VERSION ""

NS_ :

BS_:

BU_:

BO_ 70 AutoBrkSysMnPriInfo1_Prtctd_PDU: 20 Vector__XXX
 SG_ ABSMPI1P_MAC : 7|32@0+ (1,0) [0|4.29497e+009] "" ADIMa,ADIMb,ECP_E
 SG_ ABSMPI1P_FCnt : 39|5@0+ (1,0) [0|31] "" ADIMa,ADIMb,ECP_E
 SG_ ABSMPI1P_BrkModStsAuth : 41|2@0+ (1,0) [0|3] "" ADIMa,ADIMb,ECP_E
 SG_ ABSMPI1P_FillerExtnd : 42|1@0+ (1,0) [0|1] "" ADIMa,ADIMb,ECP_E
 SG_ ABSMPI1P_ADIMCmdMsgStsAuth : 45|3@0+ (1,0) [0|4] "" ADIMa,ADIMb,ECP_E
 SG_ ABSMPI1P_ABSStsAuth : 47|2@0+ (1,0) [0|3] "" ADIMa,ADIMb,ECP_E
 SG_ ABSMPI1P_DiagBrkPresReqStsAuth : 49|3@0+ (1,0) [0|4] "" ADIMa,ADIMb,ECP_E
 SG_ ABSMPI1P_DiagBrkPresReqAvalAuth : 51|2@0+ (1,0) [0|2] "" ADIMa,ADIMb,ECP_E
 SG_ ABSMPI1P_BrkTrqSfcntStndstlAuth : 52|1@0+ (1,0) [0|1] "" ADIMa,ADIMb,VICM,ECP_E
 SG_ ABSMPI1P_BrkSysStsAuth : 55|3@0+ (1,0) [0|6] "" ADIMa,ADIMb,ECP_E
 SG_ ABSMPI1P_EstdSrfcFCoefCapAuth : 58|8@0+ (0.006,0) [0|1.53] "Mu" ADIMa,ADIMb,ECP_E
 SG_ ABSMPI1P_ElecBrkDstSysStsAuth : 60|2@0+ (1,0) [0|3] "" ADIMa,ADIMb,ECP_E
 SG_ ABSMPI1P_ESCSysStsAuth : 62|2@0+ (1,0) [0|3] "" ADIMa,ADIMb,ECP_E
 SG_ ABSMPI1P_MxAvlBrkTqAuth : 64|14@0+ (2,-32766) [-32766|0] "Nm" ADIMa,ADIMb,ECP_E
 SG_ ABSMPI1P_EstdSrfcFCoefTypAuth : 66|2@0+ (1,0) [0|3] "" ADIMa,ADIMb,ECP_E
 SG_ ABSMPI1P_MxAvlBrkTqGradAuth : 82|12@0+ (100,-409500) [-409500|0] "Nm/s" ADIMa,ADIMb,ECP_E
 SG_ ABSMPI1P_PBMSbsysStsPriAuth : 98|3@0+ (1,0) [0|6] "" ADIMa,ADIMb,ECP_E
 SG_ ABSMPI1P_PBMArbtrtnStsPriAuth : 102|4@0+ (1,0) [0|10] "" ADIMa,ADIMb,ECP_E
 SG_ ABSMPI1P_WhlBrkPresAuth_Inv : 104|1@0+ (1,0) [0|1] "" ADIMa,ADIMb,ECP_E
 SG_ ABSMPI1P_TCSStsAuth : 106|2@0+ (1,0) [0|3] "" ADIMa,ADIMb,ECP_E
 SG_ ABSMPI1P_StndstlHldReqStsAuth : 108|2@0+ (1,0) [0|2] "" ADIMa,ADIMb,ECP_E
 SG_ ABSMPI1P_SpltFCoefCtlAuth : 110|2@0+ (1,0) [0|2] "" ADIMa,ADIMb,ECP_E
 SG_ ABSMPI1P_SBMFltDtdByPBMPriAuth : 111|1@0+ (1,0) [0|1] "" ADIMa,ADIMb,ECP_E
 SG_ ABSMPI1P_WhlBrkPresLFAuth : 119|8@0+ (100,0) [0|25500] "kPa" ADIMa,ADIMb,ECP_E
 SG_ ABSMPI1P_WhlBrkPresLRAuth : 127|8@0+ (100,0) [0|25500] "kPa" ADIMa,ADIMb,ECP_E
 SG_ ABSMPI1P_WhlBrkPresRFAuth : 135|8@0+ (100,0) [0|25500] "kPa" ADIMa,ADIMb,ECP_E
 SG_ ABSMPI1P_WhlBrkPresRRAuth : 143|8@0+ (100,0) [0|25500] "kPa" ADIMa,ADIMb,ECP_E
 SG_ ABSMPI1P_Filler : 146|11@0+ (1,0) [0|2047] "" ADIMa,ADIMb,ECP_E
 SG_ MnElecPrkBrkSwStsPriAuth : 149|3@0+ (1,0) [0|5] "" ADIMa,ADIMb,ECP_E
 SG_ ABSMPI1P_ARC : 151|2@0+ (1,0) [0|3] "" ADIMa,ADIMb,ECP_E

BO_ 699 AutoBrkSysRedntPriInfo1_PCSM_PDU: 8 Vector__XXX
 SG_ AutoBrkSysRedntPriInfo1_PCSM : 7|64@0+ (1,0) [0|1.84467e+019] "" EBCM,ECP_E

BO_ 78 AutoBrkSysRedntPriInfo1_Prtctd_P: 48 Vector__XXX
 SG_ ABSRPI1P_MAC : 7|32@0+ (1,0) [0|4.29497e+009] "" EBCM,ECP_E
 SG_ ABSRPI1P_FCnt : 39|5@0+ (1,0) [0|31] "" EBCM,ECP_E
 SG_ ABSRPI1P_BrkModStsAuth : 41|2@0+ (1,0) [0|3] "" EBCM,ECP_E
 SG_ ABSRPI1P_FillerExtnd3 : 42|1@0+ (1,0) [0|1] "" EBCM,ECP_E
 SG_ ABSRPI1P_ADIMCmdMsgStsAuth : 45|3@0+ (1,0) [0|4] "" EBCM,ECP_E
 SG_ ABSRPI1P_ABSStsAuth : 47|2@0+ (1,0) [0|3] "" EBCM,ECP_E
 SG_ ABSRPI1P_CSImmedATRqValAuth : 50|15@0+ (2,-22534) [-22534|43000] "Nm" EBCM,ECP_E
 SG_ ABSRPI1P_BrkTrqSfcntStndstlAuth : 51|1@0+ (1,0) [0|1] "" EBCM,ECP_E
 SG_ ABSRPI1P_BrkSysStsAuth : 54|3@0+ (1,0) [0|6] "" EBCM,ECP_E
 SG_ ABSRPI1P_BrkSysBrkLgtsReqdAuth : 55|1@0+ (1,0) [0|1] "" EBCM,ECP_E
 SG_ ABSRPI1P_CSPrdtdATRqValAuth : 65|15@0+ (2,-22534) [-22534|43000] "Nm" EBCM,ECP_E
 SG_ ABSRPI1P_CSPrdtdATRqIntvTypAuth : 67|2@0+ (1,0) [0|3] "" EBCM,ECP_E
 SG_ ABSRPI1P_ChsSysATRqFncAuth : 82|4@0+ (1,0) [0|14] "" EBCM,ECP_E
 SG_ ABSRPI1P_ChsSysBrkBlndATRqAuth : 91|12@0+ (2,0) [0|8190] "Nm" EBCM,ECP_E
 SG_ ABSRPI1P_ChsSysATRqRespTypAuth : 94|3@0+ (1,0) [0|4] "" EBCM,ECP_E
 SG_ ABSRPI1P_ChsSysTtBrkATAuth : 111|14@0+ (2,0) [0|32766] "Nm" EBCM,ECP_E
 SG_ ABSRPI1P_DrvIntdTtBrkTqAuth : 112|14@0+ (2,0) [0|32766] "Nm" EBCM,ECP_E
 SG_ ABSRPI1P_ChsSysTtBrkATAuth_Inv : 113|1@0+ (1,0) [0|1] "" EBCM,ECP_E
 SG_ ABSRPI1P_ElcBrkDstSysStsAuth : 128|2@0+ (1,0) [0|3] "" EBCM,ECP_E
 SG_ ABSRPI1P_ESCSysStsAuth : 130|2@0+ (1,0) [0|3] "" EBCM,ECP_E
 SG_ ABSRPI1P_EstdSrfcFCoefCapAuth : 142|8@0+ (0.006,0) [0|1.53] "Mu" EBCM,ECP_E
 SG_ ABSRPI1P_MxAvlBrkTqAuth : 148|14@0+ (2,-32766) [-32766|0] "Nm" EBCM,ECP_E
 SG_ ABSRPI1P_EstdSrfcFCoefTypAuth : 150|2@0+ (1,0) [0|3] "" EBCM,ECP_E
 SG_ ABSRPI1P_MxAvlBrkTqGradAuth : 166|12@0+ (100,-409500) [-409500|0] "Nm/s" EBCM,ECP_E
 SG_ ABSRPI1P_SBMArbtrtnStsPriAuth : 169|4@0+ (1,0) [0|8] "" EBCM,ECP_E
 SG_ ABSRPI1P_PBMFltDtdBySBMPriAuth : 170|1@0+ (1,0) [0|1] "" EBCM,ECP_E
 SG_ ABSRPI1P_StndstlHldRqStsAuth : 176|2@0+ (1,0) [0|2] "" EBCM,ECP_E
 SG_ ABSRPI1P_SpltFCoefCtlAuth : 178|2@0+ (1,0) [0|2] "" EBCM,ECP_E
 SG_ ABSRPI1P_SBMSbsysStsPriAuth : 181|3@0+ (1,0) [0|5] "" EBCM,ECP_E
 SG_ ABSRPI1P_WhlAnglrVelLFAuth : 188|14@0+ (0.004,0) [0|65.532] "Revolutions Per Second" EBCM,ECP_E
 SG_ ABSRPI1P_TCSStsAuth : 190|2@0+ (1,0) [0|3] "" EBCM,ECP_E
 SG_ ABSRPI1P_WhlAnglrVelLRAuth : 205|14@0+ (0.004,0) [0|65.532] "Revolutions Per Second" EBCM,ECP_E
 SG_ ABSRPI1P_WhlAnglrVelLFAuth_Inv : 206|1@0+ (1,0) [0|1] "" EBCM,ECP_E
 SG_ ABSRPI1P_WhlAnglrVelRFAuth : 222|14@0+ (0.004,0) [0|65.532] "Revolutions Per Second" EBCM,ECP_E
 SG_ ABSRPI1P_WhlAnglrVelLRAuth_Inv : 223|1@0+ (1,0) [0|1] "" EBCM,ECP_E
 SG_ ABSRPI1P_WhlAnglrVelRFAuth_Inv : 224|1@0+ (1,0) [0|1] "" EBCM,ECP_E
 SG_ ABSRPI1P_WhlAnglrVelRRAuth : 239|14@0+ (0.004,0) [0|65.532] "Revolutions Per Second" EBCM,ECP_E
 SG_ ABSRPI1P_WhlBrkPrsLFAuth : 240|8@0+ (100,0) [0|25500] "kPa" EBCM,ECP_E
 SG_ ABSRPI1P_WhlAnglrVelRRAuth_Inv : 241|1@0+ (1,0) [0|1] "" EBCM,ECP_E
 SG_ ABSRPI1P_WhlBrkPrsLFAuth_Inv : 248|1@0+ (1,0) [0|1] "" EBCM,ECP_E
 SG_ ABSRPI1P_WhlBrkPrsLRAuth : 263|8@0+ (100,0) [0|25500] "kPa" EBCM,ECP_E
 SG_ ABSRPI1P_WhlBrkPrsRFAuth : 270|8@0+ (100,0) [0|25500] "kPa" EBCM,ECP_E
 SG_ ABSRPI1P_WhlBrkPrsLRAuth_Inv : 271|1@0+ (1,0) [0|1] "" EBCM,ECP_E
 SG_ ABSRPI1P_WhlBrkPrsRRAuth : 277|8@0+ (100,0) [0|25500] "kPa" EBCM,ECP_E
 SG_ ABSRPI1P_WhlBrkPrsRFAuth_Inv : 278|1@0+ (1,0) [0|1] "" EBCM,ECP_E
 SG_ ABSRPI1P_Filler : 282|32@0+ (1,0) [0|4.29497e+009] "" EBCM,ECP_E
 SG_ ABSRPI1P_ARC : 284|2@0+ (1,0) [0|3] "" EBCM,ECP_E
 SG_ ABSRPI1P_WhlBrkPrsRRAuth_Inv : 285|1@0+ (1,0) [0|1] "" EBCM,ECP_E
 SG_ ABSRPI1P_FillerExtnd : 314|32@0+ (1,0) [0|4.29497e+009] "0" EBCM,ECP_E
 SG_ ABSRPI1P_FillerExtnd1 : 346|32@0+ (1,0) [0|4.29497e+009] "" EBCM,ECP_E
 SG_ ABSRPI1P_FillerExtnd2 : 378|3@0+ (1,0) [0|7] "" EBCM,ECP_E

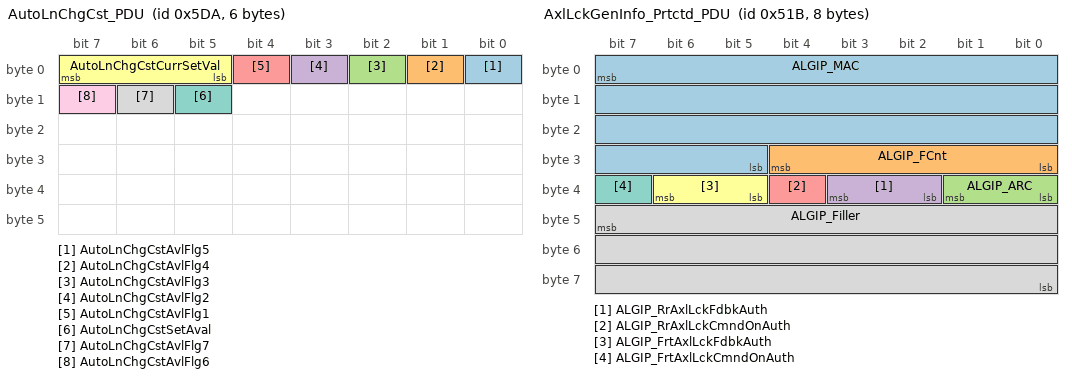
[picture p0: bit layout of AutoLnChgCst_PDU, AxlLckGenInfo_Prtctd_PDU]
BO_ 1498 AutoLnChgCst_PDU: 6 Vector__XXX
 SG_ AutoLnChgCstAvlFlg5 : 0|1@0+ (1,0) [0|1] "" CGM
 SG_ AutoLnChgCstAvlFlg4 : 1|1@0+ (1,0) [0|1] "" CGM
 SG_ AutoLnChgCstAvlFlg3 : 2|1@0+ (1,0) [0|1] "" CGM
 SG_ AutoLnChgCstAvlFlg2 : 3|1@0+ (1,0) [0|1] "" CGM
 SG_ AutoLnChgCstAvlFlg1 : 4|1@0+ (1,0) [0|1] "" CGM
 SG_ AutoLnChgCstCurrSetVal : 7|3@0+ (1,0) [0|4] "" CGM
 SG_ AutoLnChgCstSetAval : 13|1@0+ (1,0) [0|1] "" CGM
 SG_ AutoLnChgCstAvlFlg7 : 14|1@0+ (1,0) [0|1] "" CGM
 SG_ AutoLnChgCstAvlFlg6 : 15|1@0+ (1,0) [0|1] "" CGM

BO_ 698 AutoVehMtnCtlMnInfo1_PCSM_PDU: 8 Vector__XXX
 SG_ AutoVehMtnCtlMnInfo1_PCSM : 7|64@0+ (1,0) [0|1.84467e+019] "" VICM,EBCM,EPSRAa,FOPM,ECP_E

BO_ 68 AutoVehMtnCtlMnInfo1_Prtctd_PDU: 24 Vector__XXX
 SG_ AVMCMI1P_MAC : 7|32@0+ (1,0) [0|4.29497e+009] "" VICM,CGM,EBCM,EPSRAa,FOPM,ECP_E
 SG_ AVMCMI1P_FCnt : 39|5@0+ (1,0) [0|31] "" VICM,CGM,EBCM,EPSRAa,FOPM,ECP_E
 SG_ AVMCMI1P_AutoCtlBrkTqRqAuth : 46|15@0+ (1,-32767) [-32767|0] "Nm" VICM,CGM,EBCM,EPSRAa,FOPM,ECP_E
 SG_ AVMCMI1P_ADSRedntIPSPwrdOnAuth : 47|1@0+ (1,0) [0|1] "" VICM,CGM,EBCM,EPSRAa,FOPM,ECP_E
 SG_ AVMCMI1P_AutoCtlRqAngVlAuth : 63|15@0- (0.0625,0) [-1024|1023.94] "deg" VICM,CGM,EBCM,EPSRAa,FOPM,ECP_E
 SG_ AVMCMI1P_AutoCtlRqStrgModeAuth : 64|1@0+ (1,0) [0|1] "" VICM,CGM,EBCM,EPSRAa,FOPM,ECP_E
 SG_ AVMCMI1P_AutoVehOprtlStatAuth : 72|4@0+ (1,0) [0|7] "" VICM,CGM,EBCM,EPSRAa,FOPM,ECP_E
 SG_ AVMCMI1P_AutoTransRngRqAuth : 75|3@0+ (1,0) [0|4] "" VICM,CGM,EBCM,EPSRAa,FOPM,ECP_E
 SG_ AVMCMI1P_AutoCtlrEPBRqAuth : 77|2@0+ (1,0) [0|2] "" VICM,CGM,EBCM,EPSRAa,FOPM,ECP_E
 SG_ AVMCMI1P_AutoCtlrBrkTqRqTypAuth : 79|2@0+ (1,0) [0|2] "" VICM,CGM,EBCM,EPSRAa,FOPM,ECP_E
 SG_ AVMCMI1P_DgWhlBrkPrsRqLFAuth : 84|11@0+ (10,0) [0|20470] "kPa" VICM,CGM,EBCM,EPSRAa,FOPM,ECP_E
 SG_ AVMCMI1P_DgWhlBrkPrsRqLRAuth : 89|11@0+ (10,0) [0|20470] "kPa" VICM,CGM,EBCM,EPSRAa,FOPM,ECP_E
 SG_ AVMCMI1P_DgWhlBrkPrsRqRFAuth : 110|11@0+ (10,0) [0|20470] "kPa" VICM,CGM,EBCM,EPSRAa,FOPM,ECP_E
 SG_ AVMCMI1P_DgWhlBrkPrsRqRRAuth : 115|11@0+ (10,0) [0|20470] "kPa" VICM,CGM,EBCM,EPSRAa,FOPM,ECP_E
 SG_ AVMCMI1P_DgWhlBrkPrsRqTgtAuth : 120|2@0+ (1,0) [0|2] "" VICM,CGM,EBCM,EPSRAa,FOPM,ECP_E
 SG_ AVMCMI1P_MnAutoAxlTrqRqAuth : 131|15@0+ (2,-22534) [-22534|43000] "Nm" VICM,CGM,EBCM,EPSRAa,FOPM,ECP_E
 SG_ AVMCMI1P_FailOprtlPwrAvSTRqAuth : 134|3@0+ (1,0) [0|3] "" VICM,CGM,EBCM,EPSRAa,FOPM,ECP_E
 SG_ AVMCMI1P_Filler : 144|32@0+ (1,0) [0|4.29497e+009] "" VICM,CGM,EBCM,EPSRAa,FOPM,ECP_E
 SG_ AVMCMnFAXVCEqpdStsPriAuth : 146|2@0+ (1,0) [0|3] "" VICM,CGM,EBCM,EPSRAa,FOPM,ECP_E
 SG_ AVMCMI1P_ARC : 148|2@0+ (1,0) [0|3] "" VICM,CGM,EBCM,EPSRAa,FOPM,ECP_E
 SG_ AVMCMI1P_FillerExtnd : 176|9@0+ (1,0) [0|511] "" VICM,CGM,EBCM,EPSRAa,FOPM,ECP_E

BO_ 1367 AxlLckGenInfo_PCSM_PDU: 8 Vector__XXX
 SG_ AxlLckGenInfo_PCSM : 7|64@0+ (1,0) [0|1.84467e+019] "" ECP_E

BO_ 1307 AxlLckGenInfo_Prtctd_PDU: 8 Vector__XXX
 SG_ ALGIP_MAC : 7|27@0+ (1,0) [0|1.34218e+008] "" ECP_E
 SG_ ALGIP_FCnt : 28|5@0+ (1,0) [0|31] "" ECP_E
 SG_ ALGIP_ARC : 33|2@0+ (1,0) [0|3] "" ECP_E
 SG_ ALGIP_RrAxlLckFdbkAuth : 35|2@0+ (1,0) [0|2] "" TCCM,ECP_E
 SG_ ALGIP_RrAxlLckCmndOnAuth : 36|1@0+ (1,0) [0|1] "" TCCM,ECP_E
 SG_ ALGIP_FrtAxlLckFdbkAuth : 38|2@0+ (1,0) [0|2] "" TCCM,ECP_E
 SG_ ALGIP_FrtAxlLckCmndOnAuth : 39|1@0+ (1,0) [0|1] "" TCCM,ECP_E
 SG_ ALGIP_Filler : 47|24@0+ (1,0) [0|1.67772e+007] "" ECP_E

BO_ 2147745799 Message0034_PDU: 1 Vector__XXX
 SG_ Sig0522 : 7|1@0+ (1,0) [0|1] "" CGM

BO_ 1255 Message0035_PDU: 6 Vector__XXX
 SG_ Sig3627 : 7|8@0+ (0.392157,0) [0|100] "" ECM,PCM

BO_ 2147745812 Message0037_PDU: 1 Vector__XXX
 SG_ Sig0524 : 7|1@0+ (1,0) [0|1] "" CGM

BO_ 459 BSM_NM_PDU_On_CAN_2_Cluster: 8 Vector__XXX
 SG_ ISignal_BSM_CAN_2_Cluster : 23|48@0+ (1,0) [0|281474976710655] "" ACP2_MCU,ADIMa,ADIMb,AHL_AFL,AHS,ARS,VECM,VICM,BSM_MH,CGM,DCM,DMS,EBCM,ECM,ECP_MC,EOCM,EOCM_HC_Superset,EPSRAa,EPS,EPSb,FCM,FOPM,HUD_CAN,LIB1,NVM,E44,PCM,RDCM,TCCM,TCM,VDM,ECP_E,ECP_S,ECP_S2,ECP_X1

BO_ 923 BdyGenInfo3_PCSM_PDU: 8 Vector__XXX
 SG_ BdyGenInfo3_PCSM : 7|64@0+ (1,0) [0|1.84467e+019] "" ACP2_MCU,ECM,EOCM,EOCM_HC_Superset,EPS,EPSb,FCM,PCM,RDCM,TCCM

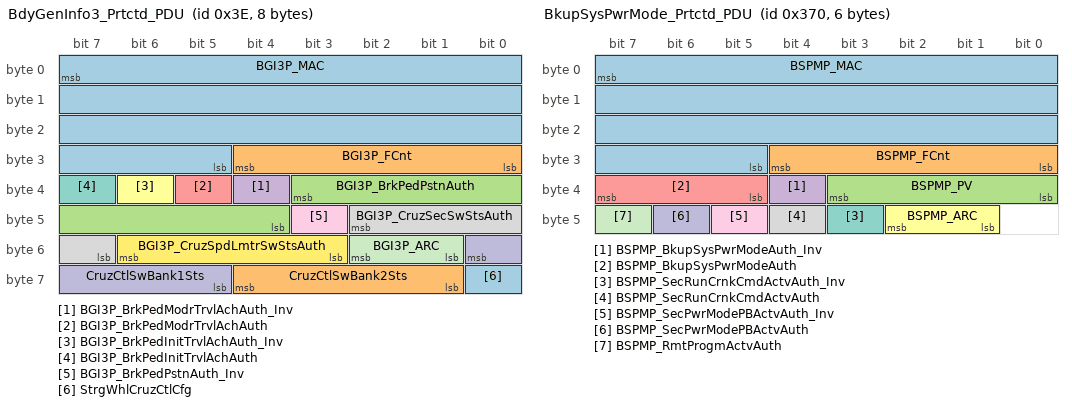
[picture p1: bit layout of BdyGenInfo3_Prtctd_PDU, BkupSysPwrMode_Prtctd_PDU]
BO_ 62 BdyGenInfo3_Prtctd_PDU: 8 Vector__XXX
 SG_ BGI3P_MAC : 7|27@0+ (1,0) [0|1.34218e+008] "" ACP2_MCU,ECM,EOCM,EOCM_HC_Superset,EPS,EPSb,FCM,PCM,RDCM,TCCM
 SG_ BGI3P_FCnt : 28|5@0+ (1,0) [0|31] "" ACP2_MCU,ECM,EOCM,EOCM_HC_Superset,EPS,EPSb,FCM,PCM,RDCM,TCCM
 SG_ BGI3P_BrkPedPstnAuth : 35|8@0+ (0.392157,0) [0|100] "%" ACP2_MCU,ADIMa,ADIMb,AHL_AFL,EBCM,ECM,EOCM,EOCM_HC_Superset,EPS,EPSb,FCM,E44,PCM,RDCM,TCCM,TCM
 SG_ BGI3P_BrkPedModrTrvlAchAuth_Inv : 36|1@0+ (1,0) [0|1] "" ACP2_MCU,ECM,EOCM,EOCM_HC_Superset,EPS,EPSb,FCM,PCM,RDCM,TCCM,TCM
 SG_ BGI3P_BrkPedModrTrvlAchAuth : 37|1@0+ (1,0) [0|1] "" ACP2_MCU,ECM,EOCM,EOCM_HC_Superset,EPS,EPSb,FCM,PCM,RDCM,TCCM,TCM
 SG_ BGI3P_BrkPedInitTrvlAchAuth_Inv : 38|1@0+ (1,0) [0|1] "" ACP2_MCU,BSM,DCM,EBCM,ECM,EOCM,EOCM_HC_Superset,EPS,EPSb,FCM,PCM,RDCM,TCCM,TCM
 SG_ BGI3P_BrkPedInitTrvlAchAuth : 39|1@0+ (1,0) [0|1] "" ACP2_MCU,BSM,EBCM,ECM,EOCM,EOCM_HC_Superset,EPS,EPSb,FCM,PCM,RDCM,TCCM,TCM
 SG_ BGI3P_CruzSecSwStsAuth : 42|4@0+ (1,0) [0|9] "" ACP2_MCU,ECM,EOCM,EOCM_HC_Superset,EPS,EPSb,FCM,PCM,RDCM,TCCM
 SG_ BGI3P_BrkPedPstnAuth_Inv : 43|1@0+ (1,0) [0|1] "" ACP2_MCU,ADIMa,ADIMb,AHL_AFL,EBCM,ECM,EOCM,EOCM_HC_Superset,EPS,EPSb,FCM,E44,PCM,RDCM,TCCM,TCM
 SG_ CruzCtlSwBank1Sts : 48|4@0+ (1,0) [0|9] "" ACP2_MCU,EBCM,ECM,EOCM,EOCM_HC_Superset,EPS,EPSb,FCM,PCM,RDCM,TCCM
 SG_ BGI3P_ARC : 50|2@0+ (1,0) [0|3] "" ACP2_MCU,ECM,EOCM,EOCM_HC_Superset,EPS,EPSb,FCM,PCM,RDCM,TCCM
 SG_ BGI3P_CruzSpdLmtrSwStsAuth : 54|4@0+ (1,0) [0|9] "" ACP2_MCU,EBCM,ECM,EOCM,EOCM_HC_Superset,EPS,EPSb,FCM,PCM,RDCM,TCCM
 SG_ StrgWhlCruzCtlCfg : 56|1@0+ (1,0) [0|1] "" ACP2_MCU,EBCM,ECM,EOCM,EOCM_HC_Superset,EPS,EPSb,FCM,PCM,RDCM,TCCM
 SG_ CruzCtlSwBank2Sts : 60|4@0+ (1,0) [0|10] "" ACP2_MCU,ECM,EOCM,EOCM_HC_Superset,EPS,EPSb,FCM,PCM,RDCM,TCCM

BO_ 1405 BkupSysPwrMode_PCSM_PDU: 8 Vector__XXX
 SG_ BkupSysPwrMode_PCSM : 7|64@0+ (1,0) [0|1.84467e+019] "" ADIMa,AHL_AFL,AHS,ARS,VECM,VICM,BSM_MH,DCM,DMS,ECP_MC,EPSRAa,EPS,EPSb,FCM,LIB1,PCM,RDCM,TCCM,TCM,ECP_E,ECP_S,ECP_S2

BO_ 880 BkupSysPwrMode_Prtctd_PDU: 6 Vector__XXX
 SG_ BSPMP_MAC : 7|27@0+ (1,0) [0|1.34218e+008] "" ADIMa,AHL_AFL,AHS,ARS,VECM,VICM,BSM_MH,DCM,DMS,ECP_MC,EPSRAa,EPS,EPSb,FCM,LIB1,PCM,RDCM,TCCM,TCM,ECP_E,ECP_S,ECP_S2
 SG_ BSPMP_FCnt : 28|5@0+ (1,0) [0|31] "" ADIMa,AHL_AFL,AHS,ARS,VECM,VICM,BSM_MH,DCM,DMS,ECP_MC,EPSRAa,EPS,EPSb,FCM,LIB1,PCM,RDCM,TCCM,TCM,ECP_E,ECP_S,ECP_S2
 SG_ BSPMP_PV : 35|4@0+ (1,0) [0|15] "" ADIMa,AHL_AFL,AHS,ARS,VECM,VICM,BSM_MH,DCM,DMS,ECP_MC,EPSRAa,EPS,EPSb,FCM,HUD_CAN,LIB1,NVM,PCM,RDCM,TCCM,TCM,ECP_E,ECP_S,ECP_S2
 SG_ BSPMP_BkupSysPwrModeAuth_Inv : 36|1@0+ (1,0) [0|1] "" ADIMa,AHL_AFL,AHS,ARS,VECM,VICM,BSM_MH,DCM,DMS,ECP_MC,EPSRAa,EPS,EPSb,FCM,HUD_CAN,LIB1,NVM,PCM,RDCM,TCCM,TCM,VDM,ECP_E,ECP_S,ECP_S2
 SG_ BSPMP_BkupSysPwrModeAuth : 39|3@0+ (1,0) [0|4] "" ADIMa,AHL_AFL,AHS,ARS,VECM,VICM,BSM_MH,DCM,DMS,ECP_MC,EPSRAa,EPS,EPSb,FCM,HUD_CAN,LIB1,NVM,PCM,RDCM,TCCM,TCM,VDM,ECP_E,ECP_S,ECP_S2
 SG_ BSPMP_ARC : 42|2@0+ (1,0) [0|3] "" ADIMa,AHL_AFL,AHS,ARS,VECM,VICM,BSM_MH,DCM,DMS,ECP_MC,EPSRAa,EPS,EPSb,FCM,HUD_CAN,LIB1,NVM,PCM,RDCM,TCCM,TCM,VDM,ECP_E,ECP_S,ECP_S2
 SG_ BSPMP_SecRunCrnkCmdActvAuth_Inv : 43|1@0+ (1,0) [0|1] "" ADIMa,AHL_AFL,AHS,ARS,VECM,VICM,BSM_MH,DCM,DMS,ECP_MC,EPSRAa,EPS,EPSb,FCM,LIB1,PCM,RDCM,TCCM,TCM,VDM,ECP_E,ECP_S,ECP_S2
 SG_ BSPMP_SecRunCrnkCmdActvAuth : 44|1@0+ (1,0) [0|1] "" ADIMa,AHL_AFL,AHS,ARS,VECM,VICM,BSM_MH,DCM,DMS,ECP_MC,EPSRAa,EPS,EPSb,FCM,LIB1,PCM,RDCM,TCCM,TCM,VDM,ECP_E,ECP_S,ECP_S2
 SG_ BSPMP_SecPwrModePBActvAuth_Inv : 45|1@0+ (1,0) [0|1] "" ADIMa,AHL_AFL,AHS,ARS,VECM,VICM,BSM_MH,DCM,DMS,ECP_MC,EPSRAa,EPS,EPSb,FCM,LIB1,PCM,RDCM,TCCM,TCM,ECP_E,ECP_S,ECP_S2
 SG_ BSPMP_SecPwrModePBActvAuth : 46|1@0+ (1,0) [0|1] "" ADIMa,AHL_AFL,AHS,ARS,VECM,VICM,BSM_MH,DCM,DMS,ECP_MC,EPSRAa,EPS,EPSb,FCM,LIB1,PCM,RDCM,TCCM,TCM,ECP_E,ECP_S,ECP_S2
 SG_ BSPMP_RmtProgmActvAuth : 47|1@0+ (1,0) [0|1] "" ADIMa,AHL_AFL,AHS,ARS,VECM,VICM,BSM_MH,DCM,DMS,ECP_MC,EPSRAa,EPS,EPSb,FCM,HUD_CAN,LIB1,NVM,PCM,RDCM,TCCM,TCM,VDM,ECP_E,ECP_S,ECP_S2

BO_ 1391 Message0038_PDU: 8 Vector__XXX
 SG_ Sig0529 : 7|64@0+ (1,0) [0|1.84467e+019] "" ECM,PCM

BO_ 1301 Message0039_PDU: 7 Vector__XXX
 SG_ Sig0477 : 7|27@0+ (1,0) [0|1.34218e+008] "" ECM,PCM
 SG_ Sig0476 : 28|5@0+ (1,0) [0|31] "" ECM,PCM
 SG_ Sig0478 : 39|8@0+ (1,-40) [-40|215] "deg/C" ECM,PCM
 SG_ Sig0480 : 46|8@0+ (1,-40) [-40|215] "deg/C" ECM,PCM
 SG_ Sig0479 : 47|1@0+ (1,0) [0|1] "" ECM,PCM
 SG_ Sig0475 : 53|2@0+ (1,0) [0|3] "" ECM,PCM
 SG_ Sig0481 : 54|1@0+ (1,0) [0|1] "" ECM,PCM

BO_ 922 Message0040_PDU: 8 Vector__XXX
 SG_ Sig0530 : 7|64@0+ (1,0) [0|1.84467e+019] "" ECM,PCM

BO_ 108 Message0041_PDU: 12 Vector__XXX
 SG_ Sig0484 : 7|32@0+ (1,0) [0|4.29497e+009] "" ECM,PCM
 SG_ Sig0483 : 39|5@0+ (1,0) [0|31] "" ECM,PCM
 SG_ Sig0486 : 45|16@0- (1,0) [-32768|32767] "RPM" ECM,PCM
 SG_ Sig0485 : 47|2@0+ (1,0) [0|3] "" ECM,PCM
 SG_ Sig0488 : 60|13@0- (0.125,0) [-512|511.875] "Nm" ECM,PCM
 SG_ Sig0487 : 61|1@0+ (1,0) [0|1] "" ECM,PCM
 SG_ Sig0482 : 78|2@0+ (1,0) [0|3] "" ECM,PCM
 SG_ Sig0489 : 79|1@0+ (1,0) [0|1] "" ECM,PCM

BO_ 921 Message0042_PDU: 8 Vector__XXX
 SG_ Sig0531 : 7|64@0+ (1,0) [0|1.84467e+019] "" ECP_MC

BO_ 98 Message0043_PDU: 16 Vector__XXX
 SG_ Sig0493 : 7|32@0+ (1,0) [0|4.29497e+009] "" ECP_MC
 SG_ Sig0491 : 39|5@0+ (1,0) [0|31] "" ECP_MC
 SG_ Sig0494 : 47|13@0- (0.125,0) [-512|511.875] "Nm" ECP_MC
 SG_ Sig0495 : 50|13@0- (0.125,0) [-512|511.875] "Nm" ECP_MC
 SG_ Sig0497 : 67|8@0+ (0.5,0) [0|127.5] "v" ECP_MC
 SG_ Sig0496 : 69|2@0+ (1,0) [0|1] "" ECP_MC
 SG_ Sig0498 : 75|4@0+ (1,0) [0|5] "" ECP_MC
 SG_ Sig0499 : 87|8@0+ (0.5,0) [0|127.5] "v" ECP_MC
 SG_ Sig0500 : 95|8@0+ (0.5,0) [0|127.5] "v" ECP_MC
 SG_ Sig0492 : 101|30@0+ (1,0) [0|1.07374e+009] "" ECP_MC
 SG_ Sig0490 : 103|2@0+ (1,0) [0|3] "" ECP_MC

BO_ 691 BrkSysInfoSts2_PCSM_PDU: 8 Vector__XXX
 SG_ BrkSysInfoSts2_PCSM : 7|64@0+ (1,0) [0|1.84467e+019] "" ACP2_MCU,AHS,ARS,DCM,ECM,EOCM,EOCM_HC_Superset,EPS,EPSb,FCM,PCM,RDCM,TCCM,TCM,ECP_E

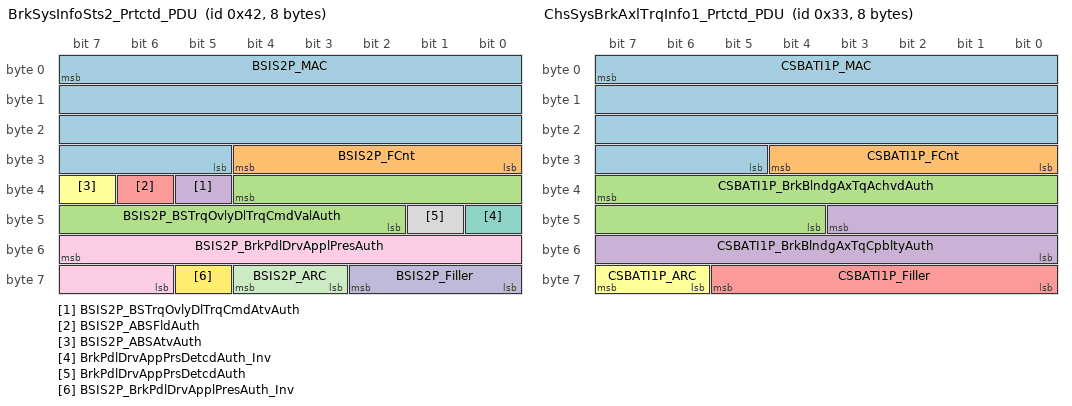
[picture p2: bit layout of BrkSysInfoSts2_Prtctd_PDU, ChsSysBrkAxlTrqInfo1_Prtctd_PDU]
BO_ 66 BrkSysInfoSts2_Prtctd_PDU: 8 Vector__XXX
 SG_ BSIS2P_MAC : 7|27@0+ (1,0) [0|1.34218e+008] "" ACP2_MCU,AHS,ARS,CGM,DCM,ECM,EOCM,EOCM_HC_Superset,EPS,EPSb,FCM,PCM,RDCM,TCCM,TCM,ECP_E
 SG_ BSIS2P_FCnt : 28|5@0+ (1,0) [0|31] "" ACP2_MCU,AHS,ARS,CGM,DCM,ECM,EOCM,EOCM_HC_Superset,EPS,EPSb,FCM,PCM,RDCM,TCCM,TCM,ECP_E
 SG_ BSIS2P_BSTrqOvlyDlTrqCmdValAuth : 36|11@0- (0.01,0) [-10.24|10.23] "Nm" ACP2_MCU,AHS,ARS,CGM,DCM,ECM,EOCM,EOCM_HC_Superset,EPS,EPSb,FCM,PCM,RDCM,TCCM,TCM,ECP_E
 SG_ BSIS2P_BSTrqOvlyDlTrqCmdAtvAuth : 37|1@0+ (1,0) [0|1] "" ACP2_MCU,AHS,ARS,CGM,DCM,ECM,EOCM,EOCM_HC_Superset,EPS,EPSb,FCM,PCM,RDCM,TCCM,TCM,ECP_E
 SG_ BSIS2P_ABSFldAuth : 38|1@0+ (1,0) [0|1] "" ACP2_MCU,ADIMa,ADIMb,AHS,ARS,CGM,DCM,ECM,EOCM,EOCM_HC_Superset,EPS,EPSb,FCM,PCM,RDCM,TCCM,TCM,VDM,ECP_E
 SG_ BSIS2P_ABSAtvAuth : 39|1@0+ (1,0) [0|1] "" ACP2_MCU,ADIMa,ADIMb,AHL_AFL,AHS,ARS,CGM,DCM,ECM,EOCM,EOCM_HC_Superset,EPS,EPSb,FCM,E44,PCM,RDCM,TCCM,TCM,ECP_E,ECP_X1
 SG_ BrkPdlDrvAppPrsDetcdAuth_Inv : 40|1@0+ (1,0) [0|1] "" ACP2_MCU,AHS,ARS,CGM,DCM,ECM,EOCM,EOCM_HC_Superset,EPS,EPSb,FCM,PCM,RDCM,TCCM,TCM,ECP_E
 SG_ BrkPdlDrvAppPrsDetcdAuth : 41|1@0+ (1,0) [0|1] "" ACP2_MCU,AHS,ARS,CGM,DCM,ECM,EOCM,EOCM_HC_Superset,EPS,EPSb,FCM,PCM,RDCM,TCCM,TCM,ECP_E
 SG_ BSIS2P_BrkPdlDrvApplPresAuth : 55|10@0+ (20,0) [0|20460] "kPa" ACP2_MCU,AHS,ARS,CGM,DCM,ECM,EOCM,EOCM_HC_Superset,EPS,EPSb,FCM,PCM,RDCM,TCCM,TCM,ECP_E
 SG_ BSIS2P_Filler : 58|3@0+ (1,0) [0|7] "" ACP2_MCU,AHS,ARS,CGM,DCM,ECM,EOCM,EOCM_HC_Superset,EPS,EPSb,FCM,PCM,RDCM,TCCM,TCM,ECP_E
 SG_ BSIS2P_ARC : 60|2@0+ (1,0) [0|3] "" ACP2_MCU,AHS,ARS,CGM,DCM,ECM,EOCM,EOCM_HC_Superset,EPS,EPSb,FCM,PCM,RDCM,TCCM,TCM,ECP_E
 SG_ BSIS2P_BrkPdlDrvApplPresAuth_Inv : 61|1@0+ (1,0) [0|1] "" ACP2_MCU,AHS,ARS,CGM,DCM,ECM,EOCM,EOCM_HC_Superset,EPS,EPSb,FCM,PCM,RDCM,TCCM,TCM,ECP_E

BO_ 327 CGM_NM_PDU_On_CAN_2_Cluster: 8 Vector__XXX
 SG_ ISignal_CGM_CAN_2_Cluster : 23|48@0+ (1,0) [0|281474976710655] "" ACP2_MCU,ADIMa,ADIMb,AHL_AFL,AHS,ARS,BSM,VECM,VICM,BSM_MH,DCM,DMS,EBCM,ECM,ECP_MC,EOCM,EOCM_HC_Superset,EPSRAa,EPS,EPSb,FCM,FOPM,HUD_CAN,LIB1,NVM,E44,PCM,RDCM,TCCM,TCM,VDM,ECP_E,ECP_S,ECP_S2,ECP_X1

BO_ 696 ChsSysBrkAxlTrqInfo1_PCSM_PDU: 8 Vector__XXX
 SG_ ChsSysBrkAxlTrqInfo1_PCSM : 7|64@0+ (1,0) [0|1.84467e+019] "" EBCM

BO_ 51 ChsSysBrkAxlTrqInfo1_Prtctd_PDU: 8 Vector__XXX
 SG_ CSBATI1P_MAC : 7|27@0+ (1,0) [0|1.34218e+008] "" EBCM
 SG_ CSBATI1P_FCnt : 28|5@0+ (1,0) [0|31] "" EBCM
 SG_ CSBATI1P_BrkBlndgAxTqAchvdAuth : 39|12@0+ (2,0) [0|8190] "Nm" EBCM,ECP_S,ECP_S2
 SG_ CSBATI1P_BrkBlndgAxTqCpbltyAuth : 43|12@0+ (2,0) [0|8190] "Nm" EBCM
 SG_ CSBATI1P_Filler : 61|6@0+ (1,0) [0|63] "" EBCM
 SG_ CSBATI1P_ARC : 63|2@0+ (1,0) [0|3] "" EBCM

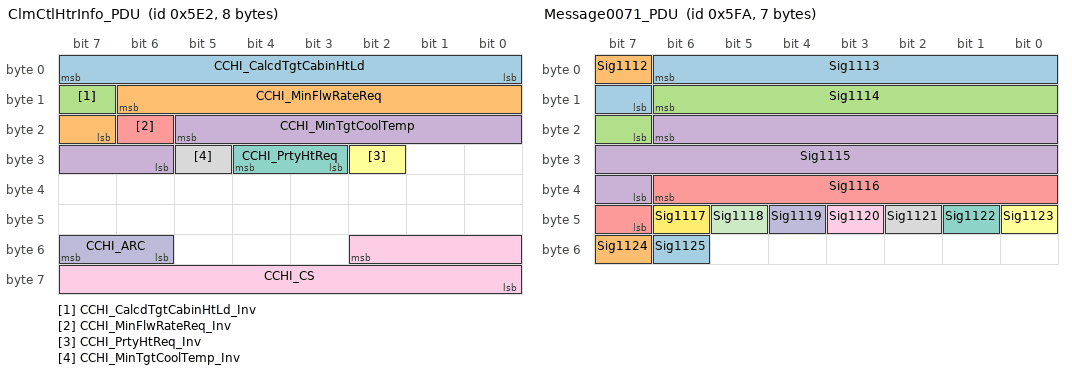
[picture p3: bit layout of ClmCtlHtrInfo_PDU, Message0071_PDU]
BO_ 1506 ClmCtlHtrInfo_PDU: 8 Vector__XXX
 SG_ CCHI_CalcdTgtCabinHtLd : 7|8@0+ (0.12549,0) [0|31.9999] "kW" ECM,PCM
 SG_ CCHI_MinFlwRateReq : 14|8@0+ (0.25098,0) [0|63.9999] "l/min" ECM,PCM
 SG_ CCHI_CalcdTgtCabinHtLd_Inv : 15|1@0+ (1,0) [0|1] "" ECM,PCM
 SG_ CCHI_MinTgtCoolTemp : 21|8@0+ (0.39216,0) [0|100.001] "degC" ECM,PCM
 SG_ CCHI_MinFlwRateReq_Inv : 22|1@0+ (1,0) [0|1] "" ECM,PCM
 SG_ CCHI_PrtyHtReq_Inv : 26|1@0+ (1,0) [0|1] "" ECM,PCM
 SG_ CCHI_PrtyHtReq : 28|2@0+ (1,0) [0|3] "" ECM,PCM
 SG_ CCHI_MinTgtCoolTemp_Inv : 29|1@0+ (1,0) [0|1] "" ECM,PCM
 SG_ CCHI_CS : 50|11@0+ (1,0) [0|2047] "" ECM,PCM
 SG_ CCHI_ARC : 55|2@0+ (1,0) [0|3] "" ECM,PCM

BO_ 2147745813 Message0052_PDU: 1 Vector__XXX
 SG_ Sig0715 : 7|1@0+ (1,0) [0|1] "" CGM

BO_ 2147745814 DMS_CAN2_ClscCANHrtBtActv_PDU: 1 Vector__XXX
 SG_ DMS_CAN2_ClscCANHrtBtActv : 7|1@0+ (1,0) [0|1] "" CGM

BO_ 1530 Message0071_PDU: 7 Vector__XXX
 SG_ Sig1113 : 6|8@0+ (1,0) [0|255] "" ADIMa,CGM
 SG_ Sig1112 : 7|1@0+ (1,0) [0|1] "" ADIMa,CGM
 SG_ Sig1114 : 14|8@0+ (1,0) [0|3] "" ADIMa,CGM
 SG_ Sig1115 : 22|16@0+ (1,0) [0|65535] "" ADIMa,CGM
 SG_ Sig1116 : 38|8@0+ (1,0) [0|255] "" ADIMa,CGM
 SG_ Sig1123 : 40|1@0+ (1,0) [0|1] "" ADIMa,CGM
 SG_ Sig1122 : 41|1@0+ (1,0) [0|1] "" ADIMa,CGM
 SG_ Sig1121 : 42|1@0+ (1,0) [0|1] "" ADIMa,CGM
 SG_ Sig1120 : 43|1@0+ (1,0) [0|1] "" ADIMa,CGM
 SG_ Sig1119 : 44|1@0+ (1,0) [0|1] "" ADIMa,CGM
 SG_ Sig1118 : 45|1@0+ (1,0) [0|1] "" ADIMa,CGM
 SG_ Sig1117 : 46|1@0+ (1,0) [0|1] "" ADIMa,CGM
 SG_ Sig1125 : 54|1@0+ (1,0) [0|1] "" ADIMa,CGM
 SG_ Sig1124 : 55|1@0+ (1,0) [0|1] "" ADIMa,CGM

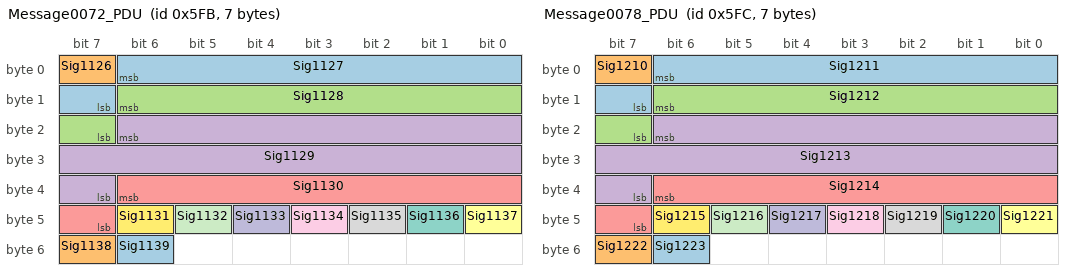
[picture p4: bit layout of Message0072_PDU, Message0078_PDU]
BO_ 1531 Message0072_PDU: 7 Vector__XXX
 SG_ Sig1127 : 6|8@0+ (1,0) [0|255] "" CGM
 SG_ Sig1126 : 7|1@0+ (1,0) [0|1] "" CGM
 SG_ Sig1128 : 14|8@0+ (1,0) [0|3] "" CGM
 SG_ Sig1129 : 22|16@0+ (1,0) [0|65535] "" CGM
 SG_ Sig1130 : 38|8@0+ (1,0) [0|255] "" CGM
 SG_ Sig1137 : 40|1@0+ (1,0) [0|1] "" CGM
 SG_ Sig1136 : 41|1@0+ (1,0) [0|1] "" CGM
 SG_ Sig1135 : 42|1@0+ (1,0) [0|1] "" CGM
 SG_ Sig1134 : 43|1@0+ (1,0) [0|1] "" CGM
 SG_ Sig1133 : 44|1@0+ (1,0) [0|1] "" CGM
 SG_ Sig1132 : 45|1@0+ (1,0) [0|1] "" CGM
 SG_ Sig1131 : 46|1@0+ (1,0) [0|1] "" CGM
 SG_ Sig1139 : 54|1@0+ (1,0) [0|1] "" CGM
 SG_ Sig1138 : 55|1@0+ (1,0) [0|1] "" CGM

BO_ 1532 Message0078_PDU: 7 Vector__XXX
 SG_ Sig1211 : 6|8@0+ (1,0) [0|255] "" CGM
 SG_ Sig1210 : 7|1@0+ (1,0) [0|1] "" CGM
 SG_ Sig1212 : 14|8@0+ (1,0) [0|3] "" CGM
 SG_ Sig1213 : 22|16@0+ (1,0) [0|65535] "" CGM
 SG_ Sig1214 : 38|8@0+ (1,0) [0|255] "" CGM
 SG_ Sig1221 : 40|1@0+ (1,0) [0|1] "" CGM
 SG_ Sig1220 : 41|1@0+ (1,0) [0|1] "" CGM
 SG_ Sig1219 : 42|1@0+ (1,0) [0|1] "" CGM
 SG_ Sig1218 : 43|1@0+ (1,0) [0|1] "" CGM
 SG_ Sig1217 : 44|1@0+ (1,0) [0|1] "" CGM
 SG_ Sig1216 : 45|1@0+ (1,0) [0|1] "" CGM
 SG_ Sig1215 : 46|1@0+ (1,0) [0|1] "" CGM
 SG_ Sig1223 : 54|1@0+ (1,0) [0|1] "" CGM
 SG_ Sig1222 : 55|1@0+ (1,0) [0|1] "" CGM

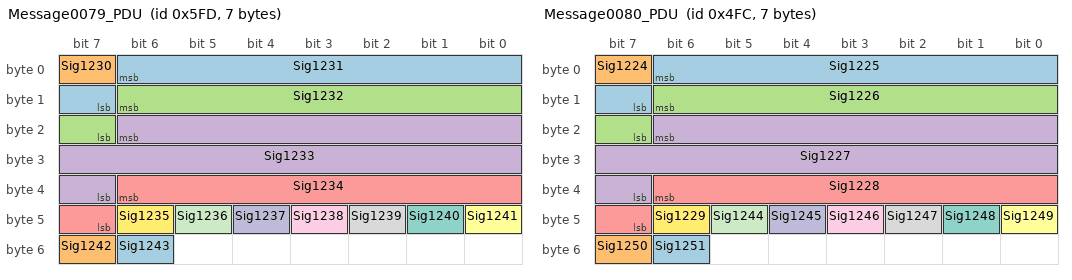
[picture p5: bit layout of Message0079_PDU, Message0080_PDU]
BO_ 1533 Message0079_PDU: 7 Vector__XXX
 SG_ Sig1231 : 6|8@0+ (1,0) [0|255] "" CGM
 SG_ Sig1230 : 7|1@0+ (1,0) [0|1] "" CGM
 SG_ Sig1232 : 14|8@0+ (1,0) [0|3] "" CGM
 SG_ Sig1233 : 22|16@0+ (1,0) [0|65535] "" CGM
 SG_ Sig1234 : 38|8@0+ (1,0) [0|255] "" CGM
 SG_ Sig1241 : 40|1@0+ (1,0) [0|1] "" CGM
 SG_ Sig1240 : 41|1@0+ (1,0) [0|1] "" CGM
 SG_ Sig1239 : 42|1@0+ (1,0) [0|1] "" CGM
 SG_ Sig1238 : 43|1@0+ (1,0) [0|1] "" CGM
 SG_ Sig1237 : 44|1@0+ (1,0) [0|1] "" CGM
 SG_ Sig1236 : 45|1@0+ (1,0) [0|1] "" CGM
 SG_ Sig1235 : 46|1@0+ (1,0) [0|1] "" CGM
 SG_ Sig1243 : 54|1@0+ (1,0) [0|1] "" CGM
 SG_ Sig1242 : 55|1@0+ (1,0) [0|1] "" CGM

BO_ 1276 Message0080_PDU: 7 Vector__XXX
 SG_ Sig1225 : 6|8@0+ (1,0) [0|255] "" CGM
 SG_ Sig1224 : 7|1@0+ (1,0) [0|1] "" CGM
 SG_ Sig1226 : 14|8@0+ (1,0) [0|3] "" CGM
 SG_ Sig1227 : 22|16@0+ (1,0) [0|65535] "" CGM
 SG_ Sig1228 : 38|8@0+ (1,0) [0|255] "" CGM
 SG_ Sig1249 : 40|1@0+ (1,0) [0|1] "" CGM
 SG_ Sig1248 : 41|1@0+ (1,0) [0|1] "" CGM
 SG_ Sig1247 : 42|1@0+ (1,0) [0|1] "" CGM
 SG_ Sig1246 : 43|1@0+ (1,0) [0|1] "" CGM
 SG_ Sig1245 : 44|1@0+ (1,0) [0|1] "" CGM
 SG_ Sig1244 : 45|1@0+ (1,0) [0|1] "" CGM
 SG_ Sig1229 : 46|1@0+ (1,0) [0|1] "" CGM
 SG_ Sig1251 : 54|1@0+ (1,0) [0|1] "" CGM
 SG_ Sig1250 : 55|1@0+ (1,0) [0|1] "" CGM

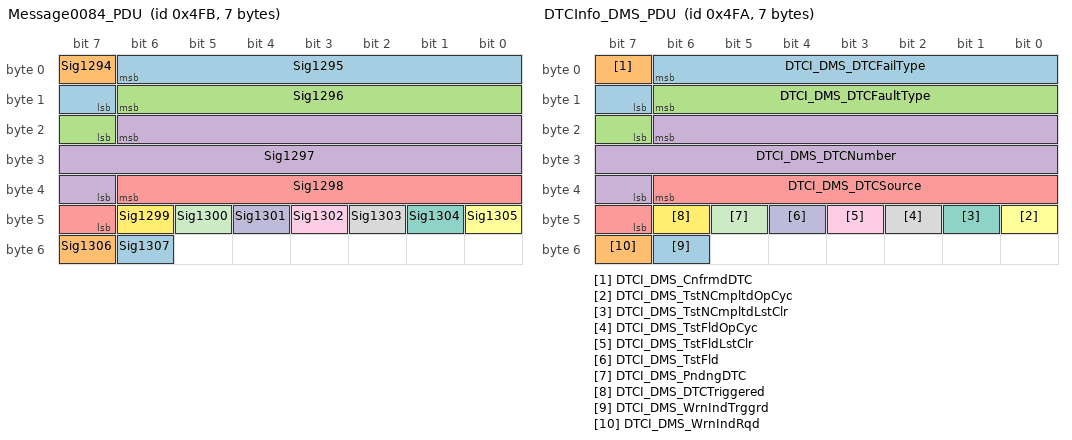
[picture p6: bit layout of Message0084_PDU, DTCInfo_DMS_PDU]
BO_ 1275 Message0084_PDU: 7 Vector__XXX
 SG_ Sig1295 : 6|8@0+ (1,0) [0|255] "" CGM
 SG_ Sig1294 : 7|1@0+ (1,0) [0|1] "" CGM
 SG_ Sig1296 : 14|8@0+ (1,0) [0|3] "" CGM
 SG_ Sig1297 : 22|16@0+ (1,0) [0|65535] "" CGM
 SG_ Sig1298 : 38|8@0+ (1,0) [0|255] "" CGM
 SG_ Sig1305 : 40|1@0+ (1,0) [0|1] "" CGM
 SG_ Sig1304 : 41|1@0+ (1,0) [0|1] "" CGM
 SG_ Sig1303 : 42|1@0+ (1,0) [0|1] "" CGM
 SG_ Sig1302 : 43|1@0+ (1,0) [0|1] "" CGM
 SG_ Sig1301 : 44|1@0+ (1,0) [0|1] "" CGM
 SG_ Sig1300 : 45|1@0+ (1,0) [0|1] "" CGM
 SG_ Sig1299 : 46|1@0+ (1,0) [0|1] "" CGM
 SG_ Sig1307 : 54|1@0+ (1,0) [0|1] "" CGM
 SG_ Sig1306 : 55|1@0+ (1,0) [0|1] "" CGM

BO_ 1274 DTCInfo_DMS_PDU: 7 Vector__XXX
 SG_ DTCI_DMS_DTCFailType : 6|8@0+ (1,0) [0|255] "" CGM
 SG_ DTCI_DMS_CnfrmdDTC : 7|1@0+ (1,0) [0|1] "" CGM
 SG_ DTCI_DMS_DTCFaultType : 14|8@0+ (1,0) [0|3] "" CGM
 SG_ DTCI_DMS_DTCNumber : 22|16@0+ (1,0) [0|65535] "" CGM
 SG_ DTCI_DMS_DTCSource : 38|8@0+ (1,0) [0|255] "" CGM
 SG_ DTCI_DMS_TstNCmpltdOpCyc : 40|1@0+ (1,0) [0|1] "" CGM
 SG_ DTCI_DMS_TstNCmpltdLstClr : 41|1@0+ (1,0) [0|1] "" CGM
 SG_ DTCI_DMS_TstFldOpCyc : 42|1@0+ (1,0) [0|1] "" CGM
 SG_ DTCI_DMS_TstFldLstClr : 43|1@0+ (1,0) [0|1] "" CGM
 SG_ DTCI_DMS_TstFld : 44|1@0+ (1,0) [0|1] "" CGM
 SG_ DTCI_DMS_PndngDTC : 45|1@0+ (1,0) [0|1] "" CGM
 SG_ DTCI_DMS_DTCTriggered : 46|1@0+ (1,0) [0|1] "" CGM
 SG_ DTCI_DMS_WrnIndTrggrd : 54|1@0+ (1,0) [0|1] "" CGM
 SG_ DTCI_DMS_WrnIndRqd : 55|1@0+ (1,0) [0|1] "" CGM

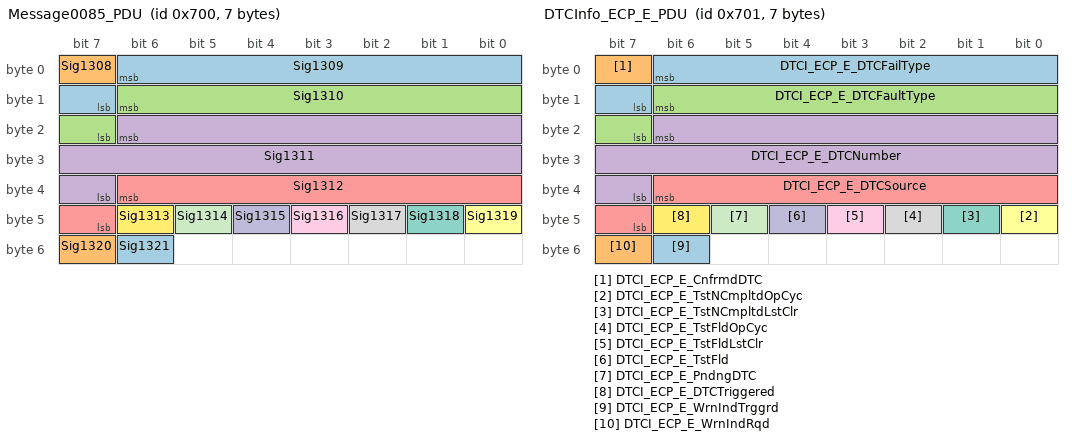
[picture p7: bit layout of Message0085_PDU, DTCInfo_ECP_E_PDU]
BO_ 1792 Message0085_PDU: 7 Vector__XXX
 SG_ Sig1309 : 6|8@0+ (1,0) [0|255] "" CGM
 SG_ Sig1308 : 7|1@0+ (1,0) [0|1] "" CGM
 SG_ Sig1310 : 14|8@0+ (1,0) [0|3] "" CGM
 SG_ Sig1311 : 22|16@0+ (1,0) [0|65535] "" CGM
 SG_ Sig1312 : 38|8@0+ (1,0) [0|255] "" CGM
 SG_ Sig1319 : 40|1@0+ (1,0) [0|1] "" CGM
 SG_ Sig1318 : 41|1@0+ (1,0) [0|1] "" CGM
 SG_ Sig1317 : 42|1@0+ (1,0) [0|1] "" CGM
 SG_ Sig1316 : 43|1@0+ (1,0) [0|1] "" CGM
 SG_ Sig1315 : 44|1@0+ (1,0) [0|1] "" CGM
 SG_ Sig1314 : 45|1@0+ (1,0) [0|1] "" CGM
 SG_ Sig1313 : 46|1@0+ (1,0) [0|1] "" CGM
 SG_ Sig1321 : 54|1@0+ (1,0) [0|1] "" CGM
 SG_ Sig1320 : 55|1@0+ (1,0) [0|1] "" CGM

BO_ 1793 DTCInfo_ECP_E_PDU: 7 Vector__XXX
 SG_ DTCI_ECP_E_DTCFailType : 6|8@0+ (1,0) [0|255] "" ADIMa,CGM
 SG_ DTCI_ECP_E_CnfrmdDTC : 7|1@0+ (1,0) [0|1] "" ADIMa,CGM
 SG_ DTCI_ECP_E_DTCFaultType : 14|8@0+ (1,0) [0|3] "" ADIMa,CGM
 SG_ DTCI_ECP_E_DTCNumber : 22|16@0+ (1,0) [0|65535] "" ADIMa,CGM
 SG_ DTCI_ECP_E_DTCSource : 38|8@0+ (1,0) [0|255] "" ADIMa,CGM
 SG_ DTCI_ECP_E_TstNCmpltdOpCyc : 40|1@0+ (1,0) [0|1] "" ADIMa,CGM
 SG_ DTCI_ECP_E_TstNCmpltdLstClr : 41|1@0+ (1,0) [0|1] "" ADIMa,CGM
 SG_ DTCI_ECP_E_TstFldOpCyc : 42|1@0+ (1,0) [0|1] "" ADIMa,CGM
 SG_ DTCI_ECP_E_TstFldLstClr : 43|1@0+ (1,0) [0|1] "" ADIMa,CGM
 SG_ DTCI_ECP_E_TstFld : 44|1@0+ (1,0) [0|1] "" ADIMa,CGM
 SG_ DTCI_ECP_E_PndngDTC : 45|1@0+ (1,0) [0|1] "" ADIMa,CGM
 SG_ DTCI_ECP_E_DTCTriggered : 46|1@0+ (1,0) [0|1] "" ADIMa,CGM
 SG_ DTCI_ECP_E_WrnIndTrggrd : 54|1@0+ (1,0) [0|1] "" ADIMa,CGM
 SG_ DTCI_ECP_E_WrnIndRqd : 55|1@0+ (1,0) [0|1] "" ADIMa,CGM

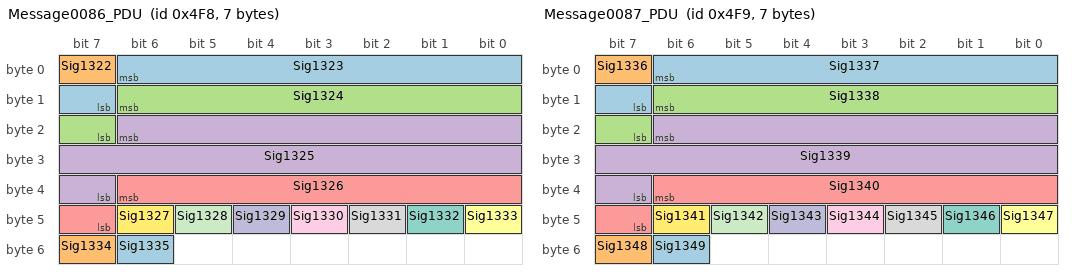
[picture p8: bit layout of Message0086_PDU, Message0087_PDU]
BO_ 1272 Message0086_PDU: 7 Vector__XXX
 SG_ Sig1323 : 6|8@0+ (1,0) [0|255] "" CGM
 SG_ Sig1322 : 7|1@0+ (1,0) [0|1] "" CGM
 SG_ Sig1324 : 14|8@0+ (1,0) [0|3] "" CGM
 SG_ Sig1325 : 22|16@0+ (1,0) [0|65535] "" CGM
 SG_ Sig1326 : 38|8@0+ (1,0) [0|255] "" CGM
 SG_ Sig1333 : 40|1@0+ (1,0) [0|1] "" CGM
 SG_ Sig1332 : 41|1@0+ (1,0) [0|1] "" CGM
 SG_ Sig1331 : 42|1@0+ (1,0) [0|1] "" CGM
 SG_ Sig1330 : 43|1@0+ (1,0) [0|1] "" CGM
 SG_ Sig1329 : 44|1@0+ (1,0) [0|1] "" CGM
 SG_ Sig1328 : 45|1@0+ (1,0) [0|1] "" CGM
 SG_ Sig1327 : 46|1@0+ (1,0) [0|1] "" CGM
 SG_ Sig1335 : 54|1@0+ (1,0) [0|1] "" CGM
 SG_ Sig1334 : 55|1@0+ (1,0) [0|1] "" CGM

BO_ 1273 Message0087_PDU: 7 Vector__XXX
 SG_ Sig1337 : 6|8@0+ (1,0) [0|255] "" CGM
 SG_ Sig1336 : 7|1@0+ (1,0) [0|1] "" CGM
 SG_ Sig1338 : 14|8@0+ (1,0) [0|3] "" CGM
 SG_ Sig1339 : 22|16@0+ (1,0) [0|65535] "" CGM
 SG_ Sig1340 : 38|8@0+ (1,0) [0|255] "" CGM
 SG_ Sig1347 : 40|1@0+ (1,0) [0|1] "" CGM
 SG_ Sig1346 : 41|1@0+ (1,0) [0|1] "" CGM
 SG_ Sig1345 : 42|1@0+ (1,0) [0|1] "" CGM
 SG_ Sig1344 : 43|1@0+ (1,0) [0|1] "" CGM
 SG_ Sig1343 : 44|1@0+ (1,0) [0|1] "" CGM
 SG_ Sig1342 : 45|1@0+ (1,0) [0|1] "" CGM
 SG_ Sig1341 : 46|1@0+ (1,0) [0|1] "" CGM
 SG_ Sig1349 : 54|1@0+ (1,0) [0|1] "" CGM
 SG_ Sig1348 : 55|1@0+ (1,0) [0|1] "" CGM

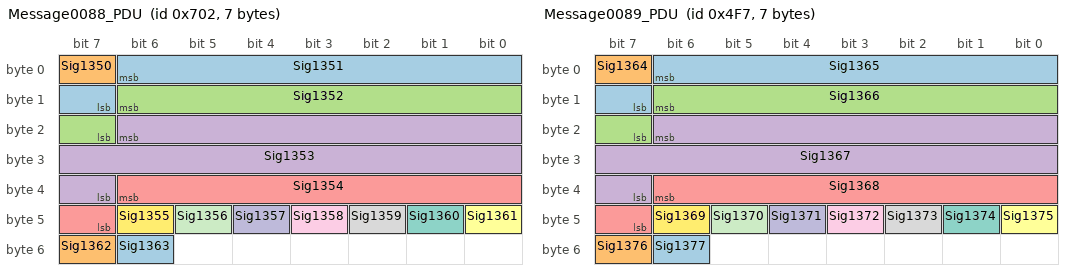
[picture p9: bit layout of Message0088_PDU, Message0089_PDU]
BO_ 1794 Message0088_PDU: 7 Vector__XXX
 SG_ Sig1351 : 6|8@0+ (1,0) [0|255] "" CGM
 SG_ Sig1350 : 7|1@0+ (1,0) [0|1] "" CGM
 SG_ Sig1352 : 14|8@0+ (1,0) [0|3] "" CGM
 SG_ Sig1353 : 22|16@0+ (1,0) [0|65535] "" CGM
 SG_ Sig1354 : 38|8@0+ (1,0) [0|255] "" CGM
 SG_ Sig1361 : 40|1@0+ (1,0) [0|1] "" CGM
 SG_ Sig1360 : 41|1@0+ (1,0) [0|1] "" CGM
 SG_ Sig1359 : 42|1@0+ (1,0) [0|1] "" CGM
 SG_ Sig1358 : 43|1@0+ (1,0) [0|1] "" CGM
 SG_ Sig1357 : 44|1@0+ (1,0) [0|1] "" CGM
 SG_ Sig1356 : 45|1@0+ (1,0) [0|1] "" CGM
 SG_ Sig1355 : 46|1@0+ (1,0) [0|1] "" CGM
 SG_ Sig1363 : 54|1@0+ (1,0) [0|1] "" CGM
 SG_ Sig1362 : 55|1@0+ (1,0) [0|1] "" CGM

BO_ 1271 Message0089_PDU: 7 Vector__XXX
 SG_ Sig1365 : 6|8@0+ (1,0) [0|255] "" CGM
 SG_ Sig1364 : 7|1@0+ (1,0) [0|1] "" CGM
 SG_ Sig1366 : 14|8@0+ (1,0) [0|3] "" CGM
 SG_ Sig1367 : 22|16@0+ (1,0) [0|65535] "" CGM
 SG_ Sig1368 : 38|8@0+ (1,0) [0|255] "" CGM
 SG_ Sig1375 : 40|1@0+ (1,0) [0|1] "" CGM
 SG_ Sig1374 : 41|1@0+ (1,0) [0|1] "" CGM
 SG_ Sig1373 : 42|1@0+ (1,0) [0|1] "" CGM
 SG_ Sig1372 : 43|1@0+ (1,0) [0|1] "" CGM
 SG_ Sig1371 : 44|1@0+ (1,0) [0|1] "" CGM
 SG_ Sig1370 : 45|1@0+ (1,0) [0|1] "" CGM
 SG_ Sig1369 : 46|1@0+ (1,0) [0|1] "" CGM
 SG_ Sig1377 : 54|1@0+ (1,0) [0|1] "" CGM
 SG_ Sig1376 : 55|1@0+ (1,0) [0|1] "" CGM

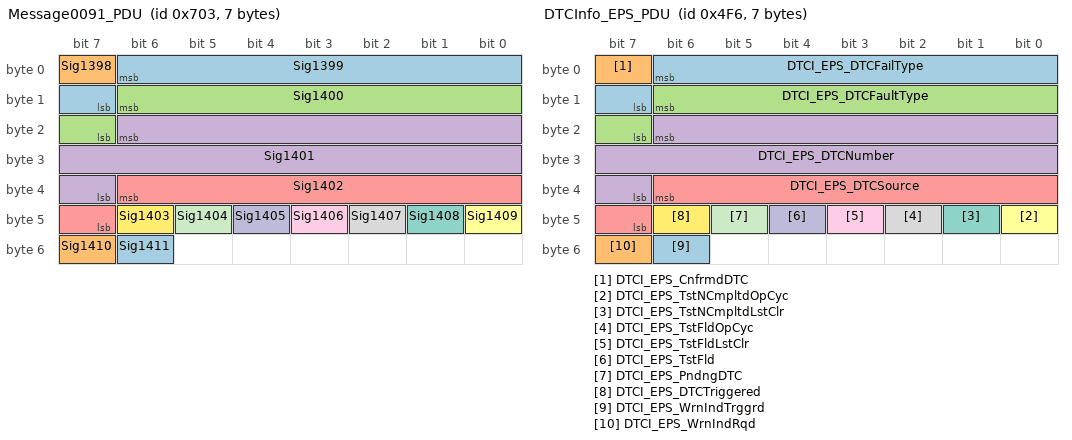
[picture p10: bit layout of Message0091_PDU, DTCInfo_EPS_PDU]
BO_ 1795 Message0091_PDU: 7 Vector__XXX
 SG_ Sig1399 : 6|8@0+ (1,0) [0|255] "" CGM
 SG_ Sig1398 : 7|1@0+ (1,0) [0|1] "" CGM
 SG_ Sig1400 : 14|8@0+ (1,0) [0|3] "" CGM
 SG_ Sig1401 : 22|16@0+ (1,0) [0|65535] "" CGM
 SG_ Sig1402 : 38|8@0+ (1,0) [0|255] "" CGM
 SG_ Sig1409 : 40|1@0+ (1,0) [0|1] "" CGM
 SG_ Sig1408 : 41|1@0+ (1,0) [0|1] "" CGM
 SG_ Sig1407 : 42|1@0+ (1,0) [0|1] "" CGM
 SG_ Sig1406 : 43|1@0+ (1,0) [0|1] "" CGM
 SG_ Sig1405 : 44|1@0+ (1,0) [0|1] "" CGM
 SG_ Sig1404 : 45|1@0+ (1,0) [0|1] "" CGM
 SG_ Sig1403 : 46|1@0+ (1,0) [0|1] "" CGM
 SG_ Sig1411 : 54|1@0+ (1,0) [0|1] "" CGM
 SG_ Sig1410 : 55|1@0+ (1,0) [0|1] "" CGM

BO_ 1270 DTCInfo_EPS_PDU: 7 Vector__XXX
 SG_ DTCI_EPS_DTCFailType : 6|8@0+ (1,0) [0|255] "" CGM
 SG_ DTCI_EPS_CnfrmdDTC : 7|1@0+ (1,0) [0|1] "" CGM
 SG_ DTCI_EPS_DTCFaultType : 14|8@0+ (1,0) [0|3] "" CGM
 SG_ DTCI_EPS_DTCNumber : 22|16@0+ (1,0) [0|65535] "" CGM
 SG_ DTCI_EPS_DTCSource : 38|8@0+ (1,0) [0|255] "" CGM
 SG_ DTCI_EPS_TstNCmpltdOpCyc : 40|1@0+ (1,0) [0|1] "" CGM
 SG_ DTCI_EPS_TstNCmpltdLstClr : 41|1@0+ (1,0) [0|1] "" CGM
 SG_ DTCI_EPS_TstFldOpCyc : 42|1@0+ (1,0) [0|1] "" CGM
 SG_ DTCI_EPS_TstFldLstClr : 43|1@0+ (1,0) [0|1] "" CGM
 SG_ DTCI_EPS_TstFld : 44|1@0+ (1,0) [0|1] "" CGM
 SG_ DTCI_EPS_PndngDTC : 45|1@0+ (1,0) [0|1] "" CGM
 SG_ DTCI_EPS_DTCTriggered : 46|1@0+ (1,0) [0|1] "" CGM
 SG_ DTCI_EPS_WrnIndTrggrd : 54|1@0+ (1,0) [0|1] "" CGM
 SG_ DTCI_EPS_WrnIndRqd : 55|1@0+ (1,0) [0|1] "" CGM

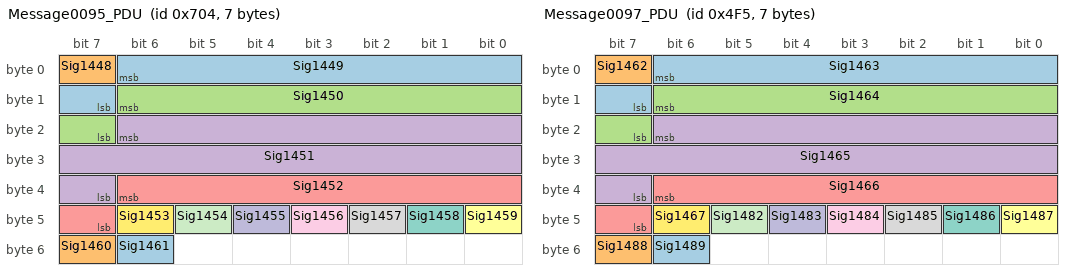
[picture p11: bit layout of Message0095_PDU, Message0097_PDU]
BO_ 1796 Message0095_PDU: 7 Vector__XXX
 SG_ Sig1449 : 6|8@0+ (1,0) [0|255] "" CGM
 SG_ Sig1448 : 7|1@0+ (1,0) [0|1] "" CGM
 SG_ Sig1450 : 14|8@0+ (1,0) [0|3] "" CGM
 SG_ Sig1451 : 22|16@0+ (1,0) [0|65535] "" CGM
 SG_ Sig1452 : 38|8@0+ (1,0) [0|255] "" CGM
 SG_ Sig1459 : 40|1@0+ (1,0) [0|1] "" CGM
 SG_ Sig1458 : 41|1@0+ (1,0) [0|1] "" CGM
 SG_ Sig1457 : 42|1@0+ (1,0) [0|1] "" CGM
 SG_ Sig1456 : 43|1@0+ (1,0) [0|1] "" CGM
 SG_ Sig1455 : 44|1@0+ (1,0) [0|1] "" CGM
 SG_ Sig1454 : 45|1@0+ (1,0) [0|1] "" CGM
 SG_ Sig1453 : 46|1@0+ (1,0) [0|1] "" CGM
 SG_ Sig1461 : 54|1@0+ (1,0) [0|1] "" CGM
 SG_ Sig1460 : 55|1@0+ (1,0) [0|1] "" CGM

BO_ 1269 Message0097_PDU: 7 Vector__XXX
 SG_ Sig1463 : 6|8@0+ (1,0) [0|255] "" CGM
 SG_ Sig1462 : 7|1@0+ (1,0) [0|1] "" CGM
 SG_ Sig1464 : 14|8@0+ (1,0) [0|3] "" CGM
 SG_ Sig1465 : 22|16@0+ (1,0) [0|65535] "" CGM
 SG_ Sig1466 : 38|8@0+ (1,0) [0|255] "" CGM
 SG_ Sig1487 : 40|1@0+ (1,0) [0|1] "" CGM
 SG_ Sig1486 : 41|1@0+ (1,0) [0|1] "" CGM
 SG_ Sig1485 : 42|1@0+ (1,0) [0|1] "" CGM
 SG_ Sig1484 : 43|1@0+ (1,0) [0|1] "" CGM
 SG_ Sig1483 : 44|1@0+ (1,0) [0|1] "" CGM
 SG_ Sig1482 : 45|1@0+ (1,0) [0|1] "" CGM
 SG_ Sig1467 : 46|1@0+ (1,0) [0|1] "" CGM
 SG_ Sig1489 : 54|1@0+ (1,0) [0|1] "" CGM
 SG_ Sig1488 : 55|1@0+ (1,0) [0|1] "" CGM

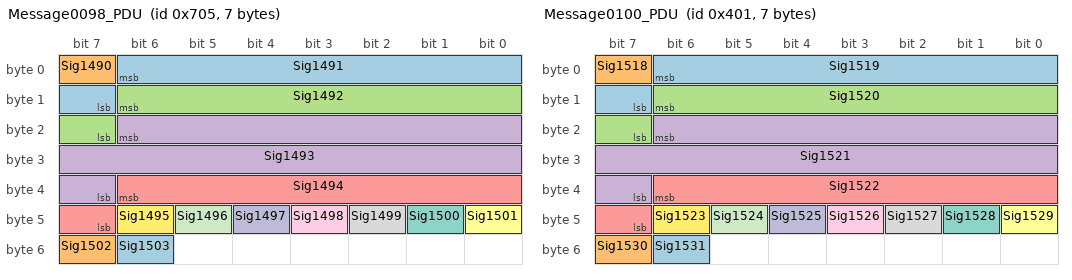
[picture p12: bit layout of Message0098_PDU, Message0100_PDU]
BO_ 1797 Message0098_PDU: 7 Vector__XXX
 SG_ Sig1491 : 6|8@0+ (1,0) [0|255] "" ADIMa,CGM
 SG_ Sig1490 : 7|1@0+ (1,0) [0|1] "" ADIMa,CGM
 SG_ Sig1492 : 14|8@0+ (1,0) [0|3] "" ADIMa,CGM
 SG_ Sig1493 : 22|16@0+ (1,0) [0|65535] "" ADIMa,CGM
 SG_ Sig1494 : 38|8@0+ (1,0) [0|255] "" ADIMa,CGM
 SG_ Sig1501 : 40|1@0+ (1,0) [0|1] "" ADIMa,CGM
 SG_ Sig1500 : 41|1@0+ (1,0) [0|1] "" ADIMa,CGM
 SG_ Sig1499 : 42|1@0+ (1,0) [0|1] "" ADIMa,CGM
 SG_ Sig1498 : 43|1@0+ (1,0) [0|1] "" ADIMa,CGM
 SG_ Sig1497 : 44|1@0+ (1,0) [0|1] "" ADIMa,CGM
 SG_ Sig1496 : 45|1@0+ (1,0) [0|1] "" ADIMa,CGM
 SG_ Sig1495 : 46|1@0+ (1,0) [0|1] "" ADIMa,CGM
 SG_ Sig1503 : 54|1@0+ (1,0) [0|1] "" ADIMa,CGM
 SG_ Sig1502 : 55|1@0+ (1,0) [0|1] "" ADIMa,CGM

BO_ 1025 Message0100_PDU: 7 Vector__XXX
 SG_ Sig1519 : 6|8@0+ (1,0) [0|255] "" CGM
 SG_ Sig1518 : 7|1@0+ (1,0) [0|1] "" CGM
 SG_ Sig1520 : 14|8@0+ (1,0) [0|3] "" CGM
 SG_ Sig1521 : 22|16@0+ (1,0) [0|65535] "" CGM
 SG_ Sig1522 : 38|8@0+ (1,0) [0|255] "" CGM
 SG_ Sig1529 : 40|1@0+ (1,0) [0|1] "" CGM
 SG_ Sig1528 : 41|1@0+ (1,0) [0|1] "" CGM
 SG_ Sig1527 : 42|1@0+ (1,0) [0|1] "" CGM
 SG_ Sig1526 : 43|1@0+ (1,0) [0|1] "" CGM
 SG_ Sig1525 : 44|1@0+ (1,0) [0|1] "" CGM
 SG_ Sig1524 : 45|1@0+ (1,0) [0|1] "" CGM
 SG_ Sig1523 : 46|1@0+ (1,0) [0|1] "" CGM
 SG_ Sig1531 : 54|1@0+ (1,0) [0|1] "" CGM
 SG_ Sig1530 : 55|1@0+ (1,0) [0|1] "" CGM

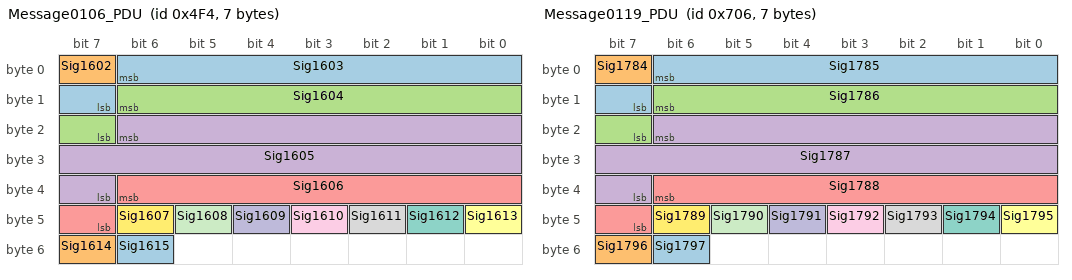
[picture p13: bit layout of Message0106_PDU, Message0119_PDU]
BO_ 1268 Message0106_PDU: 7 Vector__XXX
 SG_ Sig1603 : 6|8@0+ (1,0) [0|255] "" CGM
 SG_ Sig1602 : 7|1@0+ (1,0) [0|1] "" CGM
 SG_ Sig1604 : 14|8@0+ (1,0) [0|3] "" CGM
 SG_ Sig1605 : 22|16@0+ (1,0) [0|65535] "" CGM
 SG_ Sig1606 : 38|8@0+ (1,0) [0|255] "" CGM
 SG_ Sig1613 : 40|1@0+ (1,0) [0|1] "" CGM
 SG_ Sig1612 : 41|1@0+ (1,0) [0|1] "" CGM
 SG_ Sig1611 : 42|1@0+ (1,0) [0|1] "" CGM
 SG_ Sig1610 : 43|1@0+ (1,0) [0|1] "" CGM
 SG_ Sig1609 : 44|1@0+ (1,0) [0|1] "" CGM
 SG_ Sig1608 : 45|1@0+ (1,0) [0|1] "" CGM
 SG_ Sig1607 : 46|1@0+ (1,0) [0|1] "" CGM
 SG_ Sig1615 : 54|1@0+ (1,0) [0|1] "" CGM
 SG_ Sig1614 : 55|1@0+ (1,0) [0|1] "" CGM

BO_ 1798 Message0119_PDU: 7 Vector__XXX
 SG_ Sig1785 : 6|8@0+ (1,0) [0|255] "" CGM
 SG_ Sig1784 : 7|1@0+ (1,0) [0|1] "" CGM
 SG_ Sig1786 : 14|8@0+ (1,0) [0|3] "" CGM
 SG_ Sig1787 : 22|16@0+ (1,0) [0|65535] "" CGM
 SG_ Sig1788 : 38|8@0+ (1,0) [0|255] "" CGM
 SG_ Sig1795 : 40|1@0+ (1,0) [0|1] "" CGM
 SG_ Sig1794 : 41|1@0+ (1,0) [0|1] "" CGM
 SG_ Sig1793 : 42|1@0+ (1,0) [0|1] "" CGM
 SG_ Sig1792 : 43|1@0+ (1,0) [0|1] "" CGM
 SG_ Sig1791 : 44|1@0+ (1,0) [0|1] "" CGM
 SG_ Sig1790 : 45|1@0+ (1,0) [0|1] "" CGM
 SG_ Sig1789 : 46|1@0+ (1,0) [0|1] "" CGM
 SG_ Sig1797 : 54|1@0+ (1,0) [0|1] "" CGM
 SG_ Sig1796 : 55|1@0+ (1,0) [0|1] "" CGM

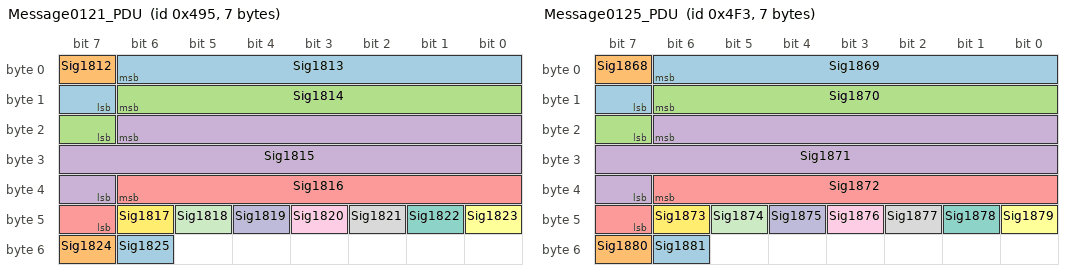
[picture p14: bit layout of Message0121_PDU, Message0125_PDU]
BO_ 1173 Message0121_PDU: 7 Vector__XXX
 SG_ Sig1813 : 6|8@0+ (1,0) [0|255] "" CGM
 SG_ Sig1812 : 7|1@0+ (1,0) [0|1] "" CGM
 SG_ Sig1814 : 14|8@0+ (1,0) [0|3] "" CGM
 SG_ Sig1815 : 22|16@0+ (1,0) [0|65535] "" CGM
 SG_ Sig1816 : 38|8@0+ (1,0) [0|255] "" CGM
 SG_ Sig1823 : 40|1@0+ (1,0) [0|1] "" CGM
 SG_ Sig1822 : 41|1@0+ (1,0) [0|1] "" CGM
 SG_ Sig1821 : 42|1@0+ (1,0) [0|1] "" CGM
 SG_ Sig1820 : 43|1@0+ (1,0) [0|1] "" CGM
 SG_ Sig1819 : 44|1@0+ (1,0) [0|1] "" CGM
 SG_ Sig1818 : 45|1@0+ (1,0) [0|1] "" CGM
 SG_ Sig1817 : 46|1@0+ (1,0) [0|1] "" CGM
 SG_ Sig1825 : 54|1@0+ (1,0) [0|1] "" CGM
 SG_ Sig1824 : 55|1@0+ (1,0) [0|1] "" CGM

BO_ 1267 Message0125_PDU: 7 Vector__XXX
 SG_ Sig1869 : 6|8@0+ (1,0) [0|255] "" CGM
 SG_ Sig1868 : 7|1@0+ (1,0) [0|1] "" CGM
 SG_ Sig1870 : 14|8@0+ (1,0) [0|3] "" CGM
 SG_ Sig1871 : 22|16@0+ (1,0) [0|65535] "" CGM
 SG_ Sig1872 : 38|8@0+ (1,0) [0|255] "" CGM
 SG_ Sig1879 : 40|1@0+ (1,0) [0|1] "" CGM
 SG_ Sig1878 : 41|1@0+ (1,0) [0|1] "" CGM
 SG_ Sig1877 : 42|1@0+ (1,0) [0|1] "" CGM
 SG_ Sig1876 : 43|1@0+ (1,0) [0|1] "" CGM
 SG_ Sig1875 : 44|1@0+ (1,0) [0|1] "" CGM
 SG_ Sig1874 : 45|1@0+ (1,0) [0|1] "" CGM
 SG_ Sig1873 : 46|1@0+ (1,0) [0|1] "" CGM
 SG_ Sig1881 : 54|1@0+ (1,0) [0|1] "" CGM
 SG_ Sig1880 : 55|1@0+ (1,0) [0|1] "" CGM

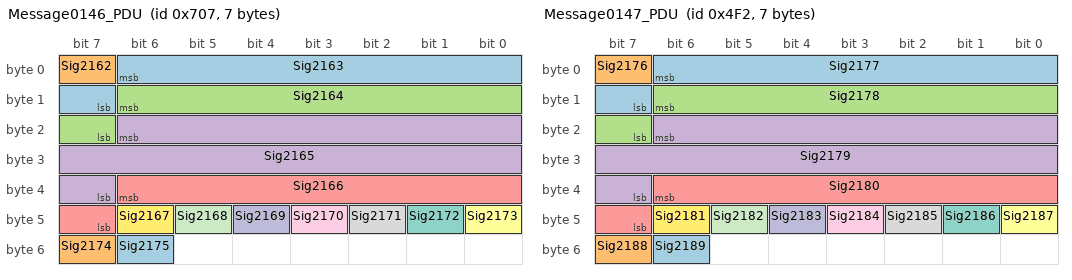
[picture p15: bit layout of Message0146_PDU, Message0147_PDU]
BO_ 1799 Message0146_PDU: 7 Vector__XXX
 SG_ Sig2163 : 6|8@0+ (1,0) [0|255] "" CGM
 SG_ Sig2162 : 7|1@0+ (1,0) [0|1] "" CGM
 SG_ Sig2164 : 14|8@0+ (1,0) [0|3] "" CGM
 SG_ Sig2165 : 22|16@0+ (1,0) [0|65535] "" CGM
 SG_ Sig2166 : 38|8@0+ (1,0) [0|255] "" CGM
 SG_ Sig2173 : 40|1@0+ (1,0) [0|1] "" CGM
 SG_ Sig2172 : 41|1@0+ (1,0) [0|1] "" CGM
 SG_ Sig2171 : 42|1@0+ (1,0) [0|1] "" CGM
 SG_ Sig2170 : 43|1@0+ (1,0) [0|1] "" CGM
 SG_ Sig2169 : 44|1@0+ (1,0) [0|1] "" CGM
 SG_ Sig2168 : 45|1@0+ (1,0) [0|1] "" CGM
 SG_ Sig2167 : 46|1@0+ (1,0) [0|1] "" CGM
 SG_ Sig2175 : 54|1@0+ (1,0) [0|1] "" CGM
 SG_ Sig2174 : 55|1@0+ (1,0) [0|1] "" CGM

BO_ 1266 Message0147_PDU: 7 Vector__XXX
 SG_ Sig2177 : 6|8@0+ (1,0) [0|255] "" CGM
 SG_ Sig2176 : 7|1@0+ (1,0) [0|1] "" CGM
 SG_ Sig2178 : 14|8@0+ (1,0) [0|3] "" CGM
 SG_ Sig2179 : 22|16@0+ (1,0) [0|65535] "" CGM
 SG_ Sig2180 : 38|8@0+ (1,0) [0|255] "" CGM
 SG_ Sig2187 : 40|1@0+ (1,0) [0|1] "" CGM
 SG_ Sig2186 : 41|1@0+ (1,0) [0|1] "" CGM
 SG_ Sig2185 : 42|1@0+ (1,0) [0|1] "" CGM
 SG_ Sig2184 : 43|1@0+ (1,0) [0|1] "" CGM
 SG_ Sig2183 : 44|1@0+ (1,0) [0|1] "" CGM
 SG_ Sig2182 : 45|1@0+ (1,0) [0|1] "" CGM
 SG_ Sig2181 : 46|1@0+ (1,0) [0|1] "" CGM
 SG_ Sig2189 : 54|1@0+ (1,0) [0|1] "" CGM
 SG_ Sig2188 : 55|1@0+ (1,0) [0|1] "" CGM

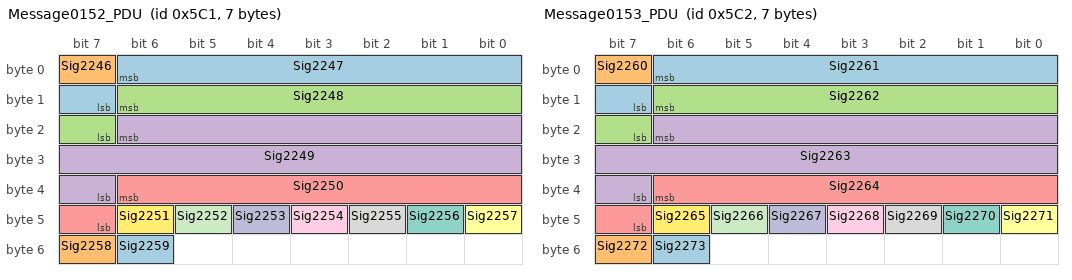
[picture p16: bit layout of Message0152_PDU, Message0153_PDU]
BO_ 1473 Message0152_PDU: 7 Vector__XXX
 SG_ Sig2247 : 6|8@0+ (1,0) [0|255] "" CGM
 SG_ Sig2246 : 7|1@0+ (1,0) [0|1] "" CGM
 SG_ Sig2248 : 14|8@0+ (1,0) [0|3] "" CGM
 SG_ Sig2249 : 22|16@0+ (1,0) [0|65535] "" CGM
 SG_ Sig2250 : 38|8@0+ (1,0) [0|255] "" CGM
 SG_ Sig2257 : 40|1@0+ (1,0) [0|1] "" CGM
 SG_ Sig2256 : 41|1@0+ (1,0) [0|1] "" CGM
 SG_ Sig2255 : 42|1@0+ (1,0) [0|1] "" CGM
 SG_ Sig2254 : 43|1@0+ (1,0) [0|1] "" CGM
 SG_ Sig2253 : 44|1@0+ (1,0) [0|1] "" CGM
 SG_ Sig2252 : 45|1@0+ (1,0) [0|1] "" CGM
 SG_ Sig2251 : 46|1@0+ (1,0) [0|1] "" CGM
 SG_ Sig2259 : 54|1@0+ (1,0) [0|1] "" CGM
 SG_ Sig2258 : 55|1@0+ (1,0) [0|1] "" CGM

BO_ 1474 Message0153_PDU: 7 Vector__XXX
 SG_ Sig2261 : 6|8@0+ (1,0) [0|255] "" CGM
 SG_ Sig2260 : 7|1@0+ (1,0) [0|1] "" CGM
 SG_ Sig2262 : 14|8@0+ (1,0) [0|3] "" CGM
 SG_ Sig2263 : 22|16@0+ (1,0) [0|65535] "" CGM
 SG_ Sig2264 : 38|8@0+ (1,0) [0|255] "" CGM
 SG_ Sig2271 : 40|1@0+ (1,0) [0|1] "" CGM
 SG_ Sig2270 : 41|1@0+ (1,0) [0|1] "" CGM
 SG_ Sig2269 : 42|1@0+ (1,0) [0|1] "" CGM
 SG_ Sig2268 : 43|1@0+ (1,0) [0|1] "" CGM
 SG_ Sig2267 : 44|1@0+ (1,0) [0|1] "" CGM
 SG_ Sig2266 : 45|1@0+ (1,0) [0|1] "" CGM
 SG_ Sig2265 : 46|1@0+ (1,0) [0|1] "" CGM
 SG_ Sig2273 : 54|1@0+ (1,0) [0|1] "" CGM
 SG_ Sig2272 : 55|1@0+ (1,0) [0|1] "" CGM

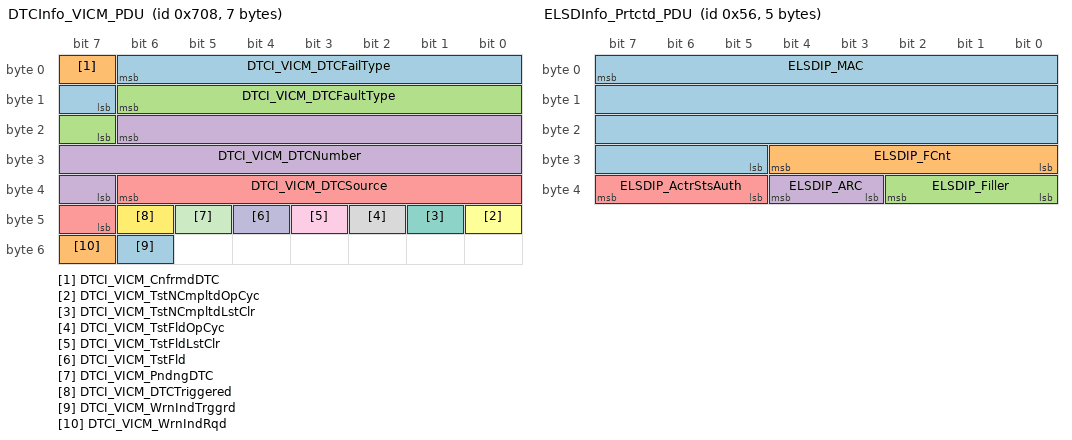
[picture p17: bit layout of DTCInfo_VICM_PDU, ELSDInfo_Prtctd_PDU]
BO_ 1800 DTCInfo_VICM_PDU: 7 Vector__XXX
 SG_ DTCI_VICM_DTCFailType : 6|8@0+ (1,0) [0|255] "" ADIMa,CGM
 SG_ DTCI_VICM_CnfrmdDTC : 7|1@0+ (1,0) [0|1] "" ADIMa,CGM
 SG_ DTCI_VICM_DTCFaultType : 14|8@0+ (1,0) [0|3] "" ADIMa,CGM
 SG_ DTCI_VICM_DTCNumber : 22|16@0+ (1,0) [0|65535] "" ADIMa,CGM
 SG_ DTCI_VICM_DTCSource : 38|8@0+ (1,0) [0|255] "" ADIMa,CGM
 SG_ DTCI_VICM_TstNCmpltdOpCyc : 40|1@0+ (1,0) [0|1] "" ADIMa,CGM
 SG_ DTCI_VICM_TstNCmpltdLstClr : 41|1@0+ (1,0) [0|1] "" ADIMa,CGM
 SG_ DTCI_VICM_TstFldOpCyc : 42|1@0+ (1,0) [0|1] "" ADIMa,CGM
 SG_ DTCI_VICM_TstFldLstClr : 43|1@0+ (1,0) [0|1] "" ADIMa,CGM
 SG_ DTCI_VICM_TstFld : 44|1@0+ (1,0) [0|1] "" ADIMa,CGM
 SG_ DTCI_VICM_PndngDTC : 45|1@0+ (1,0) [0|1] "" ADIMa,CGM
 SG_ DTCI_VICM_DTCTriggered : 46|1@0+ (1,0) [0|1] "" ADIMa,CGM
 SG_ DTCI_VICM_WrnIndTrggrd : 54|1@0+ (1,0) [0|1] "" ADIMa,CGM
 SG_ DTCI_VICM_WrnIndRqd : 55|1@0+ (1,0) [0|1] "" ADIMa,CGM

BO_ 1390 Message0166_PDU: 8 Vector__XXX
 SG_ Sig2417 : 7|64@0+ (1,0) [0|1.84467e+019] "" Vector__XXX

BO_ 872 Message0167_PDU: 8 Vector__XXX
 SG_ Sig0720 : 7|27@0+ (1,0) [0|1.34218e+008] "" CGM
 SG_ Sig0718 : 28|5@0+ (1,0) [0|31] "" CGM
 SG_ Sig0717 : 33|2@0+ (1,0) [0|3] "" CGM
 SG_ Sig0722 : 34|1@0+ (1,0) [0|1] "" CGM
 SG_ Sig0721 : 35|1@0+ (1,0) [0|1] "" CGM
 SG_ Sig0716 : 39|4@0+ (1,0) [0|15] "" CGM
 SG_ Sig0719 : 47|24@0+ (1,0) [0|1.67772e+007] "" CGM

BO_ 920 DrvrMonSysInfo_PCSM_PDU: 8 Vector__XXX
 SG_ DrvrMonSysInfo_PCSM : 7|64@0+ (1,0) [0|1.84467e+019] "" ACP2_MCU,EOCM,EOCM_HC_Superset

BO_ 186 DrvrMonSysInfo_Prtctd_PDU: 12 Vector__XXX
 SG_ DMSIP_MAC : 7|32@0+ (1,0) [0|4.29497e+009] "" ACP2_MCU,EOCM,EOCM_HC_Superset
 SG_ DMSIP_FCnt : 39|5@0+ (1,0) [0|31] "" ACP2_MCU,EOCM,EOCM_HC_Superset
 SG_ DMSIP_DrvrAttnStatAuth : 43|4@0+ (1,0) [0|11] "" ACP2_MCU,CGM,EOCM,EOCM_HC_Superset,FCM,HUD_CAN
 SG_ DMSDrvrAttnStatCnfdLvlAuth : 46|3@0+ (1,0) [0|7] "" ACP2_MCU,EOCM,EOCM_HC_Superset,FCM,HUD_CAN
 SG_ DMSDrvrAttnStatAlgTypAuth : 47|1@0+ (1,0) [0|1] "" ACP2_MCU,EOCM,EOCM_HC_Superset,FCM,HUD_CAN
 SG_ DMSIP_DrvrAttnStatPrdAuth : 54|14@0+ (0.05,0) [0|819.15] "s" ACP2_MCU,EOCM,EOCM_HC_Superset,FCM,HUD_CAN
 SG_ DMSIP_DrvrAttnStatAuth_Inv : 55|1@0+ (1,0) [0|1] "" ACP2_MCU,CGM,EOCM,EOCM_HC_Superset,FCM
 SG_ DMSOpStatAuth : 56|3@0+ (1,0) [0|6] "" ACP2_MCU,EOCM,EOCM_HC_Superset,FCM,HUD_CAN
 SG_ DMSOpStatPrdAuth : 69|14@0+ (0.05,0) [0|819.15] "s" ACP2_MCU,EOCM,EOCM_HC_Superset,FCM,HUD_CAN
 SG_ DMSIP_ARC : 87|2@0+ (1,0) [0|3] "" ACP2_MCU,EOCM,EOCM_HC_Superset

BO_ 919 EBCMGnrlInfo2_PCSM_PDU: 8 Vector__XXX
 SG_ EBCMGnrlInfo2_PCSM : 7|64@0+ (1,0) [0|1.84467e+019] "" ACP2_MCU,ARS,ECM,EOCM,EOCM_HC_Superset,FCM,E44,PCM

BO_ 624 EBCMGnrlInfo2_Prtctd_PDU: 12 Vector__XXX
 SG_ WRDSP_MAC : 7|32@0+ (1,0) [0|4.29497e+009] "" ACP2_MCU,ARS,CGM,ECM,EOCM,EOCM_HC_Superset,FCM,E44,PCM
 SG_ WRDSP_FCnt : 39|5@0+ (1,0) [0|31] "" ACP2_MCU,ARS,CGM,ECM,EOCM,EOCM_HC_Superset,FCM,E44,PCM
 SG_ VAP_ActlVehAccelAuth : 43|12@0- (0.01,0) [-20.48|20.47] "m/s^2" ACP2_MCU,AHL_AFL,ARS,CGM,ECM,EOCM,EOCM_HC_Superset,FCM,E44,PCM
 SG_ TBI2P_TrlrBrkgManAppAtvAuth : 44|1@0+ (1,0) [0|1] "" ACP2_MCU,ARS,CGM,ECM,EOCM,EOCM_HC_Superset,FCM,E44,PCM
 SG_ BSAE44BP_AE44BrkgStsAuth : 47|3@0+ (1,0) [0|5] "" ACP2_MCU,ARS,CGM,ECM,EOCM,EOCM_HC_Superset,FCM,E44,PCM
 SG_ WRDSP_RFAuth : 56|3@0+ (1,0) [0|4] "" ACP2_MCU,ADIMa,ADIMb,ARS,VICM,CGM,DCM,ECM,EOCM,EOCM_HC_Superset,EPS,EPSb,FCM,E44,PCM,RDCM,TCM,ECP_E,ECP_S,ECP_S2,ECP_X1
 SG_ WRDSP_LRAuth : 59|3@0+ (1,0) [0|4] "" ACP2_MCU,ADIMa,ADIMb,ARS,VICM,CGM,DCM,ECM,EOCM,EOCM_HC_Superset,EPS,EPSb,FCM,E44,PCM,RDCM,TCM,ECP_E,ECP_S,ECP_S2,ECP_X1
 SG_ WRDSP_LFAuth : 62|3@0+ (1,0) [0|4] "" ACP2_MCU,ADIMa,ADIMb,ARS,VICM,CGM,DCM,ECM,EOCM,EOCM_HC_Superset,EPS,EPSb,FCM,E44,PCM,RDCM,TCM,ECP_E,ECP_S,ECP_S2,ECP_X1
 SG_ VAP_ActlVehAccelAuth_Inv : 63|1@0+ (1,0) [0|1] "" ACP2_MCU,AHL_AFL,ARS,CGM,ECM,EOCM,EOCM_HC_Superset,FCM,E44,PCM
 SG_ SuprRmtPrkBrkResp : 64|3@0+ (1,0) [0|4] "" ACP2_MCU,ARS,CGM,ECM,EOCM,EOCM_HC_Superset,FCM,E44,PCM
 SG_ WRDSP_ARC : 66|2@0+ (1,0) [0|3] "" ACP2_MCU,ARS,CGM,ECM,EOCM,EOCM_HC_Superset,FCM,E44,PCM
 SG_ WRDSP_RRAuth : 69|3@0+ (1,0) [0|4] "" ACP2_MCU,ADIMa,ADIMb,ARS,VICM,CGM,DCM,ECM,EOCM,EOCM_HC_Superset,EPS,EPSb,FCM,E44,PCM,RDCM,TCM,ECP_E,ECP_S,ECP_S2,ECP_X1
 SG_ EBCMGI2P_Filler : 77|22@0+ (1,0) [0|4.1943e+006] "" ACP2_MCU,ARS,CGM,ECM,EOCM,EOCM_HC_Superset,FCM,E44,PCM

BO_ 2147745840 Message0183_PDU: 1 Vector__XXX
 SG_ Sig2467 : 7|1@0+ (1,0) [0|1] "" CGM

BO_ 2147745795 EBCM_AV_CAN2_ClscCANHrtBtActv_PD: 1 Vector__XXX
 SG_ EBCM_AV_CAN2_ClscCANHrtBtActv : 7|1@0+ (1,0) [0|1] "" CGM

BO_ 2147745796 EBCM_CAN2_ClscCANHrtBtActv_PDU: 1 Vector__XXX
 SG_ EBCM_CAN2_ClscCANHrtBtActv : 7|1@0+ (1,0) [0|1] "" CGM

BO_ 296 EBCM_NM_PDU_On_CAN_2_Cluster: 8 Vector__XXX
 SG_ ISignal_EBCM_CAN_2_Cluster : 23|48@0+ (1,0) [0|281474976710655] "" ACP2_MCU,ADIMa,ADIMb,AHL_AFL,AHS,ARS,BSM,VECM,VICM,BSM_MH,CGM,DCM,DMS,ECM,ECP_MC,EOCM,EOCM_HC_Superset,EPSRAa,EPS,EPSb,FCM,FOPM,HUD_CAN,LIB1,NVM,E44,PCM,RDCM,TCCM,TCM,VDM,ECP_E,ECP_S,ECP_S2,ECP_X1

BO_ 1445 EB_PDU_2000: 1 Vector__XXX
 SG_ CustmStbCtlRdctReqConf : 7|2@0+ (1,0) [0|2] "" EBCM

BO_ 1413 EB_PDU_2001: 1 Vector__XXX
 SG_ TrlrConnStat : 7|1@0+ (1,0) [0|1] "" ACP2_MCU,ADIMa,ADIMb,AHL_AFL,EBCM,ECM,EOCM,EOCM_HC_Superset,FCM,PCM,ECP_E

BO_ 707 EB_PDU_2002: 1 Vector__XXX
 SG_ EGI5_Eng12vStrtrMtrCmmdOn : 7|1@0+ (1,0) [0|1] "" DCM,EBCM,PCM,RDCM,TCCM,TCM,ECP_X1

BO_ 2147745800 Message0210_PDU: 1 Vector__XXX
 SG_ Sig2502 : 7|1@0+ (1,0) [0|1] "" CGM

BO_ 273 ECM_NM_PDU_On_CAN_2_Cluster: 8 Vector__XXX
 SG_ ISignal_ECM_CAN_2_Cluster : 23|48@0+ (1,0) [0|281474976710655] "" ACP2_MCU,ADIMa,ADIMb,AHL_AFL,AHS,ARS,BSM,VECM,VICM,BSM_MH,CGM,DCM,DMS,EBCM,ECP_MC,EOCM,EOCM_HC_Superset,EPSRAa,EPS,EPSb,FCM,FOPM,HUD_CAN,LIB1,NVM,E44,PCM,RDCM,TCCM,TCM,VDM,ECP_E,ECP_S,ECP_S2,ECP_X1

BO_ 2147745801 ECP_E_CAN2_ClscCANHrtBtActv_PDU: 1 Vector__XXX
 SG_ ECP_E_CAN2_ClscCANHrtBtActv : 7|1@0+ (1,0) [0|1] "" CGM

BO_ 279 ECP_E_NM_PDU_On_CAN_2_Cluster: 8 Vector__XXX
 SG_ ISignal_ECP_E_CAN_2_Cluster : 23|48@0+ (1,0) [0|281474976710655] "" ACP2_MCU,ADIMa,ADIMb,AHL_AFL,AHS,ARS,BSM,VECM,VICM,BSM_MH,CGM,DCM,DMS,EBCM,ECM,ECP_MC,EOCM,EOCM_HC_Superset,EPSRAa,EPS,EPSb,FCM,FOPM,HUD_CAN,LIB1,NVM,E44,PCM,RDCM,TCCM,TCM,VDM,ECP_S,ECP_S2,ECP_X1

BO_ 2147745816 Message0213_PDU: 1 Vector__XXX
 SG_ Sig2506 : 7|1@0+ (1,0) [0|1] "" CGM

BO_ 2147745815 Message0214_PDU: 1 Vector__XXX
 SG_ Sig2507 : 7|1@0+ (1,0) [0|1] "" CGM

BO_ 286 ECP_S2_NM_PDU_On_CAN_2_Cluster: 8 Vector__XXX
 SG_ ISignal_ECP_S2_CAN_2_Cluster : 23|48@0+ (1,0) [0|281474976710655] "" ACP2_MCU,ADIMa,ADIMb,AHL_AFL,AHS,ARS,BSM,VECM,VICM,BSM_MH,CGM,DCM,DMS,EBCM,ECM,ECP_MC,EOCM,EOCM_HC_Superset,EPSRAa,EPS,EPSb,FCM,FOPM,HUD_CAN,LIB1,NVM,E44,PCM,RDCM,TCCM,TCM,VDM,ECP_E,ECP_X1

BO_ 2147745802 Message0216_PDU: 1 Vector__XXX
 SG_ Sig2509 : 7|1@0+ (1,0) [0|1] "" CGM

BO_ 285 ECP_S_NM_PDU_On_CAN_2_Cluster: 8 Vector__XXX
 SG_ ISignal_ECP_S_CAN_2_Cluster : 23|48@0+ (1,0) [0|281474976710655] "" ACP2_MCU,ADIMa,ADIMb,AHL_AFL,AHS,ARS,BSM,VECM,VICM,BSM_MH,CGM,DCM,DMS,EBCM,ECM,ECP_MC,EOCM,EOCM_HC_Superset,EPSRAa,EPS,EPSb,FCM,FOPM,HUD_CAN,LIB1,NVM,E44,PCM,RDCM,TCCM,TCM,VDM,ECP_E,ECP_S2,ECP_X1

BO_ 2147745803 Message0218_PDU: 1 Vector__XXX
 SG_ Sig2511 : 7|1@0+ (1,0) [0|1] "" CGM

BO_ 918 ELSDInfo_PCSM_PDU: 8 Vector__XXX
 SG_ ELSDInfo_PCSM : 7|64@0+ (1,0) [0|1.84467e+019] "" EBCM

BO_ 86 ELSDInfo_Prtctd_PDU: 5 Vector__XXX
 SG_ ELSDIP_MAC : 7|27@0+ (1,0) [0|1.34218e+008] "" EBCM
 SG_ ELSDIP_FCnt : 28|5@0+ (1,0) [0|31] "" EBCM
 SG_ ELSDIP_Filler : 34|3@0+ (1,0) [0|7] "" EBCM
 SG_ ELSDIP_ARC : 36|2@0+ (1,0) [0|3] "" EBCM
 SG_ ELSDIP_ActrStsAuth : 39|3@0+ (1,0) [0|4] "" ADIMa,ADIMb,EBCM,ECP_E

BO_ 671 EOCMGnrlInfo1_PCSM_PDU: 8 Vector__XXX
 SG_ EOCMGnrlInfo1_PCSM : 7|64@0+ (1,0) [0|1.84467e+019] "" Vector__XXX

BO_ 528 EOCMGnrlInfo1_Prtctd_PDU: 12 Vector__XXX
 SG_ FIMRIMABP_MAC : 7|32@0+ (1,0) [0|4.29497e+009] "" Vector__XXX
 SG_ FIMRIMABP_FCnt : 39|5@0+ (1,0) [0|31] "" Vector__XXX
 SG_ FIMRIMABP_BrkgCtlAccelAuth : 47|12@0+ (0.01,-20.48) [-20.48|20.47] "" Vector__XXX
 SG_ FIMRIMABP_BrkgLongAccelReqAuth : 51|9@0- (0.1,0) [-25.6|25.5] "" Vector__XXX
 SG_ FIMRIMABP_FIMCISAutBrkRqTypAuth : 57|2@0+ (1,0) [0|2] "" Vector__XXX
 SG_ FIMRIMABP_BrkgReqAuth : 58|1@0+ (1,0) [0|1] "" Vector__XXX
 SG_ RIMATRP_TrqRqstAuth : 68|16@0- (2,0) [-65536|65534] "" Vector__XXX
 SG_ RIMATRP_TrqRqstActAuth : 69|1@0+ (1,0) [0|1] "" Vector__XXX
 SG_ FIMRIMABP_ReqActvAuth : 70|1@0+ (1,0) [0|1] "" Vector__XXX
 SG_ FIMRIMABP_RIMAutoBrkgReqTypAuth : 71|1@0+ (1,0) [0|1] "" Vector__XXX
 SG_ EOCMGI1P_Filler : 82|11@0+ (1,0) [0|2047] "" Vector__XXX
 SG_ FIMRIMABP_ARC : 84|2@0+ (1,0) [0|3] "" Vector__XXX

BO_ 1401 EOCMGnrlInfo2_PCSM_PDU: 8 Vector__XXX
 SG_ EOCMGnrlInfo2_PCSM : 7|64@0+ (1,0) [0|1.84467e+019] "" Vector__XXX

BO_ 613 EOCMGnrlInfo2_Prtctd_PDU: 8 Vector__XXX
 SG_ EOCMGI2P_MAC : 7|27@0+ (1,0) [0|1.34218e+008] "" Vector__XXX
 SG_ EOCMGI2P_FCnt : 28|5@0+ (1,0) [0|31] "" Vector__XXX
 SG_ EOCMGI2P_OSTmSyncMstrClckAuth : 39|32@0+ (1,0) [0|4.29497e+009] "ms" Vector__XXX

BO_ 2147745797 Message0227_PDU: 1 Vector__XXX
 SG_ Sig2535 : 7|1@0+ (1,0) [0|1] "" CGM

BO_ 2147745798 Message0230_PDU: 1 Vector__XXX
 SG_ Sig2538 : 7|1@0+ (1,0) [0|1] "" CGM

BO_ 2147745819 Message0234_PDU: 1 Vector__XXX
 SG_ Sig2542 : 7|1@0+ (1,0) [0|1] "" CGM

BO_ 305 EPSRAa_NM_PDU_On_CAN_2_Cluster: 8 Vector__XXX
 SG_ ISignal_EPSRAa_CAN_2_Cluster : 23|48@0+ (1,0) [0|281474976710655] "" ACP2_MCU,ADIMa,ADIMb,AHL_AFL,AHS,ARS,BSM,VECM,VICM,BSM_MH,CGM,DCM,DMS,EBCM,ECM,ECP_MC,EOCM,EOCM_HC_Superset,EPSb,FCM,FOPM,HUD_CAN,LIB1,NVM,E44,PCM,RDCM,TCCM,TCM,VDM,ECP_E,ECP_S,ECP_S2,ECP_X1

BO_ 2147745817 EPS_CAN2_ClscCANHrtBtActv_PDU: 1 Vector__XXX
 SG_ EPS_CAN2_ClscCANHrtBtActv : 7|1@0+ (1,0) [0|1] "" CGM

BO_ 2147745818 Message0238_PDU: 1 Vector__XXX
 SG_ Sig2546 : 7|1@0+ (1,0) [0|1] "" CGM

BO_ 1389 ElecShftRngSecDisp_PCSM_PDU: 8 Vector__XXX
 SG_ ElecShftRngSecDisp_PCSM : 7|64@0+ (1,0) [0|1.84467e+019] "" Vector__XXX

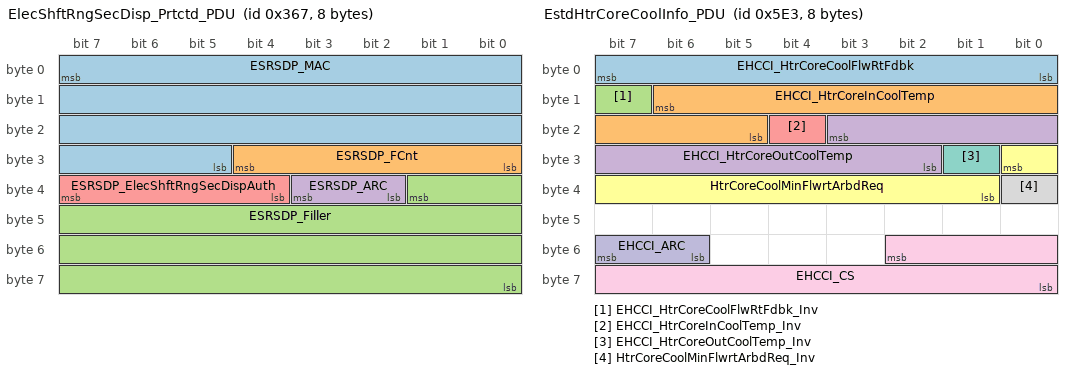
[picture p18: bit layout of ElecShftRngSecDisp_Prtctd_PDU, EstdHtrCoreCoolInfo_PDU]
BO_ 871 ElecShftRngSecDisp_Prtctd_PDU: 8 Vector__XXX
 SG_ ESRSDP_MAC : 7|27@0+ (1,0) [0|1.34218e+008] "" Vector__XXX
 SG_ ESRSDP_FCnt : 28|5@0+ (1,0) [0|31] "" Vector__XXX
 SG_ ESRSDP_Filler : 33|26@0+ (1,0) [0|6.71089e+007] "" Vector__XXX
 SG_ ESRSDP_ARC : 35|2@0+ (1,0) [0|3] "" Vector__XXX
 SG_ ESRSDP_ElecShftRngSecDispAuth : 39|4@0+ (1,0) [0|12] "" Vector__XXX

BO_ 1388 EnhdSrvsVhTpSp_PCSM_PDU: 8 Vector__XXX
 SG_ EnhdSrvsVhTpSp_PCSM : 7|64@0+ (1,0) [0|1.84467e+019] "" ECM,PCM,ECP_E

BO_ 869 EnhdSrvsVhTpSp_Prtctd_PDU: 6 Vector__XXX
 SG_ ESVTSP_MAC : 7|27@0+ (1,0) [0|1.34218e+008] "" ECM,PCM,ECP_E
 SG_ ESVTSP_FCnt : 28|5@0+ (1,0) [0|31] "" ECM,PCM,ECP_E
 SG_ ESVTSP_EnhdSrvsVhTpSpLimValAuth : 37|8@0+ (2,0) [0|510] "km/h" ECM,PCM,ECP_E
 SG_ ESVTSP_EnhdSrvsVhTpSpLimReqAuth : 39|2@0+ (1,0) [0|2] "" ECM,PCM,ECP_E
 SG_ ESVTSP_ARC : 45|2@0+ (1,0) [0|3] "" ECM,PCM,ECP_E

BO_ 1507 EstdHtrCoreCoolInfo_PDU: 8 Vector__XXX
 SG_ EHCCI_HtrCoreCoolFlwRtFdbk : 7|8@0+ (0.2509,0) [0|63.9795] "l/min" Vector__XXX
 SG_ EHCCI_HtrCoreInCoolTemp : 14|10@0+ (0.1857,-40) [-40|149.971] "degC" Vector__XXX
 SG_ EHCCI_HtrCoreCoolFlwRtFdbk_Inv : 15|1@0+ (1,0) [0|1] "" Vector__XXX
 SG_ EHCCI_HtrCoreOutCoolTemp : 19|10@0+ (0.1857,-40) [-40|149.971] "degC" Vector__XXX
 SG_ EHCCI_HtrCoreInCoolTemp_Inv : 20|1@0+ (1,0) [0|1] "" Vector__XXX
 SG_ HtrCoreCoolMinFlwrtArbdReq : 24|8@0+ (0.2509,0) [0|63.9795] "LPM" Vector__XXX
 SG_ EHCCI_HtrCoreOutCoolTemp_Inv : 25|1@0+ (1,0) [0|1] "" Vector__XXX
 SG_ HtrCoreCoolMinFlwrtArbdReq_Inv : 32|1@0+ (1,0) [0|1] "" Vector__XXX
 SG_ EHCCI_CS : 50|11@0+ (1,0) [0|2047] "" Vector__XXX
 SG_ EHCCI_ARC : 55|2@0+ (1,0) [0|3] "" Vector__XXX

BO_ 1387 ExtLgtWshWprInfo_PCSM_PDU: 8 Vector__XXX
 SG_ ExtLgtWshWprInfo_PCSM : 7|64@0+ (1,0) [0|1.84467e+019] "" ACP2_MCU,EOCM,EOCM_HC_Superset,FCM

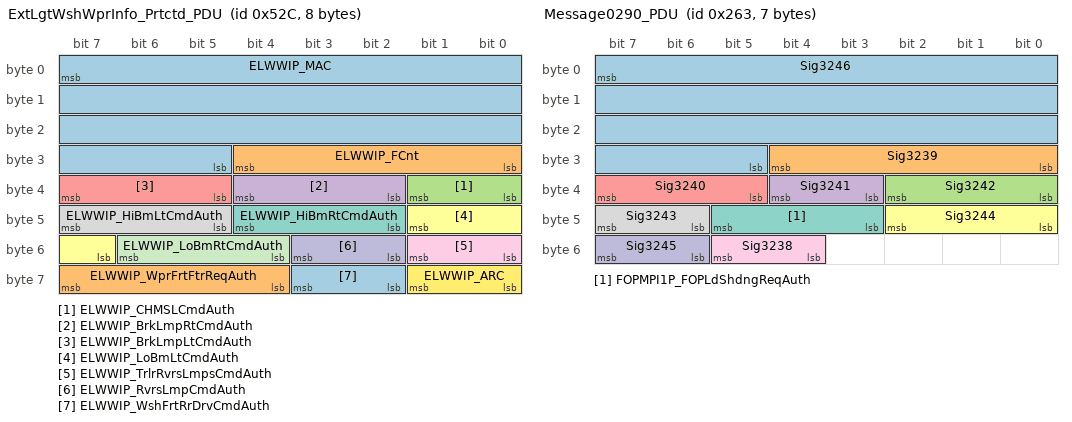
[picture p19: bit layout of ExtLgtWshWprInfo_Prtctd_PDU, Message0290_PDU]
BO_ 1324 ExtLgtWshWprInfo_Prtctd_PDU: 8 Vector__XXX
 SG_ ELWWIP_MAC : 7|27@0+ (1,0) [0|1.34218e+008] "" ACP2_MCU,EOCM,EOCM_HC_Superset,FCM
 SG_ ELWWIP_FCnt : 28|5@0+ (1,0) [0|31] "" ACP2_MCU,EOCM,EOCM_HC_Superset,FCM
 SG_ ELWWIP_CHMSLCmdAuth : 33|2@0+ (1,0) [0|3] "" ACP2_MCU,EOCM,EOCM_HC_Superset,FCM
 SG_ ELWWIP_BrkLmpRtCmdAuth : 36|3@0+ (1,0) [0|4] "" ACP2_MCU,EOCM,EOCM_HC_Superset,FCM
 SG_ ELWWIP_BrkLmpLtCmdAuth : 39|3@0+ (1,0) [0|4] "" ACP2_MCU,EOCM,EOCM_HC_Superset,FCM
 SG_ ELWWIP_LoBmLtCmdAuth : 41|3@0+ (1,0) [0|5] "" ACP2_MCU,EOCM,EOCM_HC_Superset,FCM
 SG_ ELWWIP_HiBmRtCmdAuth : 44|3@0+ (1,0) [0|5] "" ACP2_MCU,AHL_AFL,EOCM,EOCM_HC_Superset,FCM
 SG_ ELWWIP_HiBmLtCmdAuth : 47|3@0+ (1,0) [0|5] "" ACP2_MCU,AHL_AFL,EOCM,EOCM_HC_Superset,FCM
 SG_ ELWWIP_TrlrRvrsLmpsCmdAuth : 49|2@0+ (1,0) [0|2] "" ACP2_MCU,EOCM,EOCM_HC_Superset,FCM
 SG_ ELWWIP_RvrsLmpCmdAuth : 51|2@0+ (1,0) [0|2] "" ACP2_MCU,EOCM,EOCM_HC_Superset,FCM
 SG_ ELWWIP_LoBmRtCmdAuth : 54|3@0+ (1,0) [0|5] "" ACP2_MCU,EOCM,EOCM_HC_Superset,FCM
 SG_ ELWWIP_ARC : 57|2@0+ (1,0) [0|3] "" ACP2_MCU,EOCM,EOCM_HC_Superset,FCM
 SG_ ELWWIP_WshFrtRrDrvCmdAuth : 59|2@0+ (1,0) [0|3] "" ACP2_MCU,EOCM,EOCM_HC_Superset,FCM,NVM
 SG_ ELWWIP_WprFrtFtrReqAuth : 63|4@0+ (1,0) [0|12] "" ACP2_MCU,AHL_AFL,EBCM,EOCM,EOCM_HC_Superset,FCM

BO_ 2147745820 Message0267_PDU: 1 Vector__XXX
 SG_ Sig3206 : 7|1@0+ (1,0) [0|1] "" CGM

BO_ 2147745804 Message0269_PDU: 1 Vector__XXX
 SG_ Sig3257 : 7|1@0+ (1,0) [0|1] "" CGM

BO_ 485 FOPM_NM_PDU_On_CAN_2_Cluster: 8 Vector__XXX
 SG_ ISignal_FOPM_CAN_2_Cluster : 23|48@0+ (1,0) [0|281474976710655] "" ACP2_MCU,ADIMa,ADIMb,AHL_AFL,AHS,ARS,BSM,VECM,VICM,BSM_MH,CGM,DCM,DMS,EBCM,ECM,ECP_MC,EOCM,EOCM_HC_Superset,EPSRAa,EPS,EPSb,FCM,HUD_CAN,LIB1,NVM,E44,PCM,RDCM,TCCM,TCM,VDM,ECP_E,ECP_S,ECP_S2,ECP_X1

BO_ 1386 Message0289_PDU: 8 Vector__XXX
 SG_ Sig3400 : 7|64@0+ (1,0) [0|1.84467e+019] "" ADIMa,ADIMb

BO_ 611 Message0290_PDU: 7 Vector__XXX
 SG_ Sig3246 : 7|27@0+ (1,0) [0|1.34218e+008] "" ADIMa,ADIMb
 SG_ Sig3239 : 28|5@0+ (1,0) [0|31] "" ADIMa,ADIMb
 SG_ Sig3242 : 34|3@0+ (1,0) [0|5] "" ADIMa,ADIMb
 SG_ Sig3241 : 36|2@0+ (1,0) [0|3] "" ADIMa,ADIMb
 SG_ Sig3240 : 39|3@0+ (1,0) [0|5] "" ADIMa,ADIMb
 SG_ Sig3244 : 42|3@0+ (1,0) [0|5] "" ADIMa,ADIMb
 SG_ FOPMPI1P_FOPLdShdngReqAuth : 45|3@0+ (1,0) [0|4] "" ADIMa,ADIMb,CGM
 SG_ Sig3243 : 47|2@0+ (1,0) [0|3] "" ADIMa,ADIMb
 SG_ Sig3238 : 53|2@0+ (1,0) [0|3] "" ADIMa,ADIMb
 SG_ Sig3245 : 55|2@0+ (1,0) [0|3] "" ADIMa,ADIMb

BO_ 1508 Message0293_PDU: 8 Vector__XXX
 SG_ Sig3230 : 7|8@0+ (0.3921,0) [0|99.9855] "%" CGM
 SG_ Sig3232 : 14|8@0+ (0.3921,0) [0|99.9855] "%" CGM
 SG_ Sig3231 : 15|1@0+ (1,0) [0|1] "" CGM
 SG_ Sig3233 : 22|1@0+ (1,0) [0|1] "" CGM
 SG_ Sig3229 : 50|11@0+ (1,0) [0|2047] "" CGM
 SG_ Sig3228 : 55|2@0+ (1,0) [0|3] "" CGM

BA_DEF_ SG_  "SignalType" STRING ;
BA_DEF_ SG_  "SignalLongName" STRING ;
BA_DEF_ BO_  "GenMsgCycleTime" INT 0 10000;
BA_DEF_ BO_  "GenMsgSendType" ENUM "cyclicX","spontanX","cyclicIfActiveX","spontanWithDelay","cyclicAndSpontanX","cyclicAndSpontanWithDelay","spontanWithRepetition","cyclicIfActiveAndSpontanWD";
BA_DEF_ BO_  "VFrameFormat" ENUM  "StandardCAN","ExtendedCAN","reserved","reserved","reserved","reserved","reserved","reserved","reserved","reserved","reserved","reserved","reserved","reserved","StandardCAN_FD","ExtendedCAN_FD";
BA_DEF_DEF_  "SignalType" "";
BA_DEF_DEF_  "SignalLongName" "";
BA_DEF_DEF_  "GenMsgCycleTime" 0;
BA_DEF_DEF_  "GenMsgSendType" "cyclicX";
BA_DEF_DEF_  "VFrameFormat" "StandardCAN";
BA_ "GenMsgCycleTime" BO_ 70 10;
BA_ "VFrameFormat" BO_ 70 14;
BA_ "VFrameFormat" BO_ 699 14;
BA_ "GenMsgCycleTime" BO_ 78 10;
BA_ "VFrameFormat" BO_ 78 14;
BA_ "GenMsgCycleTime" BO_ 1498 1000;
BA_ "VFrameFormat" BO_ 1498 14;
BA_ "VFrameFormat" BO_ 698 14;
BA_ "GenMsgCycleTime" BO_ 68 10;
BA_ "VFrameFormat" BO_ 68 14;
BA_ "GenMsgCycleTime" BO_ 1367 3500;
BA_ "VFrameFormat" BO_ 1367 14;
BA_ "GenMsgCycleTime" BO_ 1307 1000;
BA_ "VFrameFormat" BO_ 1307 14;
BA_ "GenMsgCycleTime" BO_ 2147745799 1000;
BA_ "GenMsgCycleTime" BO_ 1255 1000;
BA_ "VFrameFormat" BO_ 1255 14;
BA_ "GenMsgCycleTime" BO_ 2147745812 1000;
BA_ "VFrameFormat" BO_ 923 14;
BA_ "GenMsgCycleTime" BO_ 62 10;
BA_ "VFrameFormat" BO_ 62 14;
BA_ "GenMsgCycleTime" BO_ 1405 1000;
BA_ "VFrameFormat" BO_ 1405 14;
BA_ "GenMsgCycleTime" BO_ 880 250;
BA_ "VFrameFormat" BO_ 880 14;
BA_ "GenMsgCycleTime" BO_ 1391 3500;
BA_ "VFrameFormat" BO_ 1391 14;
BA_ "GenMsgCycleTime" BO_ 1301 1000;
BA_ "VFrameFormat" BO_ 1301 14;
BA_ "VFrameFormat" BO_ 922 14;
BA_ "GenMsgCycleTime" BO_ 108 20;
BA_ "VFrameFormat" BO_ 108 14;
BA_ "VFrameFormat" BO_ 921 14;
BA_ "GenMsgCycleTime" BO_ 98 12.5;
BA_ "VFrameFormat" BO_ 98 14;
BA_ "VFrameFormat" BO_ 691 14;
BA_ "GenMsgCycleTime" BO_ 66 10;
BA_ "VFrameFormat" BO_ 66 14;
BA_ "VFrameFormat" BO_ 696 14;
BA_ "GenMsgCycleTime" BO_ 51 12.5;
BA_ "VFrameFormat" BO_ 51 14;
BA_ "GenMsgCycleTime" BO_ 1506 1000;
BA_ "VFrameFormat" BO_ 1506 14;
BA_ "GenMsgCycleTime" BO_ 2147745813 1000;
BA_ "GenMsgCycleTime" BO_ 2147745814 1000;
BA_ "GenMsgCycleTime" BO_ 1530 1000;
BA_ "VFrameFormat" BO_ 1530 14;
BA_ "GenMsgCycleTime" BO_ 1531 1000;
BA_ "VFrameFormat" BO_ 1531 14;
BA_ "GenMsgCycleTime" BO_ 1532 1000;
BA_ "VFrameFormat" BO_ 1532 14;
BA_ "GenMsgCycleTime" BO_ 1533 1000;
BA_ "VFrameFormat" BO_ 1533 14;
BA_ "GenMsgCycleTime" BO_ 1276 1000;
BA_ "VFrameFormat" BO_ 1276 14;
BA_ "GenMsgCycleTime" BO_ 1275 1000;
BA_ "VFrameFormat" BO_ 1275 14;
BA_ "GenMsgCycleTime" BO_ 1274 1000;
BA_ "VFrameFormat" BO_ 1274 14;
BA_ "GenMsgCycleTime" BO_ 1792 1000;
BA_ "VFrameFormat" BO_ 1792 14;
BA_ "GenMsgCycleTime" BO_ 1793 1000;
BA_ "VFrameFormat" BO_ 1793 14;
BA_ "GenMsgCycleTime" BO_ 1272 1000;
BA_ "VFrameFormat" BO_ 1272 14;
BA_ "GenMsgCycleTime" BO_ 1273 1000;
BA_ "VFrameFormat" BO_ 1273 14;
BA_ "GenMsgCycleTime" BO_ 1794 1000;
BA_ "VFrameFormat" BO_ 1794 14;
BA_ "GenMsgCycleTime" BO_ 1271 1000;
BA_ "VFrameFormat" BO_ 1271 14;
BA_ "GenMsgCycleTime" BO_ 1795 1000;
BA_ "VFrameFormat" BO_ 1795 14;
BA_ "GenMsgCycleTime" BO_ 1270 1000;
BA_ "VFrameFormat" BO_ 1270 14;
BA_ "GenMsgCycleTime" BO_ 1796 1000;
BA_ "VFrameFormat" BO_ 1796 14;
BA_ "GenMsgCycleTime" BO_ 1269 1000;
BA_ "VFrameFormat" BO_ 1269 14;
BA_ "GenMsgCycleTime" BO_ 1797 1000;
BA_ "VFrameFormat" BO_ 1797 14;
BA_ "GenMsgCycleTime" BO_ 1025 1000;
BA_ "VFrameFormat" BO_ 1025 14;
BA_ "GenMsgCycleTime" BO_ 1268 1000;
BA_ "VFrameFormat" BO_ 1268 14;
BA_ "GenMsgCycleTime" BO_ 1798 1000;
BA_ "VFrameFormat" BO_ 1798 14;
BA_ "GenMsgCycleTime" BO_ 1173 1000;
BA_ "VFrameFormat" BO_ 1173 14;
BA_ "GenMsgCycleTime" BO_ 1267 1000;
BA_ "VFrameFormat" BO_ 1267 14;
BA_ "GenMsgCycleTime" BO_ 1799 1000;
BA_ "VFrameFormat" BO_ 1799 14;
BA_ "GenMsgCycleTime" BO_ 1266 1000;
BA_ "VFrameFormat" BO_ 1266 14;
BA_ "GenMsgCycleTime" BO_ 1473 1000;
BA_ "VFrameFormat" BO_ 1473 14;
BA_ "GenMsgCycleTime" BO_ 1474 1000;
BA_ "VFrameFormat" BO_ 1474 14;
BA_ "GenMsgCycleTime" BO_ 1800 1000;
BA_ "VFrameFormat" BO_ 1800 14;
BA_ "GenMsgCycleTime" BO_ 1390 1000;
BA_ "VFrameFormat" BO_ 1390 14;
BA_ "GenMsgCycleTime" BO_ 872 250;
BA_ "VFrameFormat" BO_ 872 14;
BA_ "VFrameFormat" BO_ 920 14;
BA_ "GenMsgCycleTime" BO_ 186 50;
BA_ "VFrameFormat" BO_ 186 14;
BA_ "VFrameFormat" BO_ 919 14;
BA_ "GenMsgCycleTime" BO_ 624 100;
BA_ "VFrameFormat" BO_ 624 14;
BA_ "GenMsgCycleTime" BO_ 2147745840 1000;
BA_ "GenMsgCycleTime" BO_ 2147745795 1000;
BA_ "GenMsgCycleTime" BO_ 2147745796 1000;
BA_ "VFrameFormat" BO_ 1445 14;
BA_ "VFrameFormat" BO_ 1413 14;
BA_ "VFrameFormat" BO_ 707 14;
BA_ "GenMsgCycleTime" BO_ 2147745800 1000;
BA_ "GenMsgCycleTime" BO_ 2147745801 1000;
BA_ "GenMsgCycleTime" BO_ 2147745816 1000;
BA_ "GenMsgCycleTime" BO_ 2147745815 1000;
BA_ "GenMsgCycleTime" BO_ 2147745802 1000;
BA_ "GenMsgCycleTime" BO_ 2147745803 1000;
BA_ "VFrameFormat" BO_ 918 14;
BA_ "GenMsgCycleTime" BO_ 86 10;
BA_ "VFrameFormat" BO_ 86 14;
BA_ "VFrameFormat" BO_ 671 14;
BA_ "GenMsgCycleTime" BO_ 528 50;
BA_ "VFrameFormat" BO_ 528 14;
BA_ "VFrameFormat" BO_ 1401 14;
BA_ "GenMsgCycleTime" BO_ 613 100;
BA_ "VFrameFormat" BO_ 613 14;
BA_ "GenMsgCycleTime" BO_ 2147745797 1000;
BA_ "GenMsgCycleTime" BO_ 2147745798 1000;
BA_ "GenMsgCycleTime" BO_ 2147745819 1000;
BA_ "GenMsgCycleTime" BO_ 2147745817 1000;
BA_ "GenMsgCycleTime" BO_ 2147745818 1000;
BA_ "GenMsgCycleTime" BO_ 1389 1000;
BA_ "VFrameFormat" BO_ 1389 14;
BA_ "GenMsgCycleTime" BO_ 871 250;
BA_ "VFrameFormat" BO_ 871 14;
BA_ "GenMsgCycleTime" BO_ 1388 1000;
BA_ "VFrameFormat" BO_ 1388 14;
BA_ "GenMsgCycleTime" BO_ 869 250;
BA_ "VFrameFormat" BO_ 869 14;
BA_ "GenMsgCycleTime" BO_ 1507 1000;
BA_ "VFrameFormat" BO_ 1507 14;
BA_ "GenMsgCycleTime" BO_ 1387 3500;
BA_ "VFrameFormat" BO_ 1387 14;
BA_ "GenMsgCycleTime" BO_ 1324 1000;
BA_ "VFrameFormat" BO_ 1324 14;
BA_ "GenMsgCycleTime" BO_ 2147745820 1000;
BA_ "GenMsgCycleTime" BO_ 2147745804 1000;
BA_ "VFrameFormat" BO_ 1386 14;
BA_ "GenMsgCycleTime" BO_ 611 100;
BA_ "VFrameFormat" BO_ 611 14;
BA_ "GenMsgCycleTime" BO_ 1508 1000;
BA_ "VFrameFormat" BO_ 1508 14;
BA_ "SignalLongName" SG_ 70 ABSMPI1P_MAC "Autonomous Brake System Main Primary Information 1 Protected : MAC";
BA_ "SignalLongName" SG_ 70 ABSMPI1P_FCnt "Autonomous Brake System Main Primary Information 1 Protected : Freshness Counter";
BA_ "SignalType" SG_ 70 ABSMPI1P_BrkModStsAuth "ENM";
BA_ "SignalLongName" SG_ 70 ABSMPI1P_BrkModStsAuth "Autonomous Brake System Main Primary Information 1 Protected : Brake Module Status Authenticated";
BA_ "SignalLongName" SG_ 70 ABSMPI1P_FillerExtnd "Autonomous Brake System Main Primary Information 1 Protected : Filler Extended";
BA_ "SignalType" SG_ 70 ABSMPI1P_ADIMCmdMsgStsAuth "ENM";
BA_ "SignalLongName" SG_ 70 ABSMPI1P_ADIMCmdMsgStsAuth "Autonomous Brake System Main Primary Information 1 Protected : Automated Driving Interface Module Command Message Status Authenticated";
BA_ "SignalType" SG_ 70 ABSMPI1P_ABSStsAuth "ENM";
BA_ "SignalLongName" SG_ 70 ABSMPI1P_ABSStsAuth "Autonomous Brake System Main Primary Information 1 Protected : Antilock Brake System Status Authenticated";
BA_ "SignalType" SG_ 70 ABSMPI1P_DiagBrkPresReqStsAuth "ENM";
BA_ "SignalLongName" SG_ 70 ABSMPI1P_DiagBrkPresReqStsAuth "Autonomous Brake System Main Primary Information 1 Protected : Diagnostic Brake Pressure Request Status Authenticated";
BA_ "SignalType" SG_ 70 ABSMPI1P_DiagBrkPresReqAvalAuth "ENM";
BA_ "SignalLongName" SG_ 70 ABSMPI1P_DiagBrkPresReqAvalAuth "Autonomous Brake System Main Primary Information 1 Protected : Diagnostic Brake Pressure Request Available Authenticated";
BA_ "SignalType" SG_ 70 ABSMPI1P_BrkTrqSfcntStndstlAuth "ENM";
BA_ "SignalLongName" SG_ 70 ABSMPI1P_BrkTrqSfcntStndstlAuth "Autonomous Brake System Main Primary Information 1 Protected : Brake Torque Sufficient for Standstill Authenticated";
BA_ "SignalType" SG_ 70 ABSMPI1P_BrkSysStsAuth "ENM";
BA_ "SignalLongName" SG_ 70 ABSMPI1P_BrkSysStsAuth "Autonomous Brake System Main Primary Information 1 Protected : Brake System Status Authenticated";
BA_ "SignalLongName" SG_ 70 ABSMPI1P_EstdSrfcFCoefCapAuth "Autonomous Brake System Main Primary Information 1 Protected : Estimated Surface Force Coefficient Capacity Authenticated";
BA_ "SignalType" SG_ 70 ABSMPI1P_ElecBrkDstSysStsAuth "ENM";
BA_ "SignalLongName" SG_ 70 ABSMPI1P_ElecBrkDstSysStsAuth "Autonomous Brake System Main Primary Information 1 Protected : Electronic Brake Distribution System Status Authenticated";
BA_ "SignalType" SG_ 70 ABSMPI1P_ESCSysStsAuth "ENM";
BA_ "SignalLongName" SG_ 70 ABSMPI1P_ESCSysStsAuth "Autonomous Brake System Main Primary Information 1 Protected : Electronic Stability Control System Status Authenticated";
BA_ "SignalLongName" SG_ 70 ABSMPI1P_MxAvlBrkTqAuth "Autonomous Brake System Main Primary Information 1 Protected : Maximum Available Brake Torque Authenticated";
BA_ "SignalType" SG_ 70 ABSMPI1P_EstdSrfcFCoefTypAuth "ENM";
BA_ "SignalLongName" SG_ 70 ABSMPI1P_EstdSrfcFCoefTypAuth "Autonomous Brake System Main Primary Information 1 Protected : Estimated Surface Force Coefficient Type Authenticated";
BA_ "SignalLongName" SG_ 70 ABSMPI1P_MxAvlBrkTqGradAuth "Autonomous Brake System Main Primary Information 1 Protected : Maximum Available Brake Torque Gradient Authenticated";
BA_ "SignalType" SG_ 70 ABSMPI1P_PBMSbsysStsPriAuth "ENM";
BA_ "SignalLongName" SG_ 70 ABSMPI1P_PBMSbsysStsPriAuth "Autonomous Brake System Main Primary Information 1 Protected : Primary Brake Module Subsystem Status Primary Authenticated";
BA_ "SignalType" SG_ 70 ABSMPI1P_PBMArbtrtnStsPriAuth "ENM";
BA_ "SignalLongName" SG_ 70 ABSMPI1P_PBMArbtrtnStsPriAuth "Autonomous Brake System Main Primary Information 1 Protected : Primary Brake Module Arbitration Status Primary Authenticated";
BA_ "SignalType" SG_ 70 ABSMPI1P_WhlBrkPresAuth_Inv "ENM";
BA_ "SignalLongName" SG_ 70 ABSMPI1P_WhlBrkPresAuth_Inv "Autonomous Brake System Main Primary Information 1 Protected : Wheel Brake Pressure Authenticated Invalid";
BA_ "SignalType" SG_ 70 ABSMPI1P_TCSStsAuth "ENM";
BA_ "SignalLongName" SG_ 70 ABSMPI1P_TCSStsAuth "Autonomous Brake System Main Primary Information 1 Protected : Traction Control System Status Authenticated";
BA_ "SignalType" SG_ 70 ABSMPI1P_StndstlHldReqStsAuth "ENM";
BA_ "SignalLongName" SG_ 70 ABSMPI1P_StndstlHldReqStsAuth "Autonomous Brake System Main Primary Information 1 Protected : Standstill Hold Request Status Authenticated";
BA_ "SignalType" SG_ 70 ABSMPI1P_SpltFCoefCtlAuth "ENM";
BA_ "SignalLongName" SG_ 70 ABSMPI1P_SpltFCoefCtlAuth "Autonomous Brake System Main Primary Information 1 Protected : Split Force Coefficient Control Authenticated";
BA_ "SignalType" SG_ 70 ABSMPI1P_SBMFltDtdByPBMPriAuth "ENM";
BA_ "SignalLongName" SG_ 70 ABSMPI1P_SBMFltDtdByPBMPriAuth "Autonomous Brake System Main Primary Information 1 Protected : Secondary Brake Module Fault Detected By Primary Brake Module Primary Authenticated";
BA_ "SignalLongName" SG_ 70 ABSMPI1P_WhlBrkPresLFAuth "Autonomous Brake System Main Primary Information 1 Protected : Wheel Brake Pressure Left Front Authenticated";
BA_ "SignalLongName" SG_ 70 ABSMPI1P_WhlBrkPresLRAuth "Autonomous Brake System Main Primary Information 1 Protected : Wheel Brake Pressure Left Rear Authenticated";
BA_ "SignalLongName" SG_ 70 ABSMPI1P_WhlBrkPresRFAuth "Autonomous Brake System Main Primary Information 1 Protected : Wheel Brake Pressure Right Front Authenticated";
BA_ "SignalLongName" SG_ 70 ABSMPI1P_WhlBrkPresRRAuth "Autonomous Brake System Main Primary Information 1 Protected : Wheel Brake Pressure Right Rear Authenticated";
BA_ "SignalLongName" SG_ 70 ABSMPI1P_Filler "Autonomous Brake System Main Primary Information 1 Protected : Filler";
BA_ "SignalType" SG_ 70 MnElecPrkBrkSwStsPriAuth "ENM";
BA_ "SignalLongName" SG_ 70 MnElecPrkBrkSwStsPriAuth "Autonomous Brake System Main Primary Information 1 Protected : Main Electric Park Brake Switch Status Primary Authenticated";
BA_ "SignalLongName" SG_ 70 ABSMPI1P_ARC "Autonomous Brake System Main Primary Information 1 Protected : Alive Rolling Count";
BA_ "SignalLongName" SG_ 699 AutoBrkSysRedntPriInfo1_PCSM "Autonomous Brake System Redundant Primary Information 1 Protected Counter Sync Message";
BA_ "SignalLongName" SG_ 78 ABSRPI1P_MAC "Autonomous Brake System Redundant Primary Information 1 Protected : MAC";
BA_ "SignalLongName" SG_ 78 ABSRPI1P_FCnt "Autonomous Brake System Redundant Primary Information 1 Protected : Freshness Counter";
BA_ "SignalType" SG_ 78 ABSRPI1P_BrkModStsAuth "ENM";
BA_ "SignalLongName" SG_ 78 ABSRPI1P_BrkModStsAuth "Autonomous Brake System Redundant Primary Information 1 Protected : Brake Module Status Authenticated";
BA_ "SignalLongName" SG_ 78 ABSRPI1P_FillerExtnd3 "Autonomous Brake System Redundant Primary Information 1 Protected : Filler Extended 3";
BA_ "SignalType" SG_ 78 ABSRPI1P_ADIMCmdMsgStsAuth "ENM";
BA_ "SignalLongName" SG_ 78 ABSRPI1P_ADIMCmdMsgStsAuth "Autonomous Brake System Redundant Primary Information 1 Protected : Automated Driving Interface Module Command Message Status Authenticated";
BA_ "SignalType" SG_ 78 ABSRPI1P_ABSStsAuth "ENM";
BA_ "SignalLongName" SG_ 78 ABSRPI1P_ABSStsAuth "Autonomous Brake System Redundant Primary Information 1 Protected : Antilock Brake System Status Authenticated";
BA_ "SignalLongName" SG_ 78 ABSRPI1P_CSImmedATRqValAuth "Autonomous Brake System Redundant Primary Information 1 Protected : Chassis System Immediate Axle Torque Request Value Authenticated";
BA_ "SignalType" SG_ 78 ABSRPI1P_BrkTrqSfcntStndstlAuth "ENM";
BA_ "SignalLongName" SG_ 78 ABSRPI1P_BrkTrqSfcntStndstlAuth "Autonomous Brake System Redundant Primary Information 1 Protected : Brake Torque Sufficient for Standstill Authenticated";
BA_ "SignalType" SG_ 78 ABSRPI1P_BrkSysStsAuth "ENM";
BA_ "SignalLongName" SG_ 78 ABSRPI1P_BrkSysStsAuth "Autonomous Brake System Redundant Primary Information 1 Protected : Brake System Status Authenticated";
BA_ "SignalType" SG_ 78 ABSRPI1P_BrkSysBrkLgtsReqdAuth "ENM";
BA_ "SignalLongName" SG_ 78 ABSRPI1P_BrkSysBrkLgtsReqdAuth "Autonomous Brake System Redundant Primary Information 1 Protected : Brake System Brake Lights Requested Authenticated";
BA_ "SignalLongName" SG_ 78 ABSRPI1P_CSPrdtdATRqValAuth "Autonomous Brake System Redundant Primary Information 1 Protected : Chassis System Predicted Axle Torque Request Value Authenticated";
BA_ "SignalType" SG_ 78 ABSRPI1P_CSPrdtdATRqIntvTypAuth "ENM";
BA_ "SignalLongName" SG_ 78 ABSRPI1P_CSPrdtdATRqIntvTypAuth "Autonomous Brake System Redundant Primary Information 1 Protected : Chassis System Predicted Axle Torque Request Intervention Type Authenticated";
BA_ "SignalType" SG_ 78 ABSRPI1P_ChsSysATRqFncAuth "ENM";
BA_ "SignalLongName" SG_ 78 ABSRPI1P_ChsSysATRqFncAuth "Autonomous Brake System Redundant Primary Information 1 Protected : Chassis System Axle Torque Request Function Authenticated";
BA_ "SignalLongName" SG_ 78 ABSRPI1P_ChsSysBrkBlndATRqAuth "Autonomous Brake System Redundant Primary Information 1 Protected : Chassis System Brake Blending Axle Torque Request Authenticated";
BA_ "SignalType" SG_ 78 ABSRPI1P_ChsSysATRqRespTypAuth "ENM";
BA_ "SignalLongName" SG_ 78 ABSRPI1P_ChsSysATRqRespTypAuth "Autonomous Brake System Redundant Primary Information 1 Protected : Chassis System Axle Torque Request Response Type Authenticated";
BA_ "SignalLongName" SG_ 78 ABSRPI1P_ChsSysTtBrkATAuth "Autonomous Brake System Redundant Primary Information 1 Protected : Chassis System Total Brake Axle Torque Authenticated";
BA_ "SignalLongName" SG_ 78 ABSRPI1P_DrvIntdTtBrkTqAuth "Autonomous Brake System Redundant Primary Information 1 Protected : Driver Intended Total Brake Torque Authenticated";
BA_ "SignalType" SG_ 78 ABSRPI1P_ChsSysTtBrkATAuth_Inv "ENM";
BA_ "SignalLongName" SG_ 78 ABSRPI1P_ChsSysTtBrkATAuth_Inv "Autonomous Brake System Redundant Primary Information 1 Protected : Chassis System Total Brake Axle Torque Authenticated Invalid";
BA_ "SignalType" SG_ 78 ABSRPI1P_ElcBrkDstSysStsAuth "ENM";
BA_ "SignalLongName" SG_ 78 ABSRPI1P_ElcBrkDstSysStsAuth "Autonomous Brake System Redundant Primary Information 1 Protected : Electronic Brake Distribution System Status Authenticated";
BA_ "SignalType" SG_ 78 ABSRPI1P_ESCSysStsAuth "ENM";
BA_ "SignalLongName" SG_ 78 ABSRPI1P_ESCSysStsAuth "Autonomous Brake System Redundant Primary Information 1 Protected : Electronic Stability Control System Status Authenticated";
BA_ "SignalLongName" SG_ 78 ABSRPI1P_EstdSrfcFCoefCapAuth "Autonomous Brake System Redundant Primary Information 1 Protected : Estimated Surface Force Coefficient Capacity Authenticated";
BA_ "SignalLongName" SG_ 78 ABSRPI1P_MxAvlBrkTqAuth "Autonomous Brake System Redundant Primary Information 1 Protected : Maximum Available Brake Torque Authenticated";
BA_ "SignalType" SG_ 78 ABSRPI1P_EstdSrfcFCoefTypAuth "ENM";
BA_ "SignalLongName" SG_ 78 ABSRPI1P_EstdSrfcFCoefTypAuth "Autonomous Brake System Redundant Primary Information 1 Protected : Estimated Surface Force Coefficient Type Authenticated";
BA_ "SignalLongName" SG_ 78 ABSRPI1P_MxAvlBrkTqGradAuth "Autonomous Brake System Redundant Primary Information 1 Protected : Maximum Available Brake Torque Gradient Authenticated";
BA_ "SignalType" SG_ 78 ABSRPI1P_SBMArbtrtnStsPriAuth "ENM";
BA_ "SignalLongName" SG_ 78 ABSRPI1P_SBMArbtrtnStsPriAuth "Autonomous Brake System Redundant Primary Information 1 Protected : Secondary Braking Module Arbitration Status Primary Authenticated";
BA_ "SignalType" SG_ 78 ABSRPI1P_PBMFltDtdBySBMPriAuth "ENM";
BA_ "SignalLongName" SG_ 78 ABSRPI1P_PBMFltDtdBySBMPriAuth "Autonomous Brake System Redundant Primary Information 1 Protected : Primary Brake Module Fault Detected By Secondary Brake Module Primary Authenticated";
BA_ "SignalType" SG_ 78 ABSRPI1P_StndstlHldRqStsAuth "ENM";
BA_ "SignalLongName" SG_ 78 ABSRPI1P_StndstlHldRqStsAuth "Autonomous Brake System Redundant Primary Information 1 Protected : Standstill Hold Request Status Authenticated";
BA_ "SignalType" SG_ 78 ABSRPI1P_SpltFCoefCtlAuth "ENM";
BA_ "SignalLongName" SG_ 78 ABSRPI1P_SpltFCoefCtlAuth "Autonomous Brake System Redundant Primary Information 1 Protected : Split Force Coefficient Control Authenticated";
BA_ "SignalType" SG_ 78 ABSRPI1P_SBMSbsysStsPriAuth "ENM";
BA_ "SignalLongName" SG_ 78 ABSRPI1P_SBMSbsysStsPriAuth "Autonomous Brake System Redundant Primary Information 1 Protected : Secondary Brake Module Subsystem Status Primary Authenticated";
BA_ "SignalLongName" SG_ 78 ABSRPI1P_WhlAnglrVelLFAuth "Autonomous Brake System Redundant Primary Information 1 Protected : Wheel Angular Velocity Left Front Authenticated";
BA_ "SignalType" SG_ 78 ABSRPI1P_TCSStsAuth "ENM";
BA_ "SignalLongName" SG_ 78 ABSRPI1P_TCSStsAuth "Autonomous Brake System Redundant Primary Information 1 Protected : Traction Control System Status Authenticated";
BA_ "SignalLongName" SG_ 78 ABSRPI1P_WhlAnglrVelLRAuth "Autonomous Brake System Redundant Primary Information 1 Protected : Wheel Angular Velocity Left Rear Authenticated";
BA_ "SignalType" SG_ 78 ABSRPI1P_WhlAnglrVelLFAuth_Inv "ENM";
BA_ "SignalLongName" SG_ 78 ABSRPI1P_WhlAnglrVelLFAuth_Inv "Autonomous Brake System Redundant Primary Information 1 Protected : Wheel Angular Velocity Left Front Authenticated Invalid";
BA_ "SignalLongName" SG_ 78 ABSRPI1P_WhlAnglrVelRFAuth "Autonomous Brake System Redundant Primary Information 1 Protected : Wheel Angular Velocity Right Front Authenticated";
BA_ "SignalType" SG_ 78 ABSRPI1P_WhlAnglrVelLRAuth_Inv "ENM";
BA_ "SignalLongName" SG_ 78 ABSRPI1P_WhlAnglrVelLRAuth_Inv "Autonomous Brake System Redundant Primary Information 1 Protected : Wheel Angular Velocity Left Rear Authenticated Invalid";
BA_ "SignalType" SG_ 78 ABSRPI1P_WhlAnglrVelRFAuth_Inv "ENM";
BA_ "SignalLongName" SG_ 78 ABSRPI1P_WhlAnglrVelRFAuth_Inv "Autonomous Brake System Redundant Primary Information 1 Protected : Wheel Angular Velocity Right Front Authenticated Invalid";
BA_ "SignalLongName" SG_ 78 ABSRPI1P_WhlAnglrVelRRAuth "Autonomous Brake System Redundant Primary Information 1 Protected : Wheel Angular Velocity Right Rear Authenticated";
BA_ "SignalLongName" SG_ 78 ABSRPI1P_WhlBrkPrsLFAuth "Autonomous Brake System Redundant Primary Information 1 Protected : Wheel Brake Pressure Left Front Authenticated";
BA_ "SignalType" SG_ 78 ABSRPI1P_WhlAnglrVelRRAuth_Inv "ENM";
BA_ "SignalLongName" SG_ 78 ABSRPI1P_WhlAnglrVelRRAuth_Inv "Autonomous Brake System Redundant Primary Information 1 Protected : Wheel Angular Velocity Right Rear Authenticated Invalid";
BA_ "SignalType" SG_ 78 ABSRPI1P_WhlBrkPrsLFAuth_Inv "ENM";
BA_ "SignalLongName" SG_ 78 ABSRPI1P_WhlBrkPrsLFAuth_Inv "Autonomous Brake System Redundant Primary Information 1 Protected : Wheel Brake Pressure Left Front Authenticated Invalid";
BA_ "SignalLongName" SG_ 78 ABSRPI1P_WhlBrkPrsLRAuth "Autonomous Brake System Redundant Primary Information 1 Protected : Wheel Brake Pressure Left Rear Authenticated";
BA_ "SignalLongName" SG_ 78 ABSRPI1P_WhlBrkPrsRFAuth "Autonomous Brake System Redundant Primary Information 1 Protected : Wheel Brake Pressure Right Front Authenticated";
BA_ "SignalType" SG_ 78 ABSRPI1P_WhlBrkPrsLRAuth_Inv "ENM";
BA_ "SignalLongName" SG_ 78 ABSRPI1P_WhlBrkPrsLRAuth_Inv "Autonomous Brake System Redundant Primary Information 1 Protected : Wheel Brake Pressure Left Rear Authenticated Invalid";
BA_ "SignalLongName" SG_ 78 ABSRPI1P_WhlBrkPrsRRAuth "Autonomous Brake System Redundant Primary Information 1 Protected : Wheel Brake Pressure Right Rear Authenticated";
BA_ "SignalType" SG_ 78 ABSRPI1P_WhlBrkPrsRFAuth_Inv "ENM";
BA_ "SignalLongName" SG_ 78 ABSRPI1P_WhlBrkPrsRFAuth_Inv "Autonomous Brake System Redundant Primary Information 1 Protected : Wheel Brake Pressure Right Front Authenticated Invalid";
BA_ "SignalLongName" SG_ 78 ABSRPI1P_Filler "Autonomous Brake System Redundant Primary Information 1 Protected : Filler";
BA_ "SignalLongName" SG_ 78 ABSRPI1P_ARC "Autonomous Brake System Redundant Primary Information 1 Protected : Alive Rolling Count";
BA_ "SignalType" SG_ 78 ABSRPI1P_WhlBrkPrsRRAuth_Inv "ENM";
BA_ "SignalLongName" SG_ 78 ABSRPI1P_WhlBrkPrsRRAuth_Inv "Autonomous Brake System Redundant Primary Information 1 Protected : Wheel Brake Pressure Right Rear Authenticated Invalid";
BA_ "SignalLongName" SG_ 78 ABSRPI1P_FillerExtnd "Autonomous Brake System Redundant Primary Information 1 Protected : Filler Extended";
BA_ "SignalLongName" SG_ 78 ABSRPI1P_FillerExtnd1 "Autonomous Brake System Redundant Primary Information 1 Protected : Filler Extended 1";
BA_ "SignalLongName" SG_ 78 ABSRPI1P_FillerExtnd2 "Autonomous Brake System Redundant Primary Information 1 Protected : Filler Extended 2";
BA_ "SignalType" SG_ 1498 AutoLnChgCstAvlFlg5 "ENM";
BA_ "SignalLongName" SG_ 1498 AutoLnChgCstAvlFlg5 "Automatic Lane Change Customization Availability Flag 5";
BA_ "SignalType" SG_ 1498 AutoLnChgCstAvlFlg4 "ENM";
BA_ "SignalLongName" SG_ 1498 AutoLnChgCstAvlFlg4 "Automatic Lane Change Customization Availability Flag 4";
BA_ "SignalType" SG_ 1498 AutoLnChgCstAvlFlg3 "ENM";
BA_ "SignalLongName" SG_ 1498 AutoLnChgCstAvlFlg3 "Automatic Lane Change Customization Availability Flag 3";
BA_ "SignalType" SG_ 1498 AutoLnChgCstAvlFlg2 "ENM";
BA_ "SignalLongName" SG_ 1498 AutoLnChgCstAvlFlg2 "Automatic Lane Change Customization Availability Flag 2";
BA_ "SignalType" SG_ 1498 AutoLnChgCstAvlFlg1 "ENM";
BA_ "SignalLongName" SG_ 1498 AutoLnChgCstAvlFlg1 "Automatic Lane Change Customization Availability Flag 1";
BA_ "SignalType" SG_ 1498 AutoLnChgCstCurrSetVal "ENM";
BA_ "SignalLongName" SG_ 1498 AutoLnChgCstCurrSetVal "Automatic Lane Change Customization Current Setting Value";
BA_ "SignalType" SG_ 1498 AutoLnChgCstSetAval "ENM";
BA_ "SignalLongName" SG_ 1498 AutoLnChgCstSetAval "Automatic Lane Change Customization Setting Available";
BA_ "SignalType" SG_ 1498 AutoLnChgCstAvlFlg7 "ENM";
BA_ "SignalLongName" SG_ 1498 AutoLnChgCstAvlFlg7 "Automatic Lane Change Customization Availability Flag 7";
BA_ "SignalType" SG_ 1498 AutoLnChgCstAvlFlg6 "ENM";
BA_ "SignalLongName" SG_ 1498 AutoLnChgCstAvlFlg6 "Automatic Lane Change Customization Availability Flag 6";
BA_ "SignalLongName" SG_ 698 AutoVehMtnCtlMnInfo1_PCSM "Autonomous Vehicle Motion Control Main Information 1 Protected Counter Sync Message";
BA_ "SignalLongName" SG_ 68 AVMCMI1P_MAC "Autonomous Vehicle Motion Control Main Information 1 Protected : MAC";
BA_ "SignalLongName" SG_ 68 AVMCMI1P_FCnt "Autonomous Vehicle Motion Control Main Information 1 Protected : Freshness Counter";
BA_ "SignalLongName" SG_ 68 AVMCMI1P_AutoCtlBrkTqRqAuth "Autonomous Vehicle Motion Control Main Information 1 Protected : Autonomous Controller Brake Torque Request Authenticated";
BA_ "SignalType" SG_ 68 AVMCMI1P_ADSRedntIPSPwrdOnAuth "ENM";
BA_ "SignalLongName" SG_ 68 AVMCMI1P_ADSRedntIPSPwrdOnAuth "Autonomous Vehicle Motion Control Main Information 1 Protected : Autonomous Driving System Redundant Integrated Power Sensor Powered On Authenticated";
BA_ "SignalLongName" SG_ 68 AVMCMI1P_AutoCtlRqAngVlAuth "Autonomous Vehicle Motion Control Main Information 1 Protected : Autonomous Control Request Angle Value Authenticated";
BA_ "SignalType" SG_ 68 AVMCMI1P_AutoCtlRqStrgModeAuth "ENM";
BA_ "SignalLongName" SG_ 68 AVMCMI1P_AutoCtlRqStrgModeAuth "Autonomous Vehicle Motion Control Main Information 1 Protected : Autonomous Control Request Steering Mode Authenticated";
BA_ "SignalType" SG_ 68 AVMCMI1P_AutoVehOprtlStatAuth "ENM";
BA_ "SignalLongName" SG_ 68 AVMCMI1P_AutoVehOprtlStatAuth "Autonomous Vehicle Motion Control Main Information 1 Protected : Autonomous Vehicle Operational State Authenticated";
BA_ "SignalType" SG_ 68 AVMCMI1P_AutoTransRngRqAuth "ENM";
BA_ "SignalLongName" SG_ 68 AVMCMI1P_AutoTransRngRqAuth "Autonomous Vehicle Motion Control Main Information 1 Protected : Autonomous Transmission Range Request Authenticated";
BA_ "SignalType" SG_ 68 AVMCMI1P_AutoCtlrEPBRqAuth "ENM";
BA_ "SignalLongName" SG_ 68 AVMCMI1P_AutoCtlrEPBRqAuth "Autonomous Vehicle Motion Control Main Information 1 Protected : Autonomous Controller Electric Park Brake Request Authenticated";
BA_ "SignalType" SG_ 68 AVMCMI1P_AutoCtlrBrkTqRqTypAuth "ENM";
BA_ "SignalLongName" SG_ 68 AVMCMI1P_AutoCtlrBrkTqRqTypAuth "Autonomous Vehicle Motion Control Main Information 1 Protected : Autonomous Controller Brake Torque Request Type Authenticated";
BA_ "SignalLongName" SG_ 68 AVMCMI1P_DgWhlBrkPrsRqLFAuth "Autonomous Vehicle Motion Control Main Information 1 Protected : Diagnostic Wheel Brake Pressure Request Left Front Authenticated";
BA_ "SignalLongName" SG_ 68 AVMCMI1P_DgWhlBrkPrsRqLRAuth "Autonomous Vehicle Motion Control Main Information 1 Protected : Diagnostic Wheel Brake Pressure Request Left Rear Authenticated";
BA_ "SignalLongName" SG_ 68 AVMCMI1P_DgWhlBrkPrsRqRFAuth "Autonomous Vehicle Motion Control Main Information 1 Protected : Diagnostic Wheel Brake Pressure Request Right Front Authenticated";
BA_ "SignalLongName" SG_ 68 AVMCMI1P_DgWhlBrkPrsRqRRAuth "Autonomous Vehicle Motion Control Main Information 1 Protected : Diagnostic Wheel Brake Pressure Request Right Rear Authenticated";
BA_ "SignalType" SG_ 68 AVMCMI1P_DgWhlBrkPrsRqTgtAuth "ENM";
BA_ "SignalLongName" SG_ 68 AVMCMI1P_DgWhlBrkPrsRqTgtAuth "Autonomous Vehicle Motion Control Main Information 1 Protected : Diagnostic Wheel Brake Pressure Request Target Authenticated";
BA_ "SignalLongName" SG_ 68 AVMCMI1P_MnAutoAxlTrqRqAuth "Autonomous Vehicle Motion Control Main Information 1 Protected : Main Autonomous Axle Torque Request Authenticated";
BA_ "SignalType" SG_ 68 AVMCMI1P_FailOprtlPwrAvSTRqAuth "ENM";
BA_ "SignalLongName" SG_ 68 AVMCMI1P_FailOprtlPwrAvSTRqAuth "Autonomous Vehicle Motion Control Main Information 1 Protected : Fail Operational Power Availability Self Test Request Authenticated";
BA_ "SignalLongName" SG_ 68 AVMCMI1P_Filler "Autonomous Vehicle Motion Control Main Information 1 Protected : Filler";
BA_ "SignalType" SG_ 68 AVMCMnFAXVCEqpdStsPriAuth "ENM";
BA_ "SignalLongName" SG_ 68 AVMCMnFAXVCEqpdStsPriAuth "Autonomous Vehicle Motion Control Main Information 1 Protected : Autonomous Vehicle Motion Control Main Full Authority External Vehicle Controller Equipped Status Primary Authenticated";
BA_ "SignalLongName" SG_ 68 AVMCMI1P_ARC "Autonomous Vehicle Motion Control Main Information 1 Protected : Alive Rolling Count";
BA_ "SignalLongName" SG_ 68 AVMCMI1P_FillerExtnd "Autonomous Vehicle Motion Control Main Information 1 Protected : Filler Extended";
BA_ "SignalLongName" SG_ 1367 AxlLckGenInfo_PCSM "Axle Lock General Information Protected Counter Sync Message";
BA_ "SignalLongName" SG_ 1307 ALGIP_MAC "Axle Lock General Information Protected : MAC";
BA_ "SignalLongName" SG_ 1307 ALGIP_FCnt "Axle Lock General Information Protected : Freshness Counter";
BA_ "SignalLongName" SG_ 1307 ALGIP_ARC "Axle Lock General Information Protected : Alive Rolling Count";
BA_ "SignalType" SG_ 1307 ALGIP_RrAxlLckFdbkAuth "ENM";
BA_ "SignalLongName" SG_ 1307 ALGIP_RrAxlLckFdbkAuth "Axle Lock General Information Protected : Rear Axle Lock Feedback Authenticated";
BA_ "SignalType" SG_ 1307 ALGIP_RrAxlLckCmndOnAuth "ENM";
BA_ "SignalLongName" SG_ 1307 ALGIP_RrAxlLckCmndOnAuth "Axle Lock General Information Protected : Rear Axle Lock Commanded On Authenticated";
BA_ "SignalType" SG_ 1307 ALGIP_FrtAxlLckFdbkAuth "ENM";
BA_ "SignalLongName" SG_ 1307 ALGIP_FrtAxlLckFdbkAuth "Axle Lock General Information Protected : Front Axle Lock Feedback Authenticated";
BA_ "SignalType" SG_ 1307 ALGIP_FrtAxlLckCmndOnAuth "ENM";
BA_ "SignalLongName" SG_ 1307 ALGIP_FrtAxlLckCmndOnAuth "Axle Lock General Information Protected : Front Axle Lock Commanded On Authenticated";
BA_ "SignalLongName" SG_ 1307 ALGIP_Filler "Axle Lock General Information Protected : Filler";
BA_ "SignalType" SG_ 2147745799 Sig0522 "ENM";
BA_ "SignalLongName" SG_ 2147745799 Sig0522 "Signal0413";
BA_ "SignalLongName" SG_ 1255 Sig3627 "Signal4012";
BA_ "SignalType" SG_ 2147745812 Sig0524 "ENM";
BA_ "SignalLongName" SG_ 2147745812 Sig0524 "Signal0415";
BA_ "SignalLongName" SG_ 923 BdyGenInfo3_PCSM "Body General Information 3 Protected Counter Sync Message";
BA_ "SignalLongName" SG_ 62 BGI3P_MAC "Body General Information 3 Protected : MAC";
BA_ "SignalLongName" SG_ 62 BGI3P_FCnt "Body General Information 3 Protected : Freshness Counter";
BA_ "SignalLongName" SG_ 62 BGI3P_BrkPedPstnAuth "Body General Information 3 Protected : Brake Pedal Position Authenticated";
BA_ "SignalType" SG_ 62 BGI3P_BrkPedModrTrvlAchAuth_Inv "ENM";
BA_ "SignalLongName" SG_ 62 BGI3P_BrkPedModrTrvlAchAuth_Inv "Body General Information 3 Protected : Brake Pedal Moderate Travel Achieved Authenticated Invalid";
BA_ "SignalType" SG_ 62 BGI3P_BrkPedModrTrvlAchAuth "ENM";
BA_ "SignalLongName" SG_ 62 BGI3P_BrkPedModrTrvlAchAuth "Body General Information 3 Protected : Brake Pedal Moderate Travel Achieved Authenticated";
BA_ "SignalType" SG_ 62 BGI3P_BrkPedInitTrvlAchAuth_Inv "ENM";
BA_ "SignalLongName" SG_ 62 BGI3P_BrkPedInitTrvlAchAuth_Inv "Body General Information 3 Protected : Brake Pedal Initial Travel Achieved Authenticated Invalid";
BA_ "SignalType" SG_ 62 BGI3P_BrkPedInitTrvlAchAuth "ENM";
BA_ "SignalLongName" SG_ 62 BGI3P_BrkPedInitTrvlAchAuth "Body General Information 3 Protected : Brake Pedal Initial Travel Achieved Authenticated";
BA_ "SignalType" SG_ 62 BGI3P_CruzSecSwStsAuth "ENM";
BA_ "SignalLongName" SG_ 62 BGI3P_CruzSecSwStsAuth "Body General Information 3 Protected : Cruise Secondary Switch Status Authenticated";
BA_ "SignalType" SG_ 62 BGI3P_BrkPedPstnAuth_Inv "ENM";
BA_ "SignalLongName" SG_ 62 BGI3P_BrkPedPstnAuth_Inv "Body General Information 3 Protected : Brake Pedal Position Authenticated Invalid";
BA_ "SignalType" SG_ 62 CruzCtlSwBank1Sts "ENM";
BA_ "SignalLongName" SG_ 62 CruzCtlSwBank1Sts "Body General Information 3 Protected : Cruise Control Switch Bank 1 Status";
BA_ "SignalLongName" SG_ 62 BGI3P_ARC "Body General Information 3 Protected : Alive Rolling Count";
BA_ "SignalType" SG_ 62 BGI3P_CruzSpdLmtrSwStsAuth "ENM";
BA_ "SignalLongName" SG_ 62 BGI3P_CruzSpdLmtrSwStsAuth "Body General Information 3 Protected : Cruise and Speed Limiter Switch Status Authenticated";
BA_ "SignalType" SG_ 62 StrgWhlCruzCtlCfg "ENM";
BA_ "SignalLongName" SG_ 62 StrgWhlCruzCtlCfg "Body General Information 3 Protected : Steering Wheel Cruise Control Configuration";
BA_ "SignalType" SG_ 62 CruzCtlSwBank2Sts "ENM";
BA_ "SignalLongName" SG_ 62 CruzCtlSwBank2Sts "Body General Information 3 Protected : Cruise Control Switch Bank 2 Status";
BA_ "SignalLongName" SG_ 1405 BkupSysPwrMode_PCSM "Backup System Power Mode Protected Counter Sync Message";
BA_ "SignalLongName" SG_ 880 BSPMP_MAC "Backup System Power Mode Protected : MAC";
BA_ "SignalLongName" SG_ 880 BSPMP_FCnt "Backup System Power Mode Protected : Freshness Counter";
BA_ "SignalLongName" SG_ 880 BSPMP_PV "Backup System Power Mode Protected : Protection Value";
BA_ "SignalType" SG_ 880 BSPMP_BkupSysPwrModeAuth_Inv "ENM";
BA_ "SignalLongName" SG_ 880 BSPMP_BkupSysPwrModeAuth_Inv "Backup System Power Mode Protected : Backup System Power Mode Authenticated Invalid";
BA_ "SignalType" SG_ 880 BSPMP_BkupSysPwrModeAuth "ENM";
BA_ "SignalLongName" SG_ 880 BSPMP_BkupSysPwrModeAuth "Backup System Power Mode Protected : Backup System Power Mode Authenticated";
BA_ "SignalLongName" SG_ 880 BSPMP_ARC "Backup System Power Mode Protected : Alive Rolling Count";
BA_ "SignalType" SG_ 880 BSPMP_SecRunCrnkCmdActvAuth_Inv "ENM";
BA_ "SignalLongName" SG_ 880 BSPMP_SecRunCrnkCmdActvAuth_Inv "Backup System Power Mode Protected : Secondary Run Crank Command Active Invalid Authenticated";
BA_ "SignalType" SG_ 880 BSPMP_SecRunCrnkCmdActvAuth "ENM";
BA_ "SignalLongName" SG_ 880 BSPMP_SecRunCrnkCmdActvAuth "Backup System Power Mode Protected : Secondary Run Crank Command Active Authenticated";
BA_ "SignalType" SG_ 880 BSPMP_SecPwrModePBActvAuth_Inv "ENM";
BA_ "SignalLongName" SG_ 880 BSPMP_SecPwrModePBActvAuth_Inv "Backup System Power Mode Protected : Secondary Power Mode Pushbutton Active Authenticated Invalid";
BA_ "SignalType" SG_ 880 BSPMP_SecPwrModePBActvAuth "ENM";
BA_ "SignalLongName" SG_ 880 BSPMP_SecPwrModePBActvAuth "Backup System Power Mode Protected : Secondary Power Mode Pushbutton Active Authenticated";
BA_ "SignalType" SG_ 880 BSPMP_RmtProgmActvAuth "ENM";
BA_ "SignalLongName" SG_ 880 BSPMP_RmtProgmActvAuth "Backup System Power Mode Protected : Remote Programming Active Authenticated";
BA_ "SignalLongName" SG_ 1391 Sig0529 "Signal0444";
BA_ "SignalLongName" SG_ 1301 Sig0477 "Signal0439";
BA_ "SignalLongName" SG_ 1301 Sig0476 "Signal0438";
BA_ "SignalLongName" SG_ 1301 Sig0478 "Signal0440";
BA_ "SignalLongName" SG_ 1301 Sig0480 "Signal0442";
BA_ "SignalType" SG_ 1301 Sig0479 "ENM";
BA_ "SignalLongName" SG_ 1301 Sig0479 "Signal0441";
BA_ "SignalLongName" SG_ 1301 Sig0475 "Signal0437";
BA_ "SignalType" SG_ 1301 Sig0481 "ENM";
BA_ "SignalLongName" SG_ 1301 Sig0481 "Signal0443";
BA_ "SignalLongName" SG_ 922 Sig0530 "Signal0453";
BA_ "SignalLongName" SG_ 108 Sig0484 "Signal0447";
BA_ "SignalLongName" SG_ 108 Sig0483 "Signal0446";
BA_ "SignalLongName" SG_ 108 Sig0486 "Signal0449";
BA_ "SignalType" SG_ 108 Sig0485 "ENM";
BA_ "SignalLongName" SG_ 108 Sig0485 "Signal0448";
BA_ "SignalLongName" SG_ 108 Sig0488 "Signal0451";
BA_ "SignalType" SG_ 108 Sig0487 "ENM";
BA_ "SignalLongName" SG_ 108 Sig0487 "Signal0450";
BA_ "SignalLongName" SG_ 108 Sig0482 "Signal0445";
BA_ "SignalType" SG_ 108 Sig0489 "ENM";
BA_ "SignalLongName" SG_ 108 Sig0489 "Signal0452";
BA_ "SignalLongName" SG_ 921 Sig0531 "Signal0465";
BA_ "SignalLongName" SG_ 98 Sig0493 "Signal0457";
BA_ "SignalLongName" SG_ 98 Sig0491 "Signal0456";
BA_ "SignalLongName" SG_ 98 Sig0494 "Signal0458";
BA_ "SignalLongName" SG_ 98 Sig0495 "Signal0459";
BA_ "SignalLongName" SG_ 98 Sig0497 "Signal0461";
BA_ "SignalType" SG_ 98 Sig0496 "ENM";
BA_ "SignalLongName" SG_ 98 Sig0496 "Signal0460";
BA_ "SignalType" SG_ 98 Sig0498 "ENM";
BA_ "SignalLongName" SG_ 98 Sig0498 "Signal0462";
BA_ "SignalLongName" SG_ 98 Sig0499 "Signal0463";
BA_ "SignalLongName" SG_ 98 Sig0500 "Signal0464";
BA_ "SignalLongName" SG_ 98 Sig0492 "Signal0455";
BA_ "SignalLongName" SG_ 98 Sig0490 "Signal0454";
BA_ "SignalLongName" SG_ 691 BrkSysInfoSts2_PCSM "Brake System Information Status 2 Protected Counter Sync Message";
BA_ "SignalLongName" SG_ 66 BSIS2P_MAC "Brake System Information Status 2 Protected : MAC";
BA_ "SignalLongName" SG_ 66 BSIS2P_FCnt "Brake System Information Status 2 Protected : Freshness Counter";
BA_ "SignalLongName" SG_ 66 BSIS2P_BSTrqOvlyDlTrqCmdValAuth "Brake System Information Status 2 Protected : Brake System Torque Overlay Delta Torque Command Value Authenticated";
BA_ "SignalType" SG_ 66 BSIS2P_BSTrqOvlyDlTrqCmdAtvAuth "ENM";
BA_ "SignalLongName" SG_ 66 BSIS2P_BSTrqOvlyDlTrqCmdAtvAuth "Brake System Information Status 2 Protected : Brake System Torque Overlay Delta Torque Command Active Authenticated";
BA_ "SignalType" SG_ 66 BSIS2P_ABSFldAuth "ENM";
BA_ "SignalLongName" SG_ 66 BSIS2P_ABSFldAuth "Brake System Information Status 2 Protected : Antilock Brake System Failed Authenticated";
BA_ "SignalType" SG_ 66 BSIS2P_ABSAtvAuth "ENM";
BA_ "SignalLongName" SG_ 66 BSIS2P_ABSAtvAuth "Brake System Information Status 2 Protected : Antilock Brake System Active Authenticated";
BA_ "SignalType" SG_ 66 BrkPdlDrvAppPrsDetcdAuth_Inv "ENM";
BA_ "SignalLongName" SG_ 66 BrkPdlDrvAppPrsDetcdAuth_Inv "Brake System Information Status 2 Protected : Brake Pedal Driver Applied Pressure Detected Authenticated Invalid";
BA_ "SignalType" SG_ 66 BrkPdlDrvAppPrsDetcdAuth "ENM";
BA_ "SignalLongName" SG_ 66 BrkPdlDrvAppPrsDetcdAuth "Brake System Information Status 2 Protected : Brake Pedal Driver Applied Pressure Detected Authenticated";
BA_ "SignalLongName" SG_ 66 BSIS2P_BrkPdlDrvApplPresAuth "Brake System Information Status 2 Protected : Brake Pedal Driver Applied Pressure Authenticated";
BA_ "SignalLongName" SG_ 66 BSIS2P_Filler "Brake System Information Status 2 Protected : Filler";
BA_ "SignalLongName" SG_ 66 BSIS2P_ARC "Brake System Information Status 2 Protected : Alive Rolling Count";
BA_ "SignalType" SG_ 66 BSIS2P_BrkPdlDrvApplPresAuth_Inv "ENM";
BA_ "SignalLongName" SG_ 66 BSIS2P_BrkPdlDrvApplPresAuth_Inv "Brake System Information Status 2 Protected : Brake Pedal Driver Applied Pressure Authenticated Invalid";
BA_ "SignalLongName" SG_ 696 ChsSysBrkAxlTrqInfo1_PCSM "Chassis System Brake Axle Torque Information 1 Protected Counter Sync Message";
BA_ "SignalLongName" SG_ 51 CSBATI1P_MAC "Chassis System Brake Axle Torque Information 1 Protected : MAC";
BA_ "SignalLongName" SG_ 51 CSBATI1P_FCnt "Chassis System Brake Axle Torque Information 1 Protected : Freshness Counter";
BA_ "SignalLongName" SG_ 51 CSBATI1P_BrkBlndgAxTqAchvdAuth "Chassis System Brake Axle Torque Information 1 Protected : Brake Blending Axle Torque Achieved Authenticated";
BA_ "SignalLongName" SG_ 51 CSBATI1P_BrkBlndgAxTqCpbltyAuth "Chassis System Brake Axle Torque Information 1 Protected : Brake Blending Axle Torque Capability Authenticated";
BA_ "SignalLongName" SG_ 51 CSBATI1P_Filler "Chassis System Brake Axle Torque Information 1 Protected : Filler";
BA_ "SignalLongName" SG_ 51 CSBATI1P_ARC "Chassis System Brake Axle Torque Information 1 Protected : Alive Rolling Count";
BA_ "SignalLongName" SG_ 1506 CCHI_CalcdTgtCabinHtLd "Climate Control Heater Information : Calculated Target Cabin Heat Load";
BA_ "SignalLongName" SG_ 1506 CCHI_MinFlwRateReq "Climate Control Heater Information : Minimum Flow Rate Request";
BA_ "SignalType" SG_ 1506 CCHI_CalcdTgtCabinHtLd_Inv "ENM";
BA_ "SignalLongName" SG_ 1506 CCHI_CalcdTgtCabinHtLd_Inv "Climate Control Heater Information : Calculated Target Cabin Heat Load Invalid";
BA_ "SignalLongName" SG_ 1506 CCHI_MinTgtCoolTemp "Climate Control Heater Information : Minimum Target Coolant Temperature";
BA_ "SignalType" SG_ 1506 CCHI_MinFlwRateReq_Inv "ENM";
BA_ "SignalLongName" SG_ 1506 CCHI_MinFlwRateReq_Inv "Climate Control Heater Information : Minimum Flow Rate Request Invalid";
BA_ "SignalType" SG_ 1506 CCHI_PrtyHtReq_Inv "ENM";
BA_ "SignalLongName" SG_ 1506 CCHI_PrtyHtReq_Inv "Climate Control Heater Information : Priority Heating Request Invalid";
BA_ "SignalType" SG_ 1506 CCHI_PrtyHtReq "ENM";
BA_ "SignalLongName" SG_ 1506 CCHI_PrtyHtReq "Climate Control Heater Information : Priority Heating Request";
BA_ "SignalType" SG_ 1506 CCHI_MinTgtCoolTemp_Inv "ENM";
BA_ "SignalLongName" SG_ 1506 CCHI_MinTgtCoolTemp_Inv "Climate Control Heater Information : Minimum Target Coolant Temperature Invalid";
BA_ "SignalLongName" SG_ 1506 CCHI_CS "Climate Control Heater Information : Checksum";
BA_ "SignalLongName" SG_ 1506 CCHI_ARC "Climate Control Heater Information : Alive Rolling Count";
BA_ "SignalType" SG_ 2147745813 Sig0715 "ENM";
BA_ "SignalLongName" SG_ 2147745813 Sig0715 "Signal0623";
BA_ "SignalType" SG_ 2147745814 DMS_CAN2_ClscCANHrtBtActv "ENM";
BA_ "SignalLongName" SG_ 2147745814 DMS_CAN2_ClscCANHrtBtActv "DMS CAN 2 Classic CAN Heart Beat Active";
BA_ "SignalLongName" SG_ 1530 Sig1113 "Signal0672";
BA_ "SignalType" SG_ 1530 Sig1112 "ENM";
BA_ "SignalLongName" SG_ 1530 Sig1112 "Signal0671";
BA_ "SignalType" SG_ 1530 Sig1114 "ENM";
BA_ "SignalLongName" SG_ 1530 Sig1114 "Signal0673";
BA_ "SignalLongName" SG_ 1530 Sig1115 "Signal0674";
BA_ "SignalLongName" SG_ 1530 Sig1116 "Signal0675";
BA_ "SignalType" SG_ 1530 Sig1123 "ENM";
BA_ "SignalLongName" SG_ 1530 Sig1123 "Signal0682";
BA_ "SignalType" SG_ 1530 Sig1122 "ENM";
BA_ "SignalLongName" SG_ 1530 Sig1122 "Signal0681";
BA_ "SignalType" SG_ 1530 Sig1121 "ENM";
BA_ "SignalLongName" SG_ 1530 Sig1121 "Signal0680";
BA_ "SignalType" SG_ 1530 Sig1120 "ENM";
BA_ "SignalLongName" SG_ 1530 Sig1120 "Signal0679";
BA_ "SignalType" SG_ 1530 Sig1119 "ENM";
BA_ "SignalLongName" SG_ 1530 Sig1119 "Signal0678";
BA_ "SignalType" SG_ 1530 Sig1118 "ENM";
BA_ "SignalLongName" SG_ 1530 Sig1118 "Signal0677";
BA_ "SignalType" SG_ 1530 Sig1117 "ENM";
BA_ "SignalLongName" SG_ 1530 Sig1117 "Signal0676";
BA_ "SignalType" SG_ 1530 Sig1125 "ENM";
BA_ "SignalLongName" SG_ 1530 Sig1125 "Signal0684";
BA_ "SignalType" SG_ 1530 Sig1124 "ENM";
BA_ "SignalLongName" SG_ 1530 Sig1124 "Signal0683";
BA_ "SignalLongName" SG_ 1531 Sig1127 "Signal0686";
BA_ "SignalType" SG_ 1531 Sig1126 "ENM";
BA_ "SignalLongName" SG_ 1531 Sig1126 "Signal0685";
BA_ "SignalType" SG_ 1531 Sig1128 "ENM";
BA_ "SignalLongName" SG_ 1531 Sig1128 "Signal0687";
BA_ "SignalLongName" SG_ 1531 Sig1129 "Signal0688";
BA_ "SignalLongName" SG_ 1531 Sig1130 "Signal0689";
BA_ "SignalType" SG_ 1531 Sig1137 "ENM";
BA_ "SignalLongName" SG_ 1531 Sig1137 "Signal0696";
BA_ "SignalType" SG_ 1531 Sig1136 "ENM";
BA_ "SignalLongName" SG_ 1531 Sig1136 "Signal0695";
BA_ "SignalType" SG_ 1531 Sig1135 "ENM";
BA_ "SignalLongName" SG_ 1531 Sig1135 "Signal0694";
BA_ "SignalType" SG_ 1531 Sig1134 "ENM";
BA_ "SignalLongName" SG_ 1531 Sig1134 "Signal0693";
BA_ "SignalType" SG_ 1531 Sig1133 "ENM";
BA_ "SignalLongName" SG_ 1531 Sig1133 "Signal0692";
BA_ "SignalType" SG_ 1531 Sig1132 "ENM";
BA_ "SignalLongName" SG_ 1531 Sig1132 "Signal0691";
BA_ "SignalType" SG_ 1531 Sig1131 "ENM";
BA_ "SignalLongName" SG_ 1531 Sig1131 "Signal0690";
BA_ "SignalType" SG_ 1531 Sig1139 "ENM";
BA_ "SignalLongName" SG_ 1531 Sig1139 "Signal0698";
BA_ "SignalType" SG_ 1531 Sig1138 "ENM";
BA_ "SignalLongName" SG_ 1531 Sig1138 "Signal0697";
BA_ "SignalLongName" SG_ 1532 Sig1211 "Signal0770";
BA_ "SignalType" SG_ 1532 Sig1210 "ENM";
BA_ "SignalLongName" SG_ 1532 Sig1210 "Signal0769";
BA_ "SignalType" SG_ 1532 Sig1212 "ENM";
BA_ "SignalLongName" SG_ 1532 Sig1212 "Signal0771";
BA_ "SignalLongName" SG_ 1532 Sig1213 "Signal0772";
BA_ "SignalLongName" SG_ 1532 Sig1214 "Signal0773";
BA_ "SignalType" SG_ 1532 Sig1221 "ENM";
BA_ "SignalLongName" SG_ 1532 Sig1221 "Signal0780";
BA_ "SignalType" SG_ 1532 Sig1220 "ENM";
BA_ "SignalLongName" SG_ 1532 Sig1220 "Signal0779";
BA_ "SignalType" SG_ 1532 Sig1219 "ENM";
BA_ "SignalLongName" SG_ 1532 Sig1219 "Signal0778";
BA_ "SignalType" SG_ 1532 Sig1218 "ENM";
BA_ "SignalLongName" SG_ 1532 Sig1218 "Signal0777";
BA_ "SignalType" SG_ 1532 Sig1217 "ENM";
BA_ "SignalLongName" SG_ 1532 Sig1217 "Signal0776";
BA_ "SignalType" SG_ 1532 Sig1216 "ENM";
BA_ "SignalLongName" SG_ 1532 Sig1216 "Signal0775";
BA_ "SignalType" SG_ 1532 Sig1215 "ENM";
BA_ "SignalLongName" SG_ 1532 Sig1215 "Signal0774";
BA_ "SignalType" SG_ 1532 Sig1223 "ENM";
BA_ "SignalLongName" SG_ 1532 Sig1223 "Signal0782";
BA_ "SignalType" SG_ 1532 Sig1222 "ENM";
BA_ "SignalLongName" SG_ 1532 Sig1222 "Signal0781";
BA_ "SignalLongName" SG_ 1533 Sig1231 "Signal0798";
BA_ "SignalType" SG_ 1533 Sig1230 "ENM";
BA_ "SignalLongName" SG_ 1533 Sig1230 "Signal0797";
BA_ "SignalType" SG_ 1533 Sig1232 "ENM";
BA_ "SignalLongName" SG_ 1533 Sig1232 "Signal0799";
BA_ "SignalLongName" SG_ 1533 Sig1233 "Signal0800";
BA_ "SignalLongName" SG_ 1533 Sig1234 "Signal0801";
BA_ "SignalType" SG_ 1533 Sig1241 "ENM";
BA_ "SignalLongName" SG_ 1533 Sig1241 "Signal0808";
BA_ "SignalType" SG_ 1533 Sig1240 "ENM";
BA_ "SignalLongName" SG_ 1533 Sig1240 "Signal0807";
BA_ "SignalType" SG_ 1533 Sig1239 "ENM";
BA_ "SignalLongName" SG_ 1533 Sig1239 "Signal0806";
BA_ "SignalType" SG_ 1533 Sig1238 "ENM";
BA_ "SignalLongName" SG_ 1533 Sig1238 "Signal0805";
BA_ "SignalType" SG_ 1533 Sig1237 "ENM";
BA_ "SignalLongName" SG_ 1533 Sig1237 "Signal0804";
BA_ "SignalType" SG_ 1533 Sig1236 "ENM";
BA_ "SignalLongName" SG_ 1533 Sig1236 "Signal0803";
BA_ "SignalType" SG_ 1533 Sig1235 "ENM";
BA_ "SignalLongName" SG_ 1533 Sig1235 "Signal0802";
BA_ "SignalType" SG_ 1533 Sig1243 "ENM";
BA_ "SignalLongName" SG_ 1533 Sig1243 "Signal0810";
BA_ "SignalType" SG_ 1533 Sig1242 "ENM";
BA_ "SignalLongName" SG_ 1533 Sig1242 "Signal0809";
BA_ "SignalLongName" SG_ 1276 Sig1225 "Signal0784";
BA_ "SignalType" SG_ 1276 Sig1224 "ENM";
BA_ "SignalLongName" SG_ 1276 Sig1224 "Signal0783";
BA_ "SignalType" SG_ 1276 Sig1226 "ENM";
BA_ "SignalLongName" SG_ 1276 Sig1226 "Signal0785";
BA_ "SignalLongName" SG_ 1276 Sig1227 "Signal0786";
BA_ "SignalLongName" SG_ 1276 Sig1228 "Signal0787";
BA_ "SignalType" SG_ 1276 Sig1249 "ENM";
BA_ "SignalLongName" SG_ 1276 Sig1249 "Signal0794";
BA_ "SignalType" SG_ 1276 Sig1248 "ENM";
BA_ "SignalLongName" SG_ 1276 Sig1248 "Signal0793";
BA_ "SignalType" SG_ 1276 Sig1247 "ENM";
BA_ "SignalLongName" SG_ 1276 Sig1247 "Signal0792";
BA_ "SignalType" SG_ 1276 Sig1246 "ENM";
BA_ "SignalLongName" SG_ 1276 Sig1246 "Signal0791";
BA_ "SignalType" SG_ 1276 Sig1245 "ENM";
BA_ "SignalLongName" SG_ 1276 Sig1245 "Signal0790";
BA_ "SignalType" SG_ 1276 Sig1244 "ENM";
BA_ "SignalLongName" SG_ 1276 Sig1244 "Signal0789";
BA_ "SignalType" SG_ 1276 Sig1229 "ENM";
BA_ "SignalLongName" SG_ 1276 Sig1229 "Signal0788";
BA_ "SignalType" SG_ 1276 Sig1251 "ENM";
BA_ "SignalLongName" SG_ 1276 Sig1251 "Signal0796";
BA_ "SignalType" SG_ 1276 Sig1250 "ENM";
BA_ "SignalLongName" SG_ 1276 Sig1250 "Signal0795";
BA_ "SignalLongName" SG_ 1275 Sig1295 "Signal0854";
BA_ "SignalType" SG_ 1275 Sig1294 "ENM";
BA_ "SignalLongName" SG_ 1275 Sig1294 "Signal0853";
BA_ "SignalType" SG_ 1275 Sig1296 "ENM";
BA_ "SignalLongName" SG_ 1275 Sig1296 "Signal0855";
BA_ "SignalLongName" SG_ 1275 Sig1297 "Signal0856";
BA_ "SignalLongName" SG_ 1275 Sig1298 "Signal0857";
BA_ "SignalType" SG_ 1275 Sig1305 "ENM";
BA_ "SignalLongName" SG_ 1275 Sig1305 "Signal0864";
BA_ "SignalType" SG_ 1275 Sig1304 "ENM";
BA_ "SignalLongName" SG_ 1275 Sig1304 "Signal0863";
BA_ "SignalType" SG_ 1275 Sig1303 "ENM";
BA_ "SignalLongName" SG_ 1275 Sig1303 "Signal0862";
BA_ "SignalType" SG_ 1275 Sig1302 "ENM";
BA_ "SignalLongName" SG_ 1275 Sig1302 "Signal0861";
BA_ "SignalType" SG_ 1275 Sig1301 "ENM";
BA_ "SignalLongName" SG_ 1275 Sig1301 "Signal0860";
BA_ "SignalType" SG_ 1275 Sig1300 "ENM";
BA_ "SignalLongName" SG_ 1275 Sig1300 "Signal0859";
BA_ "SignalType" SG_ 1275 Sig1299 "ENM";
BA_ "SignalLongName" SG_ 1275 Sig1299 "Signal0858";
BA_ "SignalType" SG_ 1275 Sig1307 "ENM";
BA_ "SignalLongName" SG_ 1275 Sig1307 "Signal0866";
BA_ "SignalType" SG_ 1275 Sig1306 "ENM";
BA_ "SignalLongName" SG_ 1275 Sig1306 "Signal0865";
BA_ "SignalLongName" SG_ 1274 DTCI_DMS_DTCFailType "Diagnostic Trouble Code Information Extended - DMS : Diagnostic Trouble Code Failure Type";
BA_ "SignalType" SG_ 1274 DTCI_DMS_CnfrmdDTC "ENM";
BA_ "SignalLongName" SG_ 1274 DTCI_DMS_CnfrmdDTC "Diagnostic Trouble Code Information Extended - DMS : Confirmed DTC";
BA_ "SignalType" SG_ 1274 DTCI_DMS_DTCFaultType "ENM";
BA_ "SignalLongName" SG_ 1274 DTCI_DMS_DTCFaultType "Diagnostic Trouble Code Information Extended - DMS : Diagnostic Trouble Code Fault Type";
BA_ "SignalLongName" SG_ 1274 DTCI_DMS_DTCNumber "Diagnostic Trouble Code Information Extended - DMS : Diagnostic Trouble Code Number";
BA_ "SignalLongName" SG_ 1274 DTCI_DMS_DTCSource "Diagnostic Trouble Code Information Extended - DMS : Diagnostic Trouble Code Source";
BA_ "SignalType" SG_ 1274 DTCI_DMS_TstNCmpltdOpCyc "ENM";
BA_ "SignalLongName" SG_ 1274 DTCI_DMS_TstNCmpltdOpCyc "Diagnostic Trouble Code Information Extended - DMS : Test Not Completed This Operation Cycle";
BA_ "SignalType" SG_ 1274 DTCI_DMS_TstNCmpltdLstClr "ENM";
BA_ "SignalLongName" SG_ 1274 DTCI_DMS_TstNCmpltdLstClr "Diagnostic Trouble Code Information Extended - DMS : Test Not Completed Since Last Clear";
BA_ "SignalType" SG_ 1274 DTCI_DMS_TstFldOpCyc "ENM";
BA_ "SignalLongName" SG_ 1274 DTCI_DMS_TstFldOpCyc "Diagnostic Trouble Code Information Extended - DMS : Test Failed This Operation Cycle";
BA_ "SignalType" SG_ 1274 DTCI_DMS_TstFldLstClr "ENM";
BA_ "SignalLongName" SG_ 1274 DTCI_DMS_TstFldLstClr "Diagnostic Trouble Code Information Extended - DMS : Test Failed Since Last Clear";
BA_ "SignalType" SG_ 1274 DTCI_DMS_TstFld "ENM";
BA_ "SignalLongName" SG_ 1274 DTCI_DMS_TstFld "Diagnostic Trouble Code Information Extended - DMS : Test Failed";
BA_ "SignalType" SG_ 1274 DTCI_DMS_PndngDTC "ENM";
BA_ "SignalLongName" SG_ 1274 DTCI_DMS_PndngDTC "Diagnostic Trouble Code Information Extended - DMS : Pending DTC";
BA_ "SignalType" SG_ 1274 DTCI_DMS_DTCTriggered "ENM";
BA_ "SignalLongName" SG_ 1274 DTCI_DMS_DTCTriggered "Diagnostic Trouble Code Information Extended - DMS : Diagnostic Trouble Code Triggered";
BA_ "SignalType" SG_ 1274 DTCI_DMS_WrnIndTrggrd "ENM";
BA_ "SignalLongName" SG_ 1274 DTCI_DMS_WrnIndTrggrd "Diagnostic Trouble Code Information Extended - DMS : Warning Indicator Triggered";
BA_ "SignalType" SG_ 1274 DTCI_DMS_WrnIndRqd "ENM";
BA_ "SignalLongName" SG_ 1274 DTCI_DMS_WrnIndRqd "Diagnostic Trouble Code Information Extended - DMS : Warning Indicator Requested";
BA_ "SignalLongName" SG_ 1792 Sig1309 "Signal0868";
BA_ "SignalType" SG_ 1792 Sig1308 "ENM";
BA_ "SignalLongName" SG_ 1792 Sig1308 "Signal0867";
BA_ "SignalType" SG_ 1792 Sig1310 "ENM";
BA_ "SignalLongName" SG_ 1792 Sig1310 "Signal0869";
BA_ "SignalLongName" SG_ 1792 Sig1311 "Signal0870";
BA_ "SignalLongName" SG_ 1792 Sig1312 "Signal0871";
BA_ "SignalType" SG_ 1792 Sig1319 "ENM";
BA_ "SignalLongName" SG_ 1792 Sig1319 "Signal0878";
BA_ "SignalType" SG_ 1792 Sig1318 "ENM";
BA_ "SignalLongName" SG_ 1792 Sig1318 "Signal0877";
BA_ "SignalType" SG_ 1792 Sig1317 "ENM";
BA_ "SignalLongName" SG_ 1792 Sig1317 "Signal0876";
BA_ "SignalType" SG_ 1792 Sig1316 "ENM";
BA_ "SignalLongName" SG_ 1792 Sig1316 "Signal0875";
BA_ "SignalType" SG_ 1792 Sig1315 "ENM";
BA_ "SignalLongName" SG_ 1792 Sig1315 "Signal0874";
BA_ "SignalType" SG_ 1792 Sig1314 "ENM";
BA_ "SignalLongName" SG_ 1792 Sig1314 "Signal0873";
BA_ "SignalType" SG_ 1792 Sig1313 "ENM";
BA_ "SignalLongName" SG_ 1792 Sig1313 "Signal0872";
BA_ "SignalType" SG_ 1792 Sig1321 "ENM";
BA_ "SignalLongName" SG_ 1792 Sig1321 "Signal0880";
BA_ "SignalType" SG_ 1792 Sig1320 "ENM";
BA_ "SignalLongName" SG_ 1792 Sig1320 "Signal0879";
BA_ "SignalLongName" SG_ 1793 DTCI_ECP_E_DTCFailType "Diagnostic Trouble Code Information Extended - ECP_E : Diagnostic Trouble Code Failure Type";
BA_ "SignalType" SG_ 1793 DTCI_ECP_E_CnfrmdDTC "ENM";
BA_ "SignalLongName" SG_ 1793 DTCI_ECP_E_CnfrmdDTC "Diagnostic Trouble Code Information Extended - ECP_E : Confirmed DTC";
BA_ "SignalType" SG_ 1793 DTCI_ECP_E_DTCFaultType "ENM";
BA_ "SignalLongName" SG_ 1793 DTCI_ECP_E_DTCFaultType "Diagnostic Trouble Code Information Extended - ECP_E : Diagnostic Trouble Code Fault Type";
BA_ "SignalLongName" SG_ 1793 DTCI_ECP_E_DTCNumber "Diagnostic Trouble Code Information Extended - ECP_E : Diagnostic Trouble Code Number";
BA_ "SignalLongName" SG_ 1793 DTCI_ECP_E_DTCSource "Diagnostic Trouble Code Information Extended - ECP_E : Diagnostic Trouble Code Source";
BA_ "SignalType" SG_ 1793 DTCI_ECP_E_TstNCmpltdOpCyc "ENM";
BA_ "SignalLongName" SG_ 1793 DTCI_ECP_E_TstNCmpltdOpCyc "Diagnostic Trouble Code Information Extended - ECP_E : Test Not Completed This Operation Cycle";
BA_ "SignalType" SG_ 1793 DTCI_ECP_E_TstNCmpltdLstClr "ENM";
BA_ "SignalLongName" SG_ 1793 DTCI_ECP_E_TstNCmpltdLstClr "Diagnostic Trouble Code Information Extended - ECP_E : Test Not Completed Since Last Clear";
BA_ "SignalType" SG_ 1793 DTCI_ECP_E_TstFldOpCyc "ENM";
BA_ "SignalLongName" SG_ 1793 DTCI_ECP_E_TstFldOpCyc "Diagnostic Trouble Code Information Extended - ECP_E : Test Failed This Operation Cycle";
BA_ "SignalType" SG_ 1793 DTCI_ECP_E_TstFldLstClr "ENM";
BA_ "SignalLongName" SG_ 1793 DTCI_ECP_E_TstFldLstClr "Diagnostic Trouble Code Information Extended - ECP_E : Test Failed Since Last Clear";
BA_ "SignalType" SG_ 1793 DTCI_ECP_E_TstFld "ENM";
BA_ "SignalLongName" SG_ 1793 DTCI_ECP_E_TstFld "Diagnostic Trouble Code Information Extended - ECP_E : Test Failed";
BA_ "SignalType" SG_ 1793 DTCI_ECP_E_PndngDTC "ENM";
BA_ "SignalLongName" SG_ 1793 DTCI_ECP_E_PndngDTC "Diagnostic Trouble Code Information Extended - ECP_E : Pending DTC";
BA_ "SignalType" SG_ 1793 DTCI_ECP_E_DTCTriggered "ENM";
BA_ "SignalLongName" SG_ 1793 DTCI_ECP_E_DTCTriggered "Diagnostic Trouble Code Information Extended - ECP_E : Diagnostic Trouble Code Triggered";
BA_ "SignalType" SG_ 1793 DTCI_ECP_E_WrnIndTrggrd "ENM";
BA_ "SignalLongName" SG_ 1793 DTCI_ECP_E_WrnIndTrggrd "Diagnostic Trouble Code Information Extended - ECP_E : Warning Indicator Triggered";
BA_ "SignalType" SG_ 1793 DTCI_ECP_E_WrnIndRqd "ENM";
BA_ "SignalLongName" SG_ 1793 DTCI_ECP_E_WrnIndRqd "Diagnostic Trouble Code Information Extended - ECP_E : Warning Indicator Requested";
BA_ "SignalLongName" SG_ 1272 Sig1323 "Signal0882";
BA_ "SignalType" SG_ 1272 Sig1322 "ENM";
BA_ "SignalLongName" SG_ 1272 Sig1322 "Signal0881";
BA_ "SignalType" SG_ 1272 Sig1324 "ENM";
BA_ "SignalLongName" SG_ 1272 Sig1324 "Signal0883";
BA_ "SignalLongName" SG_ 1272 Sig1325 "Signal0884";
BA_ "SignalLongName" SG_ 1272 Sig1326 "Signal0885";
BA_ "SignalType" SG_ 1272 Sig1333 "ENM";
BA_ "SignalLongName" SG_ 1272 Sig1333 "Signal0892";
BA_ "SignalType" SG_ 1272 Sig1332 "ENM";
BA_ "SignalLongName" SG_ 1272 Sig1332 "Signal0891";
BA_ "SignalType" SG_ 1272 Sig1331 "ENM";
BA_ "SignalLongName" SG_ 1272 Sig1331 "Signal0890";
BA_ "SignalType" SG_ 1272 Sig1330 "ENM";
BA_ "SignalLongName" SG_ 1272 Sig1330 "Signal0889";
BA_ "SignalType" SG_ 1272 Sig1329 "ENM";
BA_ "SignalLongName" SG_ 1272 Sig1329 "Signal0888";
BA_ "SignalType" SG_ 1272 Sig1328 "ENM";
BA_ "SignalLongName" SG_ 1272 Sig1328 "Signal0887";
BA_ "SignalType" SG_ 1272 Sig1327 "ENM";
BA_ "SignalLongName" SG_ 1272 Sig1327 "Signal0886";
BA_ "SignalType" SG_ 1272 Sig1335 "ENM";
BA_ "SignalLongName" SG_ 1272 Sig1335 "Signal0894";
BA_ "SignalType" SG_ 1272 Sig1334 "ENM";
BA_ "SignalLongName" SG_ 1272 Sig1334 "Signal0893";
BA_ "SignalLongName" SG_ 1273 Sig1337 "Signal0910";
BA_ "SignalType" SG_ 1273 Sig1336 "ENM";
BA_ "SignalLongName" SG_ 1273 Sig1336 "Signal0909";
BA_ "SignalType" SG_ 1273 Sig1338 "ENM";
BA_ "SignalLongName" SG_ 1273 Sig1338 "Signal0911";
BA_ "SignalLongName" SG_ 1273 Sig1339 "Signal0912";
BA_ "SignalLongName" SG_ 1273 Sig1340 "Signal0913";
BA_ "SignalType" SG_ 1273 Sig1347 "ENM";
BA_ "SignalLongName" SG_ 1273 Sig1347 "Signal0920";
BA_ "SignalType" SG_ 1273 Sig1346 "ENM";
BA_ "SignalLongName" SG_ 1273 Sig1346 "Signal0919";
BA_ "SignalType" SG_ 1273 Sig1345 "ENM";
BA_ "SignalLongName" SG_ 1273 Sig1345 "Signal0918";
BA_ "SignalType" SG_ 1273 Sig1344 "ENM";
BA_ "SignalLongName" SG_ 1273 Sig1344 "Signal0917";
BA_ "SignalType" SG_ 1273 Sig1343 "ENM";
BA_ "SignalLongName" SG_ 1273 Sig1343 "Signal0916";
BA_ "SignalType" SG_ 1273 Sig1342 "ENM";
BA_ "SignalLongName" SG_ 1273 Sig1342 "Signal0915";
BA_ "SignalType" SG_ 1273 Sig1341 "ENM";
BA_ "SignalLongName" SG_ 1273 Sig1341 "Signal0914";
BA_ "SignalType" SG_ 1273 Sig1349 "ENM";
BA_ "SignalLongName" SG_ 1273 Sig1349 "Signal0922";
BA_ "SignalType" SG_ 1273 Sig1348 "ENM";
BA_ "SignalLongName" SG_ 1273 Sig1348 "Signal0921";
BA_ "SignalLongName" SG_ 1794 Sig1351 "Signal0896";
BA_ "SignalType" SG_ 1794 Sig1350 "ENM";
BA_ "SignalLongName" SG_ 1794 Sig1350 "Signal0895";
BA_ "SignalType" SG_ 1794 Sig1352 "ENM";
BA_ "SignalLongName" SG_ 1794 Sig1352 "Signal0897";
BA_ "SignalLongName" SG_ 1794 Sig1353 "Signal0898";
BA_ "SignalLongName" SG_ 1794 Sig1354 "Signal0899";
BA_ "SignalType" SG_ 1794 Sig1361 "ENM";
BA_ "SignalLongName" SG_ 1794 Sig1361 "Signal0906";
BA_ "SignalType" SG_ 1794 Sig1360 "ENM";
BA_ "SignalLongName" SG_ 1794 Sig1360 "Signal0905";
BA_ "SignalType" SG_ 1794 Sig1359 "ENM";
BA_ "SignalLongName" SG_ 1794 Sig1359 "Signal0904";
BA_ "SignalType" SG_ 1794 Sig1358 "ENM";
BA_ "SignalLongName" SG_ 1794 Sig1358 "Signal0903";
BA_ "SignalType" SG_ 1794 Sig1357 "ENM";
BA_ "SignalLongName" SG_ 1794 Sig1357 "Signal0902";
BA_ "SignalType" SG_ 1794 Sig1356 "ENM";
BA_ "SignalLongName" SG_ 1794 Sig1356 "Signal0901";
BA_ "SignalType" SG_ 1794 Sig1355 "ENM";
BA_ "SignalLongName" SG_ 1794 Sig1355 "Signal0900";
BA_ "SignalType" SG_ 1794 Sig1363 "ENM";
BA_ "SignalLongName" SG_ 1794 Sig1363 "Signal0908";
BA_ "SignalType" SG_ 1794 Sig1362 "ENM";
BA_ "SignalLongName" SG_ 1794 Sig1362 "Signal0907";
BA_ "SignalLongName" SG_ 1271 Sig1365 "Signal0924";
BA_ "SignalType" SG_ 1271 Sig1364 "ENM";
BA_ "SignalLongName" SG_ 1271 Sig1364 "Signal0923";
BA_ "SignalType" SG_ 1271 Sig1366 "ENM";
BA_ "SignalLongName" SG_ 1271 Sig1366 "Signal0925";
BA_ "SignalLongName" SG_ 1271 Sig1367 "Signal0926";
BA_ "SignalLongName" SG_ 1271 Sig1368 "Signal0927";
BA_ "SignalType" SG_ 1271 Sig1375 "ENM";
BA_ "SignalLongName" SG_ 1271 Sig1375 "Signal0934";
BA_ "SignalType" SG_ 1271 Sig1374 "ENM";
BA_ "SignalLongName" SG_ 1271 Sig1374 "Signal0933";
BA_ "SignalType" SG_ 1271 Sig1373 "ENM";
BA_ "SignalLongName" SG_ 1271 Sig1373 "Signal0932";
BA_ "SignalType" SG_ 1271 Sig1372 "ENM";
BA_ "SignalLongName" SG_ 1271 Sig1372 "Signal0931";
BA_ "SignalType" SG_ 1271 Sig1371 "ENM";
BA_ "SignalLongName" SG_ 1271 Sig1371 "Signal0930";
BA_ "SignalType" SG_ 1271 Sig1370 "ENM";
BA_ "SignalLongName" SG_ 1271 Sig1370 "Signal0929";
BA_ "SignalType" SG_ 1271 Sig1369 "ENM";
BA_ "SignalLongName" SG_ 1271 Sig1369 "Signal0928";
BA_ "SignalType" SG_ 1271 Sig1377 "ENM";
BA_ "SignalLongName" SG_ 1271 Sig1377 "Signal0936";
BA_ "SignalType" SG_ 1271 Sig1376 "ENM";
BA_ "SignalLongName" SG_ 1271 Sig1376 "Signal0935";
BA_ "SignalLongName" SG_ 1795 Sig1399 "Signal0966";
BA_ "SignalType" SG_ 1795 Sig1398 "ENM";
BA_ "SignalLongName" SG_ 1795 Sig1398 "Signal0965";
BA_ "SignalType" SG_ 1795 Sig1400 "ENM";
BA_ "SignalLongName" SG_ 1795 Sig1400 "Signal0967";
BA_ "SignalLongName" SG_ 1795 Sig1401 "Signal0968";
BA_ "SignalLongName" SG_ 1795 Sig1402 "Signal0969";
BA_ "SignalType" SG_ 1795 Sig1409 "ENM";
BA_ "SignalLongName" SG_ 1795 Sig1409 "Signal0976";
BA_ "SignalType" SG_ 1795 Sig1408 "ENM";
BA_ "SignalLongName" SG_ 1795 Sig1408 "Signal0975";
BA_ "SignalType" SG_ 1795 Sig1407 "ENM";
BA_ "SignalLongName" SG_ 1795 Sig1407 "Signal0974";
BA_ "SignalType" SG_ 1795 Sig1406 "ENM";
BA_ "SignalLongName" SG_ 1795 Sig1406 "Signal0973";
BA_ "SignalType" SG_ 1795 Sig1405 "ENM";
BA_ "SignalLongName" SG_ 1795 Sig1405 "Signal0972";
BA_ "SignalType" SG_ 1795 Sig1404 "ENM";
BA_ "SignalLongName" SG_ 1795 Sig1404 "Signal0971";
BA_ "SignalType" SG_ 1795 Sig1403 "ENM";
BA_ "SignalLongName" SG_ 1795 Sig1403 "Signal0970";
BA_ "SignalType" SG_ 1795 Sig1411 "ENM";
BA_ "SignalLongName" SG_ 1795 Sig1411 "Signal0978";
BA_ "SignalType" SG_ 1795 Sig1410 "ENM";
BA_ "SignalLongName" SG_ 1795 Sig1410 "Signal0977";
BA_ "SignalLongName" SG_ 1270 DTCI_EPS_DTCFailType "Diagnostic Trouble Code Information Extended - EPS : Diagnostic Trouble Code Failure Type";
BA_ "SignalType" SG_ 1270 DTCI_EPS_CnfrmdDTC "ENM";
BA_ "SignalLongName" SG_ 1270 DTCI_EPS_CnfrmdDTC "Diagnostic Trouble Code Information Extended - EPS : Confirmed DTC";
BA_ "SignalType" SG_ 1270 DTCI_EPS_DTCFaultType "ENM";
BA_ "SignalLongName" SG_ 1270 DTCI_EPS_DTCFaultType "Diagnostic Trouble Code Information Extended - EPS : Diagnostic Trouble Code Fault Type";
BA_ "SignalLongName" SG_ 1270 DTCI_EPS_DTCNumber "Diagnostic Trouble Code Information Extended - EPS : Diagnostic Trouble Code Number";
BA_ "SignalLongName" SG_ 1270 DTCI_EPS_DTCSource "Diagnostic Trouble Code Information Extended - EPS : Diagnostic Trouble Code Source";
BA_ "SignalType" SG_ 1270 DTCI_EPS_TstNCmpltdOpCyc "ENM";
BA_ "SignalLongName" SG_ 1270 DTCI_EPS_TstNCmpltdOpCyc "Diagnostic Trouble Code Information Extended - EPS : Test Not Completed This Operation Cycle";
BA_ "SignalType" SG_ 1270 DTCI_EPS_TstNCmpltdLstClr "ENM";
BA_ "SignalLongName" SG_ 1270 DTCI_EPS_TstNCmpltdLstClr "Diagnostic Trouble Code Information Extended - EPS : Test Not Completed Since Last Clear";
BA_ "SignalType" SG_ 1270 DTCI_EPS_TstFldOpCyc "ENM";
BA_ "SignalLongName" SG_ 1270 DTCI_EPS_TstFldOpCyc "Diagnostic Trouble Code Information Extended - EPS : Test Failed This Operation Cycle";
BA_ "SignalType" SG_ 1270 DTCI_EPS_TstFldLstClr "ENM";
BA_ "SignalLongName" SG_ 1270 DTCI_EPS_TstFldLstClr "Diagnostic Trouble Code Information Extended - EPS : Test Failed Since Last Clear";
BA_ "SignalType" SG_ 1270 DTCI_EPS_TstFld "ENM";
BA_ "SignalLongName" SG_ 1270 DTCI_EPS_TstFld "Diagnostic Trouble Code Information Extended - EPS : Test Failed";
BA_ "SignalType" SG_ 1270 DTCI_EPS_PndngDTC "ENM";
BA_ "SignalLongName" SG_ 1270 DTCI_EPS_PndngDTC "Diagnostic Trouble Code Information Extended - EPS : Pending DTC";
BA_ "SignalType" SG_ 1270 DTCI_EPS_DTCTriggered "ENM";
BA_ "SignalLongName" SG_ 1270 DTCI_EPS_DTCTriggered "Diagnostic Trouble Code Information Extended - EPS : Diagnostic Trouble Code Triggered";
BA_ "SignalType" SG_ 1270 DTCI_EPS_WrnIndTrggrd "ENM";
BA_ "SignalLongName" SG_ 1270 DTCI_EPS_WrnIndTrggrd "Diagnostic Trouble Code Information Extended - EPS : Warning Indicator Triggered";
BA_ "SignalType" SG_ 1270 DTCI_EPS_WrnIndRqd "ENM";
BA_ "SignalLongName" SG_ 1270 DTCI_EPS_WrnIndRqd "Diagnostic Trouble Code Information Extended - EPS : Warning Indicator Requested";
BA_ "SignalLongName" SG_ 1796 Sig1449 "Signal1008";
BA_ "SignalType" SG_ 1796 Sig1448 "ENM";
BA_ "SignalLongName" SG_ 1796 Sig1448 "Signal1007";
BA_ "SignalType" SG_ 1796 Sig1450 "ENM";
BA_ "SignalLongName" SG_ 1796 Sig1450 "Signal1009";
BA_ "SignalLongName" SG_ 1796 Sig1451 "Signal1010";
BA_ "SignalLongName" SG_ 1796 Sig1452 "Signal1011";
BA_ "SignalType" SG_ 1796 Sig1459 "ENM";
BA_ "SignalLongName" SG_ 1796 Sig1459 "Signal1018";
BA_ "SignalType" SG_ 1796 Sig1458 "ENM";
BA_ "SignalLongName" SG_ 1796 Sig1458 "Signal1017";
BA_ "SignalType" SG_ 1796 Sig1457 "ENM";
BA_ "SignalLongName" SG_ 1796 Sig1457 "Signal1016";
BA_ "SignalType" SG_ 1796 Sig1456 "ENM";
BA_ "SignalLongName" SG_ 1796 Sig1456 "Signal1015";
BA_ "SignalType" SG_ 1796 Sig1455 "ENM";
BA_ "SignalLongName" SG_ 1796 Sig1455 "Signal1014";
BA_ "SignalType" SG_ 1796 Sig1454 "ENM";
BA_ "SignalLongName" SG_ 1796 Sig1454 "Signal1013";
BA_ "SignalType" SG_ 1796 Sig1453 "ENM";
BA_ "SignalLongName" SG_ 1796 Sig1453 "Signal1012";
BA_ "SignalType" SG_ 1796 Sig1461 "ENM";
BA_ "SignalLongName" SG_ 1796 Sig1461 "Signal1020";
BA_ "SignalType" SG_ 1796 Sig1460 "ENM";
BA_ "SignalLongName" SG_ 1796 Sig1460 "Signal1019";
BA_ "SignalLongName" SG_ 1269 Sig1463 "Signal1022";
BA_ "SignalType" SG_ 1269 Sig1462 "ENM";
BA_ "SignalLongName" SG_ 1269 Sig1462 "Signal1021";
BA_ "SignalType" SG_ 1269 Sig1464 "ENM";
BA_ "SignalLongName" SG_ 1269 Sig1464 "Signal1023";
BA_ "SignalLongName" SG_ 1269 Sig1465 "Signal1024";
BA_ "SignalLongName" SG_ 1269 Sig1466 "Signal1025";
BA_ "SignalType" SG_ 1269 Sig1487 "ENM";
BA_ "SignalLongName" SG_ 1269 Sig1487 "Signal1032";
BA_ "SignalType" SG_ 1269 Sig1486 "ENM";
BA_ "SignalLongName" SG_ 1269 Sig1486 "Signal1031";
BA_ "SignalType" SG_ 1269 Sig1485 "ENM";
BA_ "SignalLongName" SG_ 1269 Sig1485 "Signal1030";
BA_ "SignalType" SG_ 1269 Sig1484 "ENM";
BA_ "SignalLongName" SG_ 1269 Sig1484 "Signal1029";
BA_ "SignalType" SG_ 1269 Sig1483 "ENM";
BA_ "SignalLongName" SG_ 1269 Sig1483 "Signal1028";
BA_ "SignalType" SG_ 1269 Sig1482 "ENM";
BA_ "SignalLongName" SG_ 1269 Sig1482 "Signal1027";
BA_ "SignalType" SG_ 1269 Sig1467 "ENM";
BA_ "SignalLongName" SG_ 1269 Sig1467 "Signal1026";
BA_ "SignalType" SG_ 1269 Sig1489 "ENM";
BA_ "SignalLongName" SG_ 1269 Sig1489 "Signal1034";
BA_ "SignalType" SG_ 1269 Sig1488 "ENM";
BA_ "SignalLongName" SG_ 1269 Sig1488 "Signal1033";
BA_ "SignalLongName" SG_ 1797 Sig1491 "Signal1050";
BA_ "SignalType" SG_ 1797 Sig1490 "ENM";
BA_ "SignalLongName" SG_ 1797 Sig1490 "Signal1049";
BA_ "SignalType" SG_ 1797 Sig1492 "ENM";
BA_ "SignalLongName" SG_ 1797 Sig1492 "Signal1051";
BA_ "SignalLongName" SG_ 1797 Sig1493 "Signal1052";
BA_ "SignalLongName" SG_ 1797 Sig1494 "Signal1053";
BA_ "SignalType" SG_ 1797 Sig1501 "ENM";
BA_ "SignalLongName" SG_ 1797 Sig1501 "Signal1060";
BA_ "SignalType" SG_ 1797 Sig1500 "ENM";
BA_ "SignalLongName" SG_ 1797 Sig1500 "Signal1059";
BA_ "SignalType" SG_ 1797 Sig1499 "ENM";
BA_ "SignalLongName" SG_ 1797 Sig1499 "Signal1058";
BA_ "SignalType" SG_ 1797 Sig1498 "ENM";
BA_ "SignalLongName" SG_ 1797 Sig1498 "Signal1057";
BA_ "SignalType" SG_ 1797 Sig1497 "ENM";
BA_ "SignalLongName" SG_ 1797 Sig1497 "Signal1056";
BA_ "SignalType" SG_ 1797 Sig1496 "ENM";
BA_ "SignalLongName" SG_ 1797 Sig1496 "Signal1055";
BA_ "SignalType" SG_ 1797 Sig1495 "ENM";
BA_ "SignalLongName" SG_ 1797 Sig1495 "Signal1054";
BA_ "SignalType" SG_ 1797 Sig1503 "ENM";
BA_ "SignalLongName" SG_ 1797 Sig1503 "Signal1062";
BA_ "SignalType" SG_ 1797 Sig1502 "ENM";
BA_ "SignalLongName" SG_ 1797 Sig1502 "Signal1061";
BA_ "SignalLongName" SG_ 1025 Sig1519 "Signal1078";
BA_ "SignalType" SG_ 1025 Sig1518 "ENM";
BA_ "SignalLongName" SG_ 1025 Sig1518 "Signal1077";
BA_ "SignalType" SG_ 1025 Sig1520 "ENM";
BA_ "SignalLongName" SG_ 1025 Sig1520 "Signal1079";
BA_ "SignalLongName" SG_ 1025 Sig1521 "Signal1080";
BA_ "SignalLongName" SG_ 1025 Sig1522 "Signal1081";
BA_ "SignalType" SG_ 1025 Sig1529 "ENM";
BA_ "SignalLongName" SG_ 1025 Sig1529 "Signal1088";
BA_ "SignalType" SG_ 1025 Sig1528 "ENM";
BA_ "SignalLongName" SG_ 1025 Sig1528 "Signal1087";
BA_ "SignalType" SG_ 1025 Sig1527 "ENM";
BA_ "SignalLongName" SG_ 1025 Sig1527 "Signal1086";
BA_ "SignalType" SG_ 1025 Sig1526 "ENM";
BA_ "SignalLongName" SG_ 1025 Sig1526 "Signal1085";
BA_ "SignalType" SG_ 1025 Sig1525 "ENM";
BA_ "SignalLongName" SG_ 1025 Sig1525 "Signal1084";
BA_ "SignalType" SG_ 1025 Sig1524 "ENM";
BA_ "SignalLongName" SG_ 1025 Sig1524 "Signal1083";
BA_ "SignalType" SG_ 1025 Sig1523 "ENM";
BA_ "SignalLongName" SG_ 1025 Sig1523 "Signal1082";
BA_ "SignalType" SG_ 1025 Sig1531 "ENM";
BA_ "SignalLongName" SG_ 1025 Sig1531 "Signal1090";
BA_ "SignalType" SG_ 1025 Sig1530 "ENM";
BA_ "SignalLongName" SG_ 1025 Sig1530 "Signal1089";
BA_ "SignalLongName" SG_ 1268 Sig1603 "Signal1162";
BA_ "SignalType" SG_ 1268 Sig1602 "ENM";
BA_ "SignalLongName" SG_ 1268 Sig1602 "Signal1161";
BA_ "SignalType" SG_ 1268 Sig1604 "ENM";
BA_ "SignalLongName" SG_ 1268 Sig1604 "Signal1163";
BA_ "SignalLongName" SG_ 1268 Sig1605 "Signal1164";
BA_ "SignalLongName" SG_ 1268 Sig1606 "Signal1165";
BA_ "SignalType" SG_ 1268 Sig1613 "ENM";
BA_ "SignalLongName" SG_ 1268 Sig1613 "Signal1172";
BA_ "SignalType" SG_ 1268 Sig1612 "ENM";
BA_ "SignalLongName" SG_ 1268 Sig1612 "Signal1171";
BA_ "SignalType" SG_ 1268 Sig1611 "ENM";
BA_ "SignalLongName" SG_ 1268 Sig1611 "Signal1170";
BA_ "SignalType" SG_ 1268 Sig1610 "ENM";
BA_ "SignalLongName" SG_ 1268 Sig1610 "Signal1169";
BA_ "SignalType" SG_ 1268 Sig1609 "ENM";
BA_ "SignalLongName" SG_ 1268 Sig1609 "Signal1168";
BA_ "SignalType" SG_ 1268 Sig1608 "ENM";
BA_ "SignalLongName" SG_ 1268 Sig1608 "Signal1167";
BA_ "SignalType" SG_ 1268 Sig1607 "ENM";
BA_ "SignalLongName" SG_ 1268 Sig1607 "Signal1166";
BA_ "SignalType" SG_ 1268 Sig1615 "ENM";
BA_ "SignalLongName" SG_ 1268 Sig1615 "Signal1174";
BA_ "SignalType" SG_ 1268 Sig1614 "ENM";
BA_ "SignalLongName" SG_ 1268 Sig1614 "Signal1173";
BA_ "SignalLongName" SG_ 1798 Sig1785 "Signal1344";
BA_ "SignalType" SG_ 1798 Sig1784 "ENM";
BA_ "SignalLongName" SG_ 1798 Sig1784 "Signal1343";
BA_ "SignalType" SG_ 1798 Sig1786 "ENM";
BA_ "SignalLongName" SG_ 1798 Sig1786 "Signal1345";
BA_ "SignalLongName" SG_ 1798 Sig1787 "Signal1346";
BA_ "SignalLongName" SG_ 1798 Sig1788 "Signal1347";
BA_ "SignalType" SG_ 1798 Sig1795 "ENM";
BA_ "SignalLongName" SG_ 1798 Sig1795 "Signal1354";
BA_ "SignalType" SG_ 1798 Sig1794 "ENM";
BA_ "SignalLongName" SG_ 1798 Sig1794 "Signal1353";
BA_ "SignalType" SG_ 1798 Sig1793 "ENM";
BA_ "SignalLongName" SG_ 1798 Sig1793 "Signal1352";
BA_ "SignalType" SG_ 1798 Sig1792 "ENM";
BA_ "SignalLongName" SG_ 1798 Sig1792 "Signal1351";
BA_ "SignalType" SG_ 1798 Sig1791 "ENM";
BA_ "SignalLongName" SG_ 1798 Sig1791 "Signal1350";
BA_ "SignalType" SG_ 1798 Sig1790 "ENM";
BA_ "SignalLongName" SG_ 1798 Sig1790 "Signal1349";
BA_ "SignalType" SG_ 1798 Sig1789 "ENM";
BA_ "SignalLongName" SG_ 1798 Sig1789 "Signal1348";
BA_ "SignalType" SG_ 1798 Sig1797 "ENM";
BA_ "SignalLongName" SG_ 1798 Sig1797 "Signal1356";
BA_ "SignalType" SG_ 1798 Sig1796 "ENM";
BA_ "SignalLongName" SG_ 1798 Sig1796 "Signal1355";
BA_ "SignalLongName" SG_ 1173 Sig1813 "Signal1372";
BA_ "SignalType" SG_ 1173 Sig1812 "ENM";
BA_ "SignalLongName" SG_ 1173 Sig1812 "Signal1371";
BA_ "SignalType" SG_ 1173 Sig1814 "ENM";
BA_ "SignalLongName" SG_ 1173 Sig1814 "Signal1373";
BA_ "SignalLongName" SG_ 1173 Sig1815 "Signal1374";
BA_ "SignalLongName" SG_ 1173 Sig1816 "Signal1375";
BA_ "SignalType" SG_ 1173 Sig1823 "ENM";
BA_ "SignalLongName" SG_ 1173 Sig1823 "Signal1382";
BA_ "SignalType" SG_ 1173 Sig1822 "ENM";
BA_ "SignalLongName" SG_ 1173 Sig1822 "Signal1381";
BA_ "SignalType" SG_ 1173 Sig1821 "ENM";
BA_ "SignalLongName" SG_ 1173 Sig1821 "Signal1380";
BA_ "SignalType" SG_ 1173 Sig1820 "ENM";
BA_ "SignalLongName" SG_ 1173 Sig1820 "Signal1379";
BA_ "SignalType" SG_ 1173 Sig1819 "ENM";
BA_ "SignalLongName" SG_ 1173 Sig1819 "Signal1378";
BA_ "SignalType" SG_ 1173 Sig1818 "ENM";
BA_ "SignalLongName" SG_ 1173 Sig1818 "Signal1377";
BA_ "SignalType" SG_ 1173 Sig1817 "ENM";
BA_ "SignalLongName" SG_ 1173 Sig1817 "Signal1376";
BA_ "SignalType" SG_ 1173 Sig1825 "ENM";
BA_ "SignalLongName" SG_ 1173 Sig1825 "Signal1384";
BA_ "SignalType" SG_ 1173 Sig1824 "ENM";
BA_ "SignalLongName" SG_ 1173 Sig1824 "Signal1383";
BA_ "SignalLongName" SG_ 1267 Sig1869 "Signal1428";
BA_ "SignalType" SG_ 1267 Sig1868 "ENM";
BA_ "SignalLongName" SG_ 1267 Sig1868 "Signal1427";
BA_ "SignalType" SG_ 1267 Sig1870 "ENM";
BA_ "SignalLongName" SG_ 1267 Sig1870 "Signal1429";
BA_ "SignalLongName" SG_ 1267 Sig1871 "Signal1430";
BA_ "SignalLongName" SG_ 1267 Sig1872 "Signal1431";
BA_ "SignalType" SG_ 1267 Sig1879 "ENM";
BA_ "SignalLongName" SG_ 1267 Sig1879 "Signal1438";
BA_ "SignalType" SG_ 1267 Sig1878 "ENM";
BA_ "SignalLongName" SG_ 1267 Sig1878 "Signal1437";
BA_ "SignalType" SG_ 1267 Sig1877 "ENM";
BA_ "SignalLongName" SG_ 1267 Sig1877 "Signal1436";
BA_ "SignalType" SG_ 1267 Sig1876 "ENM";
BA_ "SignalLongName" SG_ 1267 Sig1876 "Signal1435";
BA_ "SignalType" SG_ 1267 Sig1875 "ENM";
BA_ "SignalLongName" SG_ 1267 Sig1875 "Signal1434";
BA_ "SignalType" SG_ 1267 Sig1874 "ENM";
BA_ "SignalLongName" SG_ 1267 Sig1874 "Signal1433";
BA_ "SignalType" SG_ 1267 Sig1873 "ENM";
BA_ "SignalLongName" SG_ 1267 Sig1873 "Signal1432";
BA_ "SignalType" SG_ 1267 Sig1881 "ENM";
BA_ "SignalLongName" SG_ 1267 Sig1881 "Signal1440";
BA_ "SignalType" SG_ 1267 Sig1880 "ENM";
BA_ "SignalLongName" SG_ 1267 Sig1880 "Signal1439";
BA_ "SignalLongName" SG_ 1799 Sig2163 "Signal1722";
BA_ "SignalType" SG_ 1799 Sig2162 "ENM";
BA_ "SignalLongName" SG_ 1799 Sig2162 "Signal1721";
BA_ "SignalType" SG_ 1799 Sig2164 "ENM";
BA_ "SignalLongName" SG_ 1799 Sig2164 "Signal1723";
BA_ "SignalLongName" SG_ 1799 Sig2165 "Signal1724";
BA_ "SignalLongName" SG_ 1799 Sig2166 "Signal1725";
BA_ "SignalType" SG_ 1799 Sig2173 "ENM";
BA_ "SignalLongName" SG_ 1799 Sig2173 "Signal1732";
BA_ "SignalType" SG_ 1799 Sig2172 "ENM";
BA_ "SignalLongName" SG_ 1799 Sig2172 "Signal1731";
BA_ "SignalType" SG_ 1799 Sig2171 "ENM";
BA_ "SignalLongName" SG_ 1799 Sig2171 "Signal1730";
BA_ "SignalType" SG_ 1799 Sig2170 "ENM";
BA_ "SignalLongName" SG_ 1799 Sig2170 "Signal1729";
BA_ "SignalType" SG_ 1799 Sig2169 "ENM";
BA_ "SignalLongName" SG_ 1799 Sig2169 "Signal1728";
BA_ "SignalType" SG_ 1799 Sig2168 "ENM";
BA_ "SignalLongName" SG_ 1799 Sig2168 "Signal1727";
BA_ "SignalType" SG_ 1799 Sig2167 "ENM";
BA_ "SignalLongName" SG_ 1799 Sig2167 "Signal1726";
BA_ "SignalType" SG_ 1799 Sig2175 "ENM";
BA_ "SignalLongName" SG_ 1799 Sig2175 "Signal1734";
BA_ "SignalType" SG_ 1799 Sig2174 "ENM";
BA_ "SignalLongName" SG_ 1799 Sig2174 "Signal1733";
BA_ "SignalLongName" SG_ 1266 Sig2177 "Signal1736";
BA_ "SignalType" SG_ 1266 Sig2176 "ENM";
BA_ "SignalLongName" SG_ 1266 Sig2176 "Signal1735";
BA_ "SignalType" SG_ 1266 Sig2178 "ENM";
BA_ "SignalLongName" SG_ 1266 Sig2178 "Signal1737";
BA_ "SignalLongName" SG_ 1266 Sig2179 "Signal1738";
BA_ "SignalLongName" SG_ 1266 Sig2180 "Signal1739";
BA_ "SignalType" SG_ 1266 Sig2187 "ENM";
BA_ "SignalLongName" SG_ 1266 Sig2187 "Signal1746";
BA_ "SignalType" SG_ 1266 Sig2186 "ENM";
BA_ "SignalLongName" SG_ 1266 Sig2186 "Signal1745";
BA_ "SignalType" SG_ 1266 Sig2185 "ENM";
BA_ "SignalLongName" SG_ 1266 Sig2185 "Signal1744";
BA_ "SignalType" SG_ 1266 Sig2184 "ENM";
BA_ "SignalLongName" SG_ 1266 Sig2184 "Signal1743";
BA_ "SignalType" SG_ 1266 Sig2183 "ENM";
BA_ "SignalLongName" SG_ 1266 Sig2183 "Signal1742";
BA_ "SignalType" SG_ 1266 Sig2182 "ENM";
BA_ "SignalLongName" SG_ 1266 Sig2182 "Signal1741";
BA_ "SignalType" SG_ 1266 Sig2181 "ENM";
BA_ "SignalLongName" SG_ 1266 Sig2181 "Signal1740";
BA_ "SignalType" SG_ 1266 Sig2189 "ENM";
BA_ "SignalLongName" SG_ 1266 Sig2189 "Signal1748";
BA_ "SignalType" SG_ 1266 Sig2188 "ENM";
BA_ "SignalLongName" SG_ 1266 Sig2188 "Signal1747";
BA_ "SignalLongName" SG_ 1473 Sig2247 "Signal1806";
BA_ "SignalType" SG_ 1473 Sig2246 "ENM";
BA_ "SignalLongName" SG_ 1473 Sig2246 "Signal1805";
BA_ "SignalType" SG_ 1473 Sig2248 "ENM";
BA_ "SignalLongName" SG_ 1473 Sig2248 "Signal1807";
BA_ "SignalLongName" SG_ 1473 Sig2249 "Signal1808";
BA_ "SignalLongName" SG_ 1473 Sig2250 "Signal1809";
BA_ "SignalType" SG_ 1473 Sig2257 "ENM";
BA_ "SignalLongName" SG_ 1473 Sig2257 "Signal1816";
BA_ "SignalType" SG_ 1473 Sig2256 "ENM";
BA_ "SignalLongName" SG_ 1473 Sig2256 "Signal1815";
BA_ "SignalType" SG_ 1473 Sig2255 "ENM";
BA_ "SignalLongName" SG_ 1473 Sig2255 "Signal1814";
BA_ "SignalType" SG_ 1473 Sig2254 "ENM";
BA_ "SignalLongName" SG_ 1473 Sig2254 "Signal1813";
BA_ "SignalType" SG_ 1473 Sig2253 "ENM";
BA_ "SignalLongName" SG_ 1473 Sig2253 "Signal1812";
BA_ "SignalType" SG_ 1473 Sig2252 "ENM";
BA_ "SignalLongName" SG_ 1473 Sig2252 "Signal1811";
BA_ "SignalType" SG_ 1473 Sig2251 "ENM";
BA_ "SignalLongName" SG_ 1473 Sig2251 "Signal1810";
BA_ "SignalType" SG_ 1473 Sig2259 "ENM";
BA_ "SignalLongName" SG_ 1473 Sig2259 "Signal1818";
BA_ "SignalType" SG_ 1473 Sig2258 "ENM";
BA_ "SignalLongName" SG_ 1473 Sig2258 "Signal1817";
BA_ "SignalLongName" SG_ 1474 Sig2261 "Signal1820";
BA_ "SignalType" SG_ 1474 Sig2260 "ENM";
BA_ "SignalLongName" SG_ 1474 Sig2260 "Signal1819";
BA_ "SignalType" SG_ 1474 Sig2262 "ENM";
BA_ "SignalLongName" SG_ 1474 Sig2262 "Signal1821";
BA_ "SignalLongName" SG_ 1474 Sig2263 "Signal1822";
BA_ "SignalLongName" SG_ 1474 Sig2264 "Signal1823";
BA_ "SignalType" SG_ 1474 Sig2271 "ENM";
BA_ "SignalLongName" SG_ 1474 Sig2271 "Signal1830";
BA_ "SignalType" SG_ 1474 Sig2270 "ENM";
BA_ "SignalLongName" SG_ 1474 Sig2270 "Signal1829";
BA_ "SignalType" SG_ 1474 Sig2269 "ENM";
BA_ "SignalLongName" SG_ 1474 Sig2269 "Signal1828";
BA_ "SignalType" SG_ 1474 Sig2268 "ENM";
BA_ "SignalLongName" SG_ 1474 Sig2268 "Signal1827";
BA_ "SignalType" SG_ 1474 Sig2267 "ENM";
BA_ "SignalLongName" SG_ 1474 Sig2267 "Signal1826";
BA_ "SignalType" SG_ 1474 Sig2266 "ENM";
BA_ "SignalLongName" SG_ 1474 Sig2266 "Signal1825";
BA_ "SignalType" SG_ 1474 Sig2265 "ENM";
BA_ "SignalLongName" SG_ 1474 Sig2265 "Signal1824";
BA_ "SignalType" SG_ 1474 Sig2273 "ENM";
BA_ "SignalLongName" SG_ 1474 Sig2273 "Signal1832";
BA_ "SignalType" SG_ 1474 Sig2272 "ENM";
BA_ "SignalLongName" SG_ 1474 Sig2272 "Signal1831";
BA_ "SignalLongName" SG_ 1800 DTCI_VICM_DTCFailType "Diagnostic Trouble Code Information Extended - VICM : Diagnostic Trouble Code Failure Type";
BA_ "SignalType" SG_ 1800 DTCI_VICM_CnfrmdDTC "ENM";
BA_ "SignalLongName" SG_ 1800 DTCI_VICM_CnfrmdDTC "Diagnostic Trouble Code Information Extended - VICM : Confirmed DTC";
BA_ "SignalType" SG_ 1800 DTCI_VICM_DTCFaultType "ENM";
BA_ "SignalLongName" SG_ 1800 DTCI_VICM_DTCFaultType "Diagnostic Trouble Code Information Extended - VICM : Diagnostic Trouble Code Fault Type";
BA_ "SignalLongName" SG_ 1800 DTCI_VICM_DTCNumber "Diagnostic Trouble Code Information Extended - VICM : Diagnostic Trouble Code Number";
BA_ "SignalLongName" SG_ 1800 DTCI_VICM_DTCSource "Diagnostic Trouble Code Information Extended - VICM : Diagnostic Trouble Code Source";
BA_ "SignalType" SG_ 1800 DTCI_VICM_TstNCmpltdOpCyc "ENM";
BA_ "SignalLongName" SG_ 1800 DTCI_VICM_TstNCmpltdOpCyc "Diagnostic Trouble Code Information Extended - VICM : Test Not Completed This Operation Cycle";
BA_ "SignalType" SG_ 1800 DTCI_VICM_TstNCmpltdLstClr "ENM";
BA_ "SignalLongName" SG_ 1800 DTCI_VICM_TstNCmpltdLstClr "Diagnostic Trouble Code Information Extended - VICM : Test Not Completed Since Last Clear";
BA_ "SignalType" SG_ 1800 DTCI_VICM_TstFldOpCyc "ENM";
BA_ "SignalLongName" SG_ 1800 DTCI_VICM_TstFldOpCyc "Diagnostic Trouble Code Information Extended - VICM : Test Failed This Operation Cycle";
BA_ "SignalType" SG_ 1800 DTCI_VICM_TstFldLstClr "ENM";
BA_ "SignalLongName" SG_ 1800 DTCI_VICM_TstFldLstClr "Diagnostic Trouble Code Information Extended - VICM : Test Failed Since Last Clear";
BA_ "SignalType" SG_ 1800 DTCI_VICM_TstFld "ENM";
BA_ "SignalLongName" SG_ 1800 DTCI_VICM_TstFld "Diagnostic Trouble Code Information Extended - VICM : Test Failed";
BA_ "SignalType" SG_ 1800 DTCI_VICM_PndngDTC "ENM";
BA_ "SignalLongName" SG_ 1800 DTCI_VICM_PndngDTC "Diagnostic Trouble Code Information Extended - VICM : Pending DTC";
BA_ "SignalType" SG_ 1800 DTCI_VICM_DTCTriggered "ENM";
BA_ "SignalLongName" SG_ 1800 DTCI_VICM_DTCTriggered "Diagnostic Trouble Code Information Extended - VICM : Diagnostic Trouble Code Triggered";
BA_ "SignalType" SG_ 1800 DTCI_VICM_WrnIndTrggrd "ENM";
BA_ "SignalLongName" SG_ 1800 DTCI_VICM_WrnIndTrggrd "Diagnostic Trouble Code Information Extended - VICM : Warning Indicator Triggered";
BA_ "SignalType" SG_ 1800 DTCI_VICM_WrnIndRqd "ENM";
BA_ "SignalLongName" SG_ 1800 DTCI_VICM_WrnIndRqd "Diagnostic Trouble Code Information Extended - VICM : Warning Indicator Requested";
BA_ "SignalLongName" SG_ 1390 Sig2417 "Signal2326";
BA_ "SignalLongName" SG_ 872 Sig0720 "Signal2323";
BA_ "SignalLongName" SG_ 872 Sig0718 "Signal2322";
BA_ "SignalLongName" SG_ 872 Sig0717 "Signal2319";
BA_ "SignalType" SG_ 872 Sig0722 "ENM";
BA_ "SignalLongName" SG_ 872 Sig0722 "Signal2325";
BA_ "SignalType" SG_ 872 Sig0721 "ENM";
BA_ "SignalLongName" SG_ 872 Sig0721 "Signal2324";
BA_ "SignalType" SG_ 872 Sig0716 "ENM";
BA_ "SignalLongName" SG_ 872 Sig0716 "Signal2321";
BA_ "SignalLongName" SG_ 872 Sig0719 "Signal2320";
BA_ "SignalLongName" SG_ 920 DrvrMonSysInfo_PCSM "Driver Monitoring System Information Protected Counter Sync Message";
BA_ "SignalLongName" SG_ 186 DMSIP_MAC "Driver Monitoring System Information Protected : MAC";
BA_ "SignalLongName" SG_ 186 DMSIP_FCnt "Driver Monitoring System Information Protected : Freshness Counter";
BA_ "SignalType" SG_ 186 DMSIP_DrvrAttnStatAuth "ENM";
BA_ "SignalLongName" SG_ 186 DMSIP_DrvrAttnStatAuth "Driver Monitoring System Information Protected : Driver Attention State Authenticated";
BA_ "SignalType" SG_ 186 DMSDrvrAttnStatCnfdLvlAuth "ENM";
BA_ "SignalLongName" SG_ 186 DMSDrvrAttnStatCnfdLvlAuth "Driver Monitoring System Information Protected : Driver Monitoring System Driver Attention State Confidence Level Authenticated";
BA_ "SignalType" SG_ 186 DMSDrvrAttnStatAlgTypAuth "ENM";
BA_ "SignalLongName" SG_ 186 DMSDrvrAttnStatAlgTypAuth "Driver Monitoring System Information Protected : Driver Monitoring System Driver Attention State Algorithm Type Authenticated";
BA_ "SignalLongName" SG_ 186 DMSIP_DrvrAttnStatPrdAuth "Driver Monitoring System Information Protected : Driver Attention State Period Authenticated";
BA_ "SignalType" SG_ 186 DMSIP_DrvrAttnStatAuth_Inv "ENM";
BA_ "SignalLongName" SG_ 186 DMSIP_DrvrAttnStatAuth_Inv "Driver Monitoring System Information Protected : Driver Attention State Authenticated Invalid";
BA_ "SignalType" SG_ 186 DMSOpStatAuth "ENM";
BA_ "SignalLongName" SG_ 186 DMSOpStatAuth "Driver Monitoring System Information Protected : Driver Monitoring System Operation State Authenticated";
BA_ "SignalLongName" SG_ 186 DMSOpStatPrdAuth "Driver Monitoring System Information Protected : Driver Monitoring System Operation State Period Authenticated";
BA_ "SignalLongName" SG_ 186 DMSIP_ARC "Driver Monitoring System Information Protected : Alive Rolling Count";
BA_ "SignalLongName" SG_ 919 EBCMGnrlInfo2_PCSM "EBCM General Information 2 Protected Counter Sync Message";
BA_ "SignalLongName" SG_ 624 WRDSP_MAC "EBCM General Information 2 Protected : MAC";
BA_ "SignalLongName" SG_ 624 WRDSP_FCnt "EBCM General Information 2 Protected : Freshness Counter";
BA_ "SignalLongName" SG_ 624 VAP_ActlVehAccelAuth "EBCM General Information 2 Protected : Actual Vehicle Acceleration Authenticated";
BA_ "SignalType" SG_ 624 TBI2P_TrlrBrkgManAppAtvAuth "ENM";
BA_ "SignalLongName" SG_ 624 TBI2P_TrlrBrkgManAppAtvAuth "EBCM General Information 2 Protected : Trailer Braking Manual Apply Active Authenticated";
BA_ "SignalType" SG_ 624 BSAE44BP_AE44BrkgStsAuth "ENM";
BA_ "SignalLongName" SG_ 624 BSAE44BP_AE44BrkgStsAuth "EBCM General Information 2 Protected : Brake System Advanced Park Assist Braking Status Authenticated";
BA_ "SignalType" SG_ 624 WRDSP_RFAuth "ENM";
BA_ "SignalLongName" SG_ 624 WRDSP_RFAuth "EBCM General Information 2 Protected : Wheel Rotational Directional Status Right Front Authenticated";
BA_ "SignalType" SG_ 624 WRDSP_LRAuth "ENM";
BA_ "SignalLongName" SG_ 624 WRDSP_LRAuth "EBCM General Information 2 Protected : Wheel Rotational Directional Status Left Rear Authenticated";
BA_ "SignalType" SG_ 624 WRDSP_LFAuth "ENM";
BA_ "SignalLongName" SG_ 624 WRDSP_LFAuth "EBCM General Information 2 Protected : Wheel Rotational Directional Status Left Front Authenticated";
BA_ "SignalType" SG_ 624 VAP_ActlVehAccelAuth_Inv "ENM";
BA_ "SignalLongName" SG_ 624 VAP_ActlVehAccelAuth_Inv "EBCM General Information 2 Protected : Actual Vehicle Acceleration Authenticated Invalid";
BA_ "SignalType" SG_ 624 SuprRmtPrkBrkResp "ENM";
BA_ "SignalLongName" SG_ 624 SuprRmtPrkBrkResp "EBCM General Information 2 Protected : Supervised Remote Parking Brake Response";
BA_ "SignalLongName" SG_ 624 WRDSP_ARC "EBCM General Information 2 Protected : Alive Rolling Count";
BA_ "SignalType" SG_ 624 WRDSP_RRAuth "ENM";
BA_ "SignalLongName" SG_ 624 WRDSP_RRAuth "EBCM General Information 2 Protected : Wheel Rotational Directional Status Right Rear Authenticated";
BA_ "SignalLongName" SG_ 624 EBCMGI2P_Filler "EBCM General Information 2 Protected : Filler";
BA_ "SignalType" SG_ 2147745840 Sig2467 "ENM";
BA_ "SignalLongName" SG_ 2147745840 Sig2467 "Signal2349";
BA_ "SignalType" SG_ 2147745795 EBCM_AV_CAN2_ClscCANHrtBtActv "ENM";
BA_ "SignalLongName" SG_ 2147745795 EBCM_AV_CAN2_ClscCANHrtBtActv "EBCM_AV CAN 2 Classic CAN Heart Beat Active";
BA_ "SignalType" SG_ 2147745796 EBCM_CAN2_ClscCANHrtBtActv "ENM";
BA_ "SignalLongName" SG_ 2147745796 EBCM_CAN2_ClscCANHrtBtActv "EBCM CAN 2 Classic CAN Heart Beat Active";
BA_ "SignalType" SG_ 1445 CustmStbCtlRdctReqConf "ENM";
BA_ "SignalLongName" SG_ 1445 CustmStbCtlRdctReqConf "Custom Stability Control Reduction Request Confirmation";
BA_ "SignalType" SG_ 1413 TrlrConnStat "ENM";
BA_ "SignalLongName" SG_ 1413 TrlrConnStat "Trailer Connection Status";
BA_ "SignalType" SG_ 707 EGI5_Eng12vStrtrMtrCmmdOn "ENM";
BA_ "SignalLongName" SG_ 707 EGI5_Eng12vStrtrMtrCmmdOn "Serial Data 28 : Engine 12 Volt Starter Motor Commanded On";
BA_ "SignalType" SG_ 2147745800 Sig2502 "ENM";
BA_ "SignalLongName" SG_ 2147745800 Sig2502 "Signal2351";
BA_ "SignalType" SG_ 2147745801 ECP_E_CAN2_ClscCANHrtBtActv "ENM";
BA_ "SignalLongName" SG_ 2147745801 ECP_E_CAN2_ClscCANHrtBtActv "ECP_E CAN 2 Classic CAN Heart Beat Active";
BA_ "SignalType" SG_ 2147745816 Sig2506 "ENM";
BA_ "SignalLongName" SG_ 2147745816 Sig2506 "Signal2471";
BA_ "SignalType" SG_ 2147745815 Sig2507 "ENM";
BA_ "SignalLongName" SG_ 2147745815 Sig2507 "Signal2474";
BA_ "SignalType" SG_ 2147745802 Sig2509 "ENM";
BA_ "SignalLongName" SG_ 2147745802 Sig2509 "Signal2472";
BA_ "SignalType" SG_ 2147745803 Sig2511 "ENM";
BA_ "SignalLongName" SG_ 2147745803 Sig2511 "Signal2476";
BA_ "SignalLongName" SG_ 918 ELSDInfo_PCSM "Electronic Limited Slip Differential Information Protected Counter Sync Message";
BA_ "SignalLongName" SG_ 86 ELSDIP_MAC "Electronic Limited Slip Differential Information Protected : MAC";
BA_ "SignalLongName" SG_ 86 ELSDIP_FCnt "Electronic Limited Slip Differential Information Protected : Freshness Counter";
BA_ "SignalLongName" SG_ 86 ELSDIP_Filler "Electronic Limited Slip Differential Information Protected : Filler";
BA_ "SignalLongName" SG_ 86 ELSDIP_ARC "Electronic Limited Slip Differential Information Protected : Alive Rolling Count";
BA_ "SignalType" SG_ 86 ELSDIP_ActrStsAuth "ENM";
BA_ "SignalLongName" SG_ 86 ELSDIP_ActrStsAuth "Electronic Limited Slip Differential Information Protected : Actuator Status Authenticated";
BA_ "SignalLongName" SG_ 671 EOCMGnrlInfo1_PCSM "EOCM General Information 1 Protected Counter Sync Message";
BA_ "SignalLongName" SG_ 528 FIMRIMABP_MAC "EOCM General Information 1 Protected : MAC";
BA_ "SignalLongName" SG_ 528 FIMRIMABP_FCnt "EOCM General Information 1 Protected : Freshness Counter";
BA_ "SignalLongName" SG_ 528 FIMRIMABP_BrkgCtlAccelAuth "EOCM General Information 1 Protected : Rear Impact Mitigation Autonomous Braking Control Acceleration Authenticated";
BA_ "SignalLongName" SG_ 528 FIMRIMABP_BrkgLongAccelReqAuth "EOCM General Information 1 Protected : Front Impact Mitigation Collision Imminent Steering Autonomous Braking Longitudinal Acceleration Request Authenticated";
BA_ "SignalType" SG_ 528 FIMRIMABP_FIMCISAutBrkRqTypAuth "ENM";
BA_ "SignalLongName" SG_ 528 FIMRIMABP_FIMCISAutBrkRqTypAuth "EOCM General Information 1 Protected : Front Impact Mitigation Collision Imminent Steering Autonomous Brake Request Type Authenticated";
BA_ "SignalType" SG_ 528 FIMRIMABP_BrkgReqAuth "ENM";
BA_ "SignalLongName" SG_ 528 FIMRIMABP_BrkgReqAuth "EOCM General Information 1 Protected : Rear Impact Mitigation Autonomous Brake Braking Request Authenticated";
BA_ "SignalLongName" SG_ 528 RIMATRP_TrqRqstAuth "EOCM General Information 1 Protected : RIM Axle Torque Request Authenticated";
BA_ "SignalType" SG_ 528 RIMATRP_TrqRqstActAuth "ENM";
BA_ "SignalLongName" SG_ 528 RIMATRP_TrqRqstActAuth "EOCM General Information 1 Protected : RIM Axle Torque Request Active Authenticated";
BA_ "SignalType" SG_ 528 FIMRIMABP_ReqActvAuth "ENM";
BA_ "SignalLongName" SG_ 528 FIMRIMABP_ReqActvAuth "EOCM General Information 1 Protected : Front Impact Mitigation Collision Imminent Steering Autonomous Brake Request Active Authenticated";
BA_ "SignalType" SG_ 528 FIMRIMABP_RIMAutoBrkgReqTypAuth "ENM";
BA_ "SignalLongName" SG_ 528 FIMRIMABP_RIMAutoBrkgReqTypAuth "EOCM General Information 1 Protected : Rear Impact Mitigation Autonomous Brake Request Type Authenticated";
BA_ "SignalLongName" SG_ 528 EOCMGI1P_Filler "EOCM General Information 1 Protected : Filler";
BA_ "SignalLongName" SG_ 528 FIMRIMABP_ARC "EOCM General Information 1 Protected : Alive Rolling Count";
BA_ "SignalLongName" SG_ 1401 EOCMGnrlInfo2_PCSM "EOCM General Information 2 Protected Counter Sync Message";
BA_ "SignalLongName" SG_ 613 EOCMGI2P_MAC "EOCM General Information 2 Protected : MAC";
BA_ "SignalLongName" SG_ 613 EOCMGI2P_FCnt "EOCM General Information 2 Protected : Freshness Counter";
BA_ "SignalLongName" SG_ 613 EOCMGI2P_OSTmSyncMstrClckAuth "EOCM General Information 2 Protected : Object Sensor Time Sync Master Clock Authenticated";
BA_ "SignalType" SG_ 2147745797 Sig2535 "ENM";
BA_ "SignalLongName" SG_ 2147745797 Sig2535 "Signal2527";
BA_ "SignalType" SG_ 2147745798 Sig2538 "ENM";
BA_ "SignalLongName" SG_ 2147745798 Sig2538 "Signal2530";
BA_ "SignalType" SG_ 2147745819 Sig2542 "ENM";
BA_ "SignalLongName" SG_ 2147745819 Sig2542 "Signal2534";
BA_ "SignalType" SG_ 2147745817 EPS_CAN2_ClscCANHrtBtActv "ENM";
BA_ "SignalLongName" SG_ 2147745817 EPS_CAN2_ClscCANHrtBtActv "EPS CAN 2 Classic CAN Heart Beat Active";
BA_ "SignalType" SG_ 2147745818 Sig2546 "ENM";
BA_ "SignalLongName" SG_ 2147745818 Sig2546 "Signal2536";
BA_ "SignalLongName" SG_ 1389 ElecShftRngSecDisp_PCSM "Electronic Shift Range Secondary Display Protected Counter Sync Message";
BA_ "SignalLongName" SG_ 871 ESRSDP_MAC "Electronic Shift Range Secondary Display Protected : MAC";
BA_ "SignalLongName" SG_ 871 ESRSDP_FCnt "Electronic Shift Range Secondary Display Protected : Freshness Counter";
BA_ "SignalLongName" SG_ 871 ESRSDP_Filler "Electronic Shift Range Secondary Display Protected : Filler";
BA_ "SignalLongName" SG_ 871 ESRSDP_ARC "Electronic Shift Range Secondary Display Protected : Alive Rolling Count";
BA_ "SignalType" SG_ 871 ESRSDP_ElecShftRngSecDispAuth "ENM";
BA_ "SignalLongName" SG_ 871 ESRSDP_ElecShftRngSecDispAuth "Electronic Shift Range Secondary Display Protected : Electronic Shift Range Secondary Display Authenticated";
BA_ "SignalLongName" SG_ 1388 EnhdSrvsVhTpSp_PCSM "Enhanced Services Vehicle Top Speed Protected Counter Sync Message";
BA_ "SignalLongName" SG_ 869 ESVTSP_MAC "Enhanced Services Vehicle Top Speed Protected : MAC";
BA_ "SignalLongName" SG_ 869 ESVTSP_FCnt "Enhanced Services Vehicle Top Speed Protected : Freshness Counter";
BA_ "SignalLongName" SG_ 869 ESVTSP_EnhdSrvsVhTpSpLimValAuth "Enhanced Services Vehicle Top Speed Protected : Enhanced Services Vehicle Top Speed Limit Value Authenticated";
BA_ "SignalType" SG_ 869 ESVTSP_EnhdSrvsVhTpSpLimReqAuth "ENM";
BA_ "SignalLongName" SG_ 869 ESVTSP_EnhdSrvsVhTpSpLimReqAuth "Enhanced Services Vehicle Top Speed Protected : Enhanced Services Vehicle Top Speed Limit Request Authenticated";
BA_ "SignalLongName" SG_ 869 ESVTSP_ARC "Enhanced Services Vehicle Top Speed Protected : Alive Rolling Count";
BA_ "SignalLongName" SG_ 1507 EHCCI_HtrCoreCoolFlwRtFdbk "Estimated Heater Core Coolant Information : Heater Core Coolant Flowrate Feedback";
BA_ "SignalLongName" SG_ 1507 EHCCI_HtrCoreInCoolTemp "Estimated Heater Core Coolant Information : Heater Core In Coolant Temperature";
BA_ "SignalType" SG_ 1507 EHCCI_HtrCoreCoolFlwRtFdbk_Inv "ENM";
BA_ "SignalLongName" SG_ 1507 EHCCI_HtrCoreCoolFlwRtFdbk_Inv "Estimated Heater Core Coolant Information : Heater Core Coolant Flowrate Feedback Invalid";
BA_ "SignalLongName" SG_ 1507 EHCCI_HtrCoreOutCoolTemp "Estimated Heater Core Coolant Information : Heater Core Out Coolant Temperature";
BA_ "SignalType" SG_ 1507 EHCCI_HtrCoreInCoolTemp_Inv "ENM";
BA_ "SignalLongName" SG_ 1507 EHCCI_HtrCoreInCoolTemp_Inv "Estimated Heater Core Coolant Information : Heater Core In Coolant Temperature Invalid";
BA_ "SignalLongName" SG_ 1507 HtrCoreCoolMinFlwrtArbdReq "Estimated Heater Core Coolant Information : Heater Core Coolant Minimum Flowrate Arbitrated Request";
BA_ "SignalType" SG_ 1507 EHCCI_HtrCoreOutCoolTemp_Inv "ENM";
BA_ "SignalLongName" SG_ 1507 EHCCI_HtrCoreOutCoolTemp_Inv "Estimated Heater Core Coolant Information : Heater Core Out Coolant Temperature Invalid";
BA_ "SignalType" SG_ 1507 HtrCoreCoolMinFlwrtArbdReq_Inv "ENM";
BA_ "SignalLongName" SG_ 1507 HtrCoreCoolMinFlwrtArbdReq_Inv "Estimated Heater Core Coolant Information : Heater Core Coolant Minimum Flowrate Arbitrated Request Invalid";
BA_ "SignalLongName" SG_ 1507 EHCCI_CS "Estimated Heater Core Coolant Information : Checksum";
BA_ "SignalLongName" SG_ 1507 EHCCI_ARC "Estimated Heater Core Coolant Information : Alive Rolling Count";
BA_ "SignalLongName" SG_ 1387 ExtLgtWshWprInfo_PCSM "Exterior Lighting and Wash Wiper Information Protected Counter Sync Message";
BA_ "SignalLongName" SG_ 1324 ELWWIP_MAC "Exterior Lighting and Wash Wiper Information Protected : MAC";
BA_ "SignalLongName" SG_ 1324 ELWWIP_FCnt "Exterior Lighting and Wash Wiper Information Protected : Freshness Counter";
BA_ "SignalType" SG_ 1324 ELWWIP_CHMSLCmdAuth "ENM";
BA_ "SignalLongName" SG_ 1324 ELWWIP_CHMSLCmdAuth "Exterior Lighting and Wash Wiper Information Protected : CHMSL Command Authenticated";
BA_ "SignalType" SG_ 1324 ELWWIP_BrkLmpRtCmdAuth "ENM";
BA_ "SignalLongName" SG_ 1324 ELWWIP_BrkLmpRtCmdAuth "Exterior Lighting and Wash Wiper Information Protected : Brake Lamp Right Command Authenticated";
BA_ "SignalType" SG_ 1324 ELWWIP_BrkLmpLtCmdAuth "ENM";
BA_ "SignalLongName" SG_ 1324 ELWWIP_BrkLmpLtCmdAuth "Exterior Lighting and Wash Wiper Information Protected : Brake Lamp Left Command Authenticated";
BA_ "SignalType" SG_ 1324 ELWWIP_LoBmLtCmdAuth "ENM";
BA_ "SignalLongName" SG_ 1324 ELWWIP_LoBmLtCmdAuth "Exterior Lighting and Wash Wiper Information Protected : Low Beam Left Command Authenticated";
BA_ "SignalType" SG_ 1324 ELWWIP_HiBmRtCmdAuth "ENM";
BA_ "SignalLongName" SG_ 1324 ELWWIP_HiBmRtCmdAuth "Exterior Lighting and Wash Wiper Information Protected : High Beam Right Command Authenticated";
BA_ "SignalType" SG_ 1324 ELWWIP_HiBmLtCmdAuth "ENM";
BA_ "SignalLongName" SG_ 1324 ELWWIP_HiBmLtCmdAuth "Exterior Lighting and Wash Wiper Information Protected : High Beam Left Command Authenticated";
BA_ "SignalType" SG_ 1324 ELWWIP_TrlrRvrsLmpsCmdAuth "ENM";
BA_ "SignalLongName" SG_ 1324 ELWWIP_TrlrRvrsLmpsCmdAuth "Exterior Lighting and Wash Wiper Information Protected : Trailer Reverse Lamps Command Authenticated";
BA_ "SignalType" SG_ 1324 ELWWIP_RvrsLmpCmdAuth "ENM";
BA_ "SignalLongName" SG_ 1324 ELWWIP_RvrsLmpCmdAuth "Exterior Lighting and Wash Wiper Information Protected : Reverse Lamp Command Authenticated";
BA_ "SignalType" SG_ 1324 ELWWIP_LoBmRtCmdAuth "ENM";
BA_ "SignalLongName" SG_ 1324 ELWWIP_LoBmRtCmdAuth "Exterior Lighting and Wash Wiper Information Protected : Low Beam Right Command Authenticated";
BA_ "SignalLongName" SG_ 1324 ELWWIP_ARC "Exterior Lighting and Wash Wiper Information Protected : Alive Rolling Count";
BA_ "SignalType" SG_ 1324 ELWWIP_WshFrtRrDrvCmdAuth "ENM";
BA_ "SignalLongName" SG_ 1324 ELWWIP_WshFrtRrDrvCmdAuth "Exterior Lighting and Wash Wiper Information Protected : Wash Front Rear Drive Command Authenticated";
BA_ "SignalType" SG_ 1324 ELWWIP_WprFrtFtrReqAuth "ENM";
BA_ "SignalLongName" SG_ 1324 ELWWIP_WprFrtFtrReqAuth "Exterior Lighting and Wash Wiper Information Protected : Wiper Front Feature Request Authenticated";
BA_ "SignalType" SG_ 2147745820 Sig3206 "ENM";
BA_ "SignalLongName" SG_ 2147745820 Sig3206 "Signal3210";
BA_ "SignalType" SG_ 2147745804 Sig3257 "ENM";
BA_ "SignalLongName" SG_ 2147745804 Sig3257 "Signal3212";
BA_ "SignalLongName" SG_ 1386 Sig3400 "Signal3229";
BA_ "SignalLongName" SG_ 611 Sig3246 "Signal3228";
BA_ "SignalLongName" SG_ 611 Sig3239 "Signal3227";
BA_ "SignalType" SG_ 611 Sig3242 "ENM";
BA_ "SignalLongName" SG_ 611 Sig3242 "Signal3225";
BA_ "SignalType" SG_ 611 Sig3241 "ENM";
BA_ "SignalLongName" SG_ 611 Sig3241 "Signal3222";
BA_ "SignalType" SG_ 611 Sig3240 "ENM";
BA_ "SignalLongName" SG_ 611 Sig3240 "Signal3221";
BA_ "SignalType" SG_ 611 Sig3244 "ENM";
BA_ "SignalLongName" SG_ 611 Sig3244 "Signal3223";
BA_ "SignalType" SG_ 611 FOPMPI1P_FOPLdShdngReqAuth "ENM";
BA_ "SignalLongName" SG_ 611 FOPMPI1P_FOPLdShdngReqAuth "Fail Operational Power Module Primary Information 1 Protected : Fail Operational Power Load Shedding Request Authenticated";
BA_ "SignalType" SG_ 611 Sig3243 "ENM";
BA_ "SignalLongName" SG_ 611 Sig3243 "Signal3226";
BA_ "SignalLongName" SG_ 611 Sig3238 "Signal3220";
BA_ "SignalType" SG_ 611 Sig3245 "ENM";
BA_ "SignalLongName" SG_ 611 Sig3245 "Signal3224";
BA_ "SignalLongName" SG_ 1508 Sig3230 "Signal3346";
BA_ "SignalLongName" SG_ 1508 Sig3232 "Signal3348";
BA_ "SignalType" SG_ 1508 Sig3231 "ENM";
BA_ "SignalLongName" SG_ 1508 Sig3231 "Signal3347";
BA_ "SignalType" SG_ 1508 Sig3233 "ENM";
BA_ "SignalLongName" SG_ 1508 Sig3233 "Signal3349";
BA_ "SignalLongName" SG_ 1508 Sig3229 "Signal3345";
BA_ "SignalLongName" SG_ 1508 Sig3228 "Signal3344";
VAL_ 70 ABSMPI1P_BrkModStsAuth 0 "Unknown" 1 "Capable" 2 "Active" 3 "Failed" ;
VAL_ 70 ABSMPI1P_ADIMCmdMsgStsAuth 0 "Unknown" 1 "Communication Normal" 2 "Main Communication Failed" 3 "Redundant Communication Failed" 4 "Dual Communication Failure" ;
VAL_ 70 ABSMPI1P_ABSStsAuth 0 "Unknown" 1 "Available" 2 "Active" 3 "Failed" ;
VAL_ 70 ABSMPI1P_DiagBrkPresReqStsAuth 0 "Unknown" 1 "No Dynamic Request" 2 "Primary Braking Request Honored" 3 "Secondary Braking Request Honored" 4 "Request Cancelled" ;
VAL_ 70 ABSMPI1P_DiagBrkPresReqAvalAuth 0 "Not Available" 1 "Available" 2 "Available PBM Only" ;
VAL_ 70 ABSMPI1P_BrkTrqSfcntStndstlAuth 0 "FALSE" 1 "TRUE" ;
VAL_ 70 ABSMPI1P_BrkSysStsAuth 0 "Unknown" 1 "Full Function" 2 "Degraded 1" 3 "Degraded 2" 4 "Degraded 3" 5 "Degraded 4" 6 "Degraded 5" ;
VAL_ 70 ABSMPI1P_ElecBrkDstSysStsAuth 0 "Unknown" 1 "Available" 2 "Active" 3 "Failed" ;
VAL_ 70 ABSMPI1P_ESCSysStsAuth 0 "Unknown" 1 "Available" 2 "Active" 3 "Failed" ;
VAL_ 70 ABSMPI1P_EstdSrfcFCoefTypAuth 0 "Unknown" 1 "Minimum Surface Estimate" 2 "Actual Surface Estimate" 3 "Invalid" ;
VAL_ 70 ABSMPI1P_PBMSbsysStsPriAuth 0 "Unknown" 1 "Full Function" 2 "Fault Tolerant" 3 "ESC Failed" 4 "ABS/ESC 3WSS" 5 "Service Brake Only" 6 "Failed" ;
VAL_ 70 ABSMPI1P_PBMArbtrtnStsPriAuth 0 "Unknown" 1 "No Autonomous Request" 2 "Main Autonomous Request Honored" 3 "Redundant Autonomous Request Honored" 4 "Default Brake Apply Autonomous Mode" 5 "Default Brake Apply FAXVC" 6 "Default Brake Apply FAXVC EPB Switch" 7 "PBM Diagnostic Pressure Request Honored" 8 "SBM Diagnostic Pressure Request Honored" 9 "ETRS Request Honored" 10 "Default Brake Apply No Torque" ;
VAL_ 70 ABSMPI1P_WhlBrkPresAuth_Inv 0 "FALSE" 1 "TRUE" ;
VAL_ 70 ABSMPI1P_TCSStsAuth 0 "Unknown" 1 "Available" 2 "Active" 3 "Failed" ;
VAL_ 70 ABSMPI1P_StndstlHldReqStsAuth 0 "Not Active" 1 "Active" 2 "Cancelled" ;
VAL_ 70 ABSMPI1P_SpltFCoefCtlAuth 0 "Inactive" 1 "Split Driver Side Low" 2 "Split Driver Side High" ;
VAL_ 70 ABSMPI1P_SBMFltDtdByPBMPriAuth 0 "FALSE" 1 "TRUE" ;
VAL_ 70 MnElecPrkBrkSwStsPriAuth 0 "Unknown" 1 "Not Active" 2 "Active" 3 "Apply" 4 "Release" 5 "Faulted" ;
VAL_ 78 ABSRPI1P_BrkModStsAuth 0 "Unknown" 1 "Capable" 2 "Active" 3 "Failed" ;
VAL_ 78 ABSRPI1P_ADIMCmdMsgStsAuth 0 "Unknown" 1 "Communication Normal" 2 "Main Communication Failed" 3 "Redundant Communication Failed" 4 "Dual Communication Failure" ;
VAL_ 78 ABSRPI1P_ABSStsAuth 0 "Unknown" 1 "Available" 2 "Active" 3 "Failed" ;
VAL_ 78 ABSRPI1P_BrkTrqSfcntStndstlAuth 0 "FALSE" 1 "TRUE" ;
VAL_ 78 ABSRPI1P_BrkSysStsAuth 0 "Unknown" 1 "Full Function" 2 "Degraded 1" 3 "Degraded 2" 4 "Degraded 3" 5 "Degraded 4" 6 "Degraded 5" ;
VAL_ 78 ABSRPI1P_BrkSysBrkLgtsReqdAuth 0 "FALSE" 1 "TRUE" ;
VAL_ 78 ABSRPI1P_CSPrdtdATRqIntvTypAuth 0 "No Intervention" 1 "Maximum Limit" 2 "Minimum Limit" 3 "Minimum and Maximum Limit" ;
VAL_ 78 ABSRPI1P_ChsSysATRqFncAuth 0 "None" 1 "Engine Drag Control" 2 "Traction Control" 3 "Electronic Stability Control" 4 "Active Safety Braking" 5 "Driveline Protection" 6 "Power Hop" 7 "Performance Traction Control" 8 "Hill Descent Control" 9 "Advanced Park Assist" 10 "Brake System Cruise Control" 11 "Torque Vectoring" 12 "Launch Control" 13 "Line Lock" 14 "Regenerative Torque Limitation" ;
VAL_ 78 ABSRPI1P_ChsSysATRqRespTypAuth 0 "Inactive" 1 "Pleasability Limited Request" 2 "Maximum Range Request" 3 "Automatic Actuator Selection" 4 "Braking Torque Request" ;
VAL_ 78 ABSRPI1P_ChsSysTtBrkATAuth_Inv 0 "FALSE" 1 "TRUE" ;
VAL_ 78 ABSRPI1P_ElcBrkDstSysStsAuth 0 "Unknown" 1 "Available" 2 "Active" 3 "Failed" ;
VAL_ 78 ABSRPI1P_ESCSysStsAuth 0 "Unknown" 1 "Available" 2 "Active" 3 "Failed" ;
VAL_ 78 ABSRPI1P_EstdSrfcFCoefTypAuth 0 "Unknown" 1 "Minimum Surface Estimate" 2 "Actual Surface Estimate" 3 "Invalid" ;
VAL_ 78 ABSRPI1P_SBMArbtrtnStsPriAuth 0 "Unknown" 1 "No Autonomous Request" 2 "Main Autonomous Request Honored" 3 "Redundant Autonomous Request Honored" 4 "Default Brake Apply No Torque" 5 "Default Brake Apply FAXVC" 6 "Default Brake Apply Autonomous Mode" 7 "Diagnostic Pressure Request Honored" 8 "ETRS Request Honored" ;
VAL_ 78 ABSRPI1P_PBMFltDtdBySBMPriAuth 0 "FALSE" 1 "TRUE" ;
VAL_ 78 ABSRPI1P_StndstlHldRqStsAuth 0 "Not Active" 1 "Active" 2 "Cancelled" ;
VAL_ 78 ABSRPI1P_SpltFCoefCtlAuth 0 "Inactive" 1 "Split Driver Side Low" 2 "Split Driver Side High" ;
VAL_ 78 ABSRPI1P_SBMSbsysStsPriAuth 0 "Unknown" 1 "Full Function" 2 "Fault Tolerant" 3 "RESC Failed" 4 "Service Brake Only" 5 "Failed" ;
VAL_ 78 ABSRPI1P_TCSStsAuth 0 "Unknown" 1 "Available" 2 "Active" 3 "Failed" ;
VAL_ 78 ABSRPI1P_WhlAnglrVelLFAuth_Inv 0 "FALSE" 1 "TRUE" ;
VAL_ 78 ABSRPI1P_WhlAnglrVelLRAuth_Inv 0 "FALSE" 1 "TRUE" ;
VAL_ 78 ABSRPI1P_WhlAnglrVelRFAuth_Inv 0 "FALSE" 1 "TRUE" ;
VAL_ 78 ABSRPI1P_WhlAnglrVelRRAuth_Inv 0 "FALSE" 1 "TRUE" ;
VAL_ 78 ABSRPI1P_WhlBrkPrsLFAuth_Inv 0 "FALSE" 1 "TRUE" ;
VAL_ 78 ABSRPI1P_WhlBrkPrsLRAuth_Inv 0 "FALSE" 1 "TRUE" ;
VAL_ 78 ABSRPI1P_WhlBrkPrsRFAuth_Inv 0 "FALSE" 1 "TRUE" ;
VAL_ 78 ABSRPI1P_WhlBrkPrsRRAuth_Inv 0 "FALSE" 1 "TRUE" ;
VAL_ 1498 AutoLnChgCstAvlFlg5 0 "FALSE" 1 "TRUE" ;
VAL_ 1498 AutoLnChgCstAvlFlg4 0 "FALSE" 1 "TRUE" ;
VAL_ 1498 AutoLnChgCstAvlFlg3 0 "FALSE" 1 "TRUE" ;
VAL_ 1498 AutoLnChgCstAvlFlg2 0 "FALSE" 1 "TRUE" ;
VAL_ 1498 AutoLnChgCstAvlFlg1 0 "FALSE" 1 "TRUE" ;
VAL_ 1498 AutoLnChgCstCurrSetVal 0 "Setting Unkown" 1 "Off" 2 "On" 3 "LCOD" 4 "LCOD and ALC" ;
VAL_ 1498 AutoLnChgCstSetAval 0 "FALSE" 1 "TRUE" ;
VAL_ 1498 AutoLnChgCstAvlFlg7 0 "FALSE" 1 "TRUE" ;
VAL_ 1498 AutoLnChgCstAvlFlg6 0 "FALSE" 1 "TRUE" ;
VAL_ 68 AVMCMI1P_ADSRedntIPSPwrdOnAuth 0 "FALSE" 1 "TRUE" ;
VAL_ 68 AVMCMI1P_AutoCtlRqStrgModeAuth 0 "Inactive" 1 "Active" ;
VAL_ 68 AVMCMI1P_AutoVehOprtlStatAuth 0 "Inhibit Motion" 1 "ADSC Control (no override)" 2 "FAXVC Control" 3 "XVC Control" 4 "DVT" 5 "AVT" 6 "SVT" 7 "Operational Safety Check" ;
VAL_ 68 AVMCMI1P_AutoTransRngRqAuth 0 "No Action" 1 "Park" 2 "Reverse" 3 "Neutral" 4 "Drive" ;
VAL_ 68 AVMCMI1P_AutoCtlrEPBRqAuth 0 "No Request" 1 "Request Apply" 2 "Request Release" ;
VAL_ 68 AVMCMI1P_AutoCtlrBrkTqRqTypAuth 0 "No Request" 1 "Brake Torque Request" 2 "Standstill Hold Request" ;
VAL_ 68 AVMCMI1P_DgWhlBrkPrsRqTgtAuth 0 "Not Active" 1 "Primary Brake Request" 2 "Secondary Brake Request" ;
VAL_ 68 AVMCMI1P_FailOprtlPwrAvSTRqAuth 0 "No Request" 1 "XVC Self Test Request" 2 "AV Self Test Request" 3 "FAXVC Self Test Request" ;
VAL_ 68 AVMCMnFAXVCEqpdStsPriAuth 0 "Unknown" 1 "Not Equipped" 2 "Equipped" 3 "Error" ;
VAL_ 1307 ALGIP_RrAxlLckFdbkAuth 0 "Open" 1 "Locked" 2 "Unknown" ;
VAL_ 1307 ALGIP_RrAxlLckCmndOnAuth 0 "FALSE" 1 "TRUE" ;
VAL_ 1307 ALGIP_FrtAxlLckFdbkAuth 0 "Open" 1 "Locked" 2 "Unknown" ;
VAL_ 1307 ALGIP_FrtAxlLckCmndOnAuth 0 "FALSE" 1 "TRUE" ;
VAL_ 2147745799 Sig0522 0 "FALSE" 1 "TRUE" ;
VAL_ 2147745812 Sig0524 0 "FALSE" 1 "TRUE" ;
VAL_ 62 BGI3P_BrkPedModrTrvlAchAuth_Inv 0 "FALSE" 1 "TRUE" ;
VAL_ 62 BGI3P_BrkPedModrTrvlAchAuth 0 "FALSE" 1 "TRUE" ;
VAL_ 62 BGI3P_BrkPedInitTrvlAchAuth_Inv 0 "FALSE" 1 "TRUE" ;
VAL_ 62 BGI3P_BrkPedInitTrvlAchAuth 0 "FALSE" 1 "TRUE" ;
VAL_ 62 BGI3P_CruzSecSwStsAuth 0 "Indeterminate" 1 "No_Activation" 2 "Speed Increase High" 3 "Speed Decrease High" 4 "Gap Selected" 5 "Lane Centering Control" 6 "Lane Departure Warning / Lane Keep Assist" 7 "Short to Ground" 8 "Open/Short to Power" 9 "Between_Ranges" ;
VAL_ 62 BGI3P_BrkPedPstnAuth_Inv 0 "FALSE" 1 "TRUE" ;
VAL_ 62 CruzCtlSwBank1Sts 0 "No Activation" 1 "Cancel" 2 "Cruise On/Off" 3 "Gap" 4 "Lane Centering Control" 5 "Lane Departure Warning" 6 "Short to Ground" 7 "Open/Short to Power" 8 "Between Ranges" 9 "Indeterminate" ;
VAL_ 62 BGI3P_CruzSpdLmtrSwStsAuth 0 "Indeterminate" 1 "No_Activation" 2 "Resume" 3 "Set" 4 "SL/SW On/Off" 5 "Cruise On/Off" 6 "Cancel" 7 "Short to Ground" 8 "Open/Short to Power" 9 "Between_Ranges" ;
VAL_ 62 StrgWhlCruzCtlCfg 0 "Legacy" 1 "New" ;
VAL_ 62 CruzCtlSwBank2Sts 0 "No Activation" 1 "Set" 2 "Decrease High" 3 "Low/Manual" 4 "Gap 2" 5 "Resume" 6 "Increase High" 7 "Short to Ground" 8 "Open/Short to Power" 9 "Between Ranges" 10 "Indeterminate" ;
VAL_ 880 BSPMP_BkupSysPwrModeAuth_Inv 0 "FALSE" 1 "TRUE" ;
VAL_ 880 BSPMP_BkupSysPwrModeAuth 0 "Off" 1 "Accessory" 2 "Run" 3 "Start Request" 4 "Propulsion" ;
VAL_ 880 BSPMP_SecRunCrnkCmdActvAuth_Inv 0 "FALSE" 1 "TRUE" ;
VAL_ 880 BSPMP_SecRunCrnkCmdActvAuth 0 "FALSE" 1 "TRUE" ;
VAL_ 880 BSPMP_SecPwrModePBActvAuth_Inv 0 "FALSE" 1 "TRUE" ;
VAL_ 880 BSPMP_SecPwrModePBActvAuth 0 "FALSE" 1 "TRUE" ;
VAL_ 880 BSPMP_RmtProgmActvAuth 0 "FALSE" 1 "TRUE" ;
VAL_ 1301 Sig0479 0 "FALSE" 1 "TRUE" ;
VAL_ 1301 Sig0481 0 "FALSE" 1 "TRUE" ;
VAL_ 108 Sig0485 0 "None" 1 "Critical Voltage-related Fault" 2 "Critical Non Voltage-related Fault" 3 "Non Critical Recoverable Fault" ;
VAL_ 108 Sig0487 0 "FALSE" 1 "TRUE" ;
VAL_ 108 Sig0489 0 "FALSE" 1 "TRUE" ;
VAL_ 98 Sig0496 0 "Inactive" 1 "Maximum Range" ;
VAL_ 98 Sig0498 0 "Disable Normal Power Stage" 1 "Torque Control" 2 "Shutdown Initiated" 3 "Disable Immediate" 4 "Normal Charge with Internal Setpoint" 5 "Normal Charge with External Setpoint" ;
VAL_ 66 BSIS2P_BSTrqOvlyDlTrqCmdAtvAuth 0 "FALSE" 1 "TRUE" ;
VAL_ 66 BSIS2P_ABSFldAuth 0 "FALSE" 1 "TRUE" ;
VAL_ 66 BSIS2P_ABSAtvAuth 0 "FALSE" 1 "TRUE" ;
VAL_ 66 BrkPdlDrvAppPrsDetcdAuth_Inv 0 "FALSE" 1 "TRUE" ;
VAL_ 66 BrkPdlDrvAppPrsDetcdAuth 0 "FALSE" 1 "TRUE" ;
VAL_ 66 BSIS2P_BrkPdlDrvApplPresAuth_Inv 0 "FALSE" 1 "TRUE" ;
VAL_ 1506 CCHI_CalcdTgtCabinHtLd_Inv 0 "FALSE" 1 "TRUE" ;
VAL_ 1506 CCHI_MinFlwRateReq_Inv 0 "FALSE" 1 "TRUE" ;
VAL_ 1506 CCHI_PrtyHtReq_Inv 0 "FALSE" 1 "TRUE" ;
VAL_ 1506 CCHI_PrtyHtReq 0 "No Action" 1 "Low" 2 "Medium" 3 "High" ;
VAL_ 1506 CCHI_MinTgtCoolTemp_Inv 0 "FALSE" 1 "TRUE" ;
VAL_ 2147745813 Sig0715 0 "FALSE" 1 "TRUE" ;
VAL_ 2147745814 DMS_CAN2_ClscCANHrtBtActv 0 "FALSE" 1 "TRUE" ;
VAL_ 1530 Sig1112 0 "FALSE" 1 "TRUE" ;
VAL_ 1530 Sig1114 0 "Not Supported" 1 "Type A" 2 "Type B" 3 "Type C" ;
VAL_ 1530 Sig1123 0 "FALSE" 1 "TRUE" ;
VAL_ 1530 Sig1122 0 "FALSE" 1 "TRUE" ;
VAL_ 1530 Sig1121 0 "FALSE" 1 "TRUE" ;
VAL_ 1530 Sig1120 0 "FALSE" 1 "TRUE" ;
VAL_ 1530 Sig1119 0 "FALSE" 1 "TRUE" ;
VAL_ 1530 Sig1118 0 "FALSE" 1 "TRUE" ;
VAL_ 1530 Sig1117 0 "FALSE" 1 "TRUE" ;
VAL_ 1530 Sig1125 0 "FALSE" 1 "TRUE" ;
VAL_ 1530 Sig1124 0 "FALSE" 1 "TRUE" ;
VAL_ 1531 Sig1126 0 "FALSE" 1 "TRUE" ;
VAL_ 1531 Sig1128 0 "Not Supported" 1 "Type A" 2 "Type B" 3 "Type C" ;
VAL_ 1531 Sig1137 0 "FALSE" 1 "TRUE" ;
VAL_ 1531 Sig1136 0 "FALSE" 1 "TRUE" ;
VAL_ 1531 Sig1135 0 "FALSE" 1 "TRUE" ;
VAL_ 1531 Sig1134 0 "FALSE" 1 "TRUE" ;
VAL_ 1531 Sig1133 0 "FALSE" 1 "TRUE" ;
VAL_ 1531 Sig1132 0 "FALSE" 1 "TRUE" ;
VAL_ 1531 Sig1131 0 "FALSE" 1 "TRUE" ;
VAL_ 1531 Sig1139 0 "FALSE" 1 "TRUE" ;
VAL_ 1531 Sig1138 0 "FALSE" 1 "TRUE" ;
VAL_ 1532 Sig1210 0 "FALSE" 1 "TRUE" ;
VAL_ 1532 Sig1212 0 "Not Supported" 1 "Type A" 2 "Type B" 3 "Type C" ;
VAL_ 1532 Sig1221 0 "FALSE" 1 "TRUE" ;
VAL_ 1532 Sig1220 0 "FALSE" 1 "TRUE" ;
VAL_ 1532 Sig1219 0 "FALSE" 1 "TRUE" ;
VAL_ 1532 Sig1218 0 "FALSE" 1 "TRUE" ;
VAL_ 1532 Sig1217 0 "FALSE" 1 "TRUE" ;
VAL_ 1532 Sig1216 0 "FALSE" 1 "TRUE" ;
VAL_ 1532 Sig1215 0 "FALSE" 1 "TRUE" ;
VAL_ 1532 Sig1223 0 "FALSE" 1 "TRUE" ;
VAL_ 1532 Sig1222 0 "FALSE" 1 "TRUE" ;
VAL_ 1533 Sig1230 0 "FALSE" 1 "TRUE" ;
VAL_ 1533 Sig1232 0 "Not Supported" 1 "Type A" 2 "Type B" 3 "Type C" ;
VAL_ 1533 Sig1241 0 "FALSE" 1 "TRUE" ;
VAL_ 1533 Sig1240 0 "FALSE" 1 "TRUE" ;
VAL_ 1533 Sig1239 0 "FALSE" 1 "TRUE" ;
VAL_ 1533 Sig1238 0 "FALSE" 1 "TRUE" ;
VAL_ 1533 Sig1237 0 "FALSE" 1 "TRUE" ;
VAL_ 1533 Sig1236 0 "FALSE" 1 "TRUE" ;
VAL_ 1533 Sig1235 0 "FALSE" 1 "TRUE" ;
VAL_ 1533 Sig1243 0 "FALSE" 1 "TRUE" ;
VAL_ 1533 Sig1242 0 "FALSE" 1 "TRUE" ;
VAL_ 1276 Sig1224 0 "FALSE" 1 "TRUE" ;
VAL_ 1276 Sig1226 0 "Not Supported" 1 "Type A" 2 "Type B" 3 "Type C" ;
VAL_ 1276 Sig1249 0 "FALSE" 1 "TRUE" ;
VAL_ 1276 Sig1248 0 "FALSE" 1 "TRUE" ;
VAL_ 1276 Sig1247 0 "FALSE" 1 "TRUE" ;
VAL_ 1276 Sig1246 0 "FALSE" 1 "TRUE" ;
VAL_ 1276 Sig1245 0 "FALSE" 1 "TRUE" ;
VAL_ 1276 Sig1244 0 "FALSE" 1 "TRUE" ;
VAL_ 1276 Sig1229 0 "FALSE" 1 "TRUE" ;
VAL_ 1276 Sig1251 0 "FALSE" 1 "TRUE" ;
VAL_ 1276 Sig1250 0 "FALSE" 1 "TRUE" ;
VAL_ 1275 Sig1294 0 "FALSE" 1 "TRUE" ;
VAL_ 1275 Sig1296 0 "Not Supported" 1 "Type A" 2 "Type B" 3 "Type C" ;
VAL_ 1275 Sig1305 0 "FALSE" 1 "TRUE" ;
VAL_ 1275 Sig1304 0 "FALSE" 1 "TRUE" ;
VAL_ 1275 Sig1303 0 "FALSE" 1 "TRUE" ;
VAL_ 1275 Sig1302 0 "FALSE" 1 "TRUE" ;
VAL_ 1275 Sig1301 0 "FALSE" 1 "TRUE" ;
VAL_ 1275 Sig1300 0 "FALSE" 1 "TRUE" ;
VAL_ 1275 Sig1299 0 "FALSE" 1 "TRUE" ;
VAL_ 1275 Sig1307 0 "FALSE" 1 "TRUE" ;
VAL_ 1275 Sig1306 0 "FALSE" 1 "TRUE" ;
VAL_ 1274 DTCI_DMS_CnfrmdDTC 0 "FALSE" 1 "TRUE" ;
VAL_ 1274 DTCI_DMS_DTCFaultType 0 "Not Supported" 1 "Type A" 2 "Type B" 3 "Type C" ;
VAL_ 1274 DTCI_DMS_TstNCmpltdOpCyc 0 "FALSE" 1 "TRUE" ;
VAL_ 1274 DTCI_DMS_TstNCmpltdLstClr 0 "FALSE" 1 "TRUE" ;
VAL_ 1274 DTCI_DMS_TstFldOpCyc 0 "FALSE" 1 "TRUE" ;
VAL_ 1274 DTCI_DMS_TstFldLstClr 0 "FALSE" 1 "TRUE" ;
VAL_ 1274 DTCI_DMS_TstFld 0 "FALSE" 1 "TRUE" ;
VAL_ 1274 DTCI_DMS_PndngDTC 0 "FALSE" 1 "TRUE" ;
VAL_ 1274 DTCI_DMS_DTCTriggered 0 "FALSE" 1 "TRUE" ;
VAL_ 1274 DTCI_DMS_WrnIndTrggrd 0 "FALSE" 1 "TRUE" ;
VAL_ 1274 DTCI_DMS_WrnIndRqd 0 "FALSE" 1 "TRUE" ;
VAL_ 1792 Sig1308 0 "FALSE" 1 "TRUE" ;
VAL_ 1792 Sig1310 0 "Not Supported" 1 "Type A" 2 "Type B" 3 "Type C" ;
VAL_ 1792 Sig1319 0 "FALSE" 1 "TRUE" ;
VAL_ 1792 Sig1318 0 "FALSE" 1 "TRUE" ;
VAL_ 1792 Sig1317 0 "FALSE" 1 "TRUE" ;
VAL_ 1792 Sig1316 0 "FALSE" 1 "TRUE" ;
VAL_ 1792 Sig1315 0 "FALSE" 1 "TRUE" ;
VAL_ 1792 Sig1314 0 "FALSE" 1 "TRUE" ;
VAL_ 1792 Sig1313 0 "FALSE" 1 "TRUE" ;
VAL_ 1792 Sig1321 0 "FALSE" 1 "TRUE" ;
VAL_ 1792 Sig1320 0 "FALSE" 1 "TRUE" ;
VAL_ 1793 DTCI_ECP_E_CnfrmdDTC 0 "FALSE" 1 "TRUE" ;
VAL_ 1793 DTCI_ECP_E_DTCFaultType 0 "Not Supported" 1 "Type A" 2 "Type B" 3 "Type C" ;
VAL_ 1793 DTCI_ECP_E_TstNCmpltdOpCyc 0 "FALSE" 1 "TRUE" ;
VAL_ 1793 DTCI_ECP_E_TstNCmpltdLstClr 0 "FALSE" 1 "TRUE" ;
VAL_ 1793 DTCI_ECP_E_TstFldOpCyc 0 "FALSE" 1 "TRUE" ;
VAL_ 1793 DTCI_ECP_E_TstFldLstClr 0 "FALSE" 1 "TRUE" ;
VAL_ 1793 DTCI_ECP_E_TstFld 0 "FALSE" 1 "TRUE" ;
VAL_ 1793 DTCI_ECP_E_PndngDTC 0 "FALSE" 1 "TRUE" ;
VAL_ 1793 DTCI_ECP_E_DTCTriggered 0 "FALSE" 1 "TRUE" ;
VAL_ 1793 DTCI_ECP_E_WrnIndTrggrd 0 "FALSE" 1 "TRUE" ;
VAL_ 1793 DTCI_ECP_E_WrnIndRqd 0 "FALSE" 1 "TRUE" ;
VAL_ 1272 Sig1322 0 "FALSE" 1 "TRUE" ;
VAL_ 1272 Sig1324 0 "Not Supported" 1 "Type A" 2 "Type B" 3 "Type C" ;
VAL_ 1272 Sig1333 0 "FALSE" 1 "TRUE" ;
VAL_ 1272 Sig1332 0 "FALSE" 1 "TRUE" ;
VAL_ 1272 Sig1331 0 "FALSE" 1 "TRUE" ;
VAL_ 1272 Sig1330 0 "FALSE" 1 "TRUE" ;
VAL_ 1272 Sig1329 0 "FALSE" 1 "TRUE" ;
VAL_ 1272 Sig1328 0 "FALSE" 1 "TRUE" ;
VAL_ 1272 Sig1327 0 "FALSE" 1 "TRUE" ;
VAL_ 1272 Sig1335 0 "FALSE" 1 "TRUE" ;
VAL_ 1272 Sig1334 0 "FALSE" 1 "TRUE" ;
VAL_ 1273 Sig1336 0 "FALSE" 1 "TRUE" ;
VAL_ 1273 Sig1338 0 "Not Supported" 1 "Type A" 2 "Type B" 3 "Type C" ;
VAL_ 1273 Sig1347 0 "FALSE" 1 "TRUE" ;
VAL_ 1273 Sig1346 0 "FALSE" 1 "TRUE" ;
VAL_ 1273 Sig1345 0 "FALSE" 1 "TRUE" ;
VAL_ 1273 Sig1344 0 "FALSE" 1 "TRUE" ;
VAL_ 1273 Sig1343 0 "FALSE" 1 "TRUE" ;
VAL_ 1273 Sig1342 0 "FALSE" 1 "TRUE" ;
VAL_ 1273 Sig1341 0 "FALSE" 1 "TRUE" ;
VAL_ 1273 Sig1349 0 "FALSE" 1 "TRUE" ;
VAL_ 1273 Sig1348 0 "FALSE" 1 "TRUE" ;
VAL_ 1794 Sig1350 0 "FALSE" 1 "TRUE" ;
VAL_ 1794 Sig1352 0 "Not Supported" 1 "Type A" 2 "Type B" 3 "Type C" ;
VAL_ 1794 Sig1361 0 "FALSE" 1 "TRUE" ;
VAL_ 1794 Sig1360 0 "FALSE" 1 "TRUE" ;
VAL_ 1794 Sig1359 0 "FALSE" 1 "TRUE" ;
VAL_ 1794 Sig1358 0 "FALSE" 1 "TRUE" ;
VAL_ 1794 Sig1357 0 "FALSE" 1 "TRUE" ;
VAL_ 1794 Sig1356 0 "FALSE" 1 "TRUE" ;
VAL_ 1794 Sig1355 0 "FALSE" 1 "TRUE" ;
VAL_ 1794 Sig1363 0 "FALSE" 1 "TRUE" ;
VAL_ 1794 Sig1362 0 "FALSE" 1 "TRUE" ;
VAL_ 1271 Sig1364 0 "FALSE" 1 "TRUE" ;
VAL_ 1271 Sig1366 0 "Not Supported" 1 "Type A" 2 "Type B" 3 "Type C" ;
VAL_ 1271 Sig1375 0 "FALSE" 1 "TRUE" ;
VAL_ 1271 Sig1374 0 "FALSE" 1 "TRUE" ;
VAL_ 1271 Sig1373 0 "FALSE" 1 "TRUE" ;
VAL_ 1271 Sig1372 0 "FALSE" 1 "TRUE" ;
VAL_ 1271 Sig1371 0 "FALSE" 1 "TRUE" ;
VAL_ 1271 Sig1370 0 "FALSE" 1 "TRUE" ;
VAL_ 1271 Sig1369 0 "FALSE" 1 "TRUE" ;
VAL_ 1271 Sig1377 0 "FALSE" 1 "TRUE" ;
VAL_ 1271 Sig1376 0 "FALSE" 1 "TRUE" ;
VAL_ 1795 Sig1398 0 "FALSE" 1 "TRUE" ;
VAL_ 1795 Sig1400 0 "Not Supported" 1 "Type A" 2 "Type B" 3 "Type C" ;
VAL_ 1795 Sig1409 0 "FALSE" 1 "TRUE" ;
VAL_ 1795 Sig1408 0 "FALSE" 1 "TRUE" ;
VAL_ 1795 Sig1407 0 "FALSE" 1 "TRUE" ;
VAL_ 1795 Sig1406 0 "FALSE" 1 "TRUE" ;
VAL_ 1795 Sig1405 0 "FALSE" 1 "TRUE" ;
VAL_ 1795 Sig1404 0 "FALSE" 1 "TRUE" ;
VAL_ 1795 Sig1403 0 "FALSE" 1 "TRUE" ;
VAL_ 1795 Sig1411 0 "FALSE" 1 "TRUE" ;
VAL_ 1795 Sig1410 0 "FALSE" 1 "TRUE" ;
VAL_ 1270 DTCI_EPS_CnfrmdDTC 0 "FALSE" 1 "TRUE" ;
VAL_ 1270 DTCI_EPS_DTCFaultType 0 "Not Supported" 1 "Type A" 2 "Type B" 3 "Type C" ;
VAL_ 1270 DTCI_EPS_TstNCmpltdOpCyc 0 "FALSE" 1 "TRUE" ;
VAL_ 1270 DTCI_EPS_TstNCmpltdLstClr 0 "FALSE" 1 "TRUE" ;
VAL_ 1270 DTCI_EPS_TstFldOpCyc 0 "FALSE" 1 "TRUE" ;
VAL_ 1270 DTCI_EPS_TstFldLstClr 0 "FALSE" 1 "TRUE" ;
VAL_ 1270 DTCI_EPS_TstFld 0 "FALSE" 1 "TRUE" ;
VAL_ 1270 DTCI_EPS_PndngDTC 0 "FALSE" 1 "TRUE" ;
VAL_ 1270 DTCI_EPS_DTCTriggered 0 "FALSE" 1 "TRUE" ;
VAL_ 1270 DTCI_EPS_WrnIndTrggrd 0 "FALSE" 1 "TRUE" ;
VAL_ 1270 DTCI_EPS_WrnIndRqd 0 "FALSE" 1 "TRUE" ;
VAL_ 1796 Sig1448 0 "FALSE" 1 "TRUE" ;
VAL_ 1796 Sig1450 0 "Not Supported" 1 "Type A" 2 "Type B" 3 "Type C" ;
VAL_ 1796 Sig1459 0 "FALSE" 1 "TRUE" ;
VAL_ 1796 Sig1458 0 "FALSE" 1 "TRUE" ;
VAL_ 1796 Sig1457 0 "FALSE" 1 "TRUE" ;
VAL_ 1796 Sig1456 0 "FALSE" 1 "TRUE" ;
VAL_ 1796 Sig1455 0 "FALSE" 1 "TRUE" ;
VAL_ 1796 Sig1454 0 "FALSE" 1 "TRUE" ;
VAL_ 1796 Sig1453 0 "FALSE" 1 "TRUE" ;
VAL_ 1796 Sig1461 0 "FALSE" 1 "TRUE" ;
VAL_ 1796 Sig1460 0 "FALSE" 1 "TRUE" ;
VAL_ 1269 Sig1462 0 "FALSE" 1 "TRUE" ;
VAL_ 1269 Sig1464 0 "Not Supported" 1 "Type A" 2 "Type B" 3 "Type C" ;
VAL_ 1269 Sig1487 0 "FALSE" 1 "TRUE" ;
VAL_ 1269 Sig1486 0 "FALSE" 1 "TRUE" ;
VAL_ 1269 Sig1485 0 "FALSE" 1 "TRUE" ;
VAL_ 1269 Sig1484 0 "FALSE" 1 "TRUE" ;
VAL_ 1269 Sig1483 0 "FALSE" 1 "TRUE" ;
VAL_ 1269 Sig1482 0 "FALSE" 1 "TRUE" ;
VAL_ 1269 Sig1467 0 "FALSE" 1 "TRUE" ;
VAL_ 1269 Sig1489 0 "FALSE" 1 "TRUE" ;
VAL_ 1269 Sig1488 0 "FALSE" 1 "TRUE" ;
VAL_ 1797 Sig1490 0 "FALSE" 1 "TRUE" ;
VAL_ 1797 Sig1492 0 "Not Supported" 1 "Type A" 2 "Type B" 3 "Type C" ;
VAL_ 1797 Sig1501 0 "FALSE" 1 "TRUE" ;
VAL_ 1797 Sig1500 0 "FALSE" 1 "TRUE" ;
VAL_ 1797 Sig1499 0 "FALSE" 1 "TRUE" ;
VAL_ 1797 Sig1498 0 "FALSE" 1 "TRUE" ;
VAL_ 1797 Sig1497 0 "FALSE" 1 "TRUE" ;
VAL_ 1797 Sig1496 0 "FALSE" 1 "TRUE" ;
VAL_ 1797 Sig1495 0 "FALSE" 1 "TRUE" ;
VAL_ 1797 Sig1503 0 "FALSE" 1 "TRUE" ;
VAL_ 1797 Sig1502 0 "FALSE" 1 "TRUE" ;
VAL_ 1025 Sig1518 0 "FALSE" 1 "TRUE" ;
VAL_ 1025 Sig1520 0 "Not Supported" 1 "Type A" 2 "Type B" 3 "Type C" ;
VAL_ 1025 Sig1529 0 "FALSE" 1 "TRUE" ;
VAL_ 1025 Sig1528 0 "FALSE" 1 "TRUE" ;
VAL_ 1025 Sig1527 0 "FALSE" 1 "TRUE" ;
VAL_ 1025 Sig1526 0 "FALSE" 1 "TRUE" ;
VAL_ 1025 Sig1525 0 "FALSE" 1 "TRUE" ;
VAL_ 1025 Sig1524 0 "FALSE" 1 "TRUE" ;
VAL_ 1025 Sig1523 0 "FALSE" 1 "TRUE" ;
VAL_ 1025 Sig1531 0 "FALSE" 1 "TRUE" ;
VAL_ 1025 Sig1530 0 "FALSE" 1 "TRUE" ;
VAL_ 1268 Sig1602 0 "FALSE" 1 "TRUE" ;
VAL_ 1268 Sig1604 0 "Not Supported" 1 "Type A" 2 "Type B" 3 "Type C" ;
VAL_ 1268 Sig1613 0 "FALSE" 1 "TRUE" ;
VAL_ 1268 Sig1612 0 "FALSE" 1 "TRUE" ;
VAL_ 1268 Sig1611 0 "FALSE" 1 "TRUE" ;
VAL_ 1268 Sig1610 0 "FALSE" 1 "TRUE" ;
VAL_ 1268 Sig1609 0 "FALSE" 1 "TRUE" ;
VAL_ 1268 Sig1608 0 "FALSE" 1 "TRUE" ;
VAL_ 1268 Sig1607 0 "FALSE" 1 "TRUE" ;
VAL_ 1268 Sig1615 0 "FALSE" 1 "TRUE" ;
VAL_ 1268 Sig1614 0 "FALSE" 1 "TRUE" ;
VAL_ 1798 Sig1784 0 "FALSE" 1 "TRUE" ;
VAL_ 1798 Sig1786 0 "Not Supported" 1 "Type A" 2 "Type B" 3 "Type C" ;
VAL_ 1798 Sig1795 0 "FALSE" 1 "TRUE" ;
VAL_ 1798 Sig1794 0 "FALSE" 1 "TRUE" ;
VAL_ 1798 Sig1793 0 "FALSE" 1 "TRUE" ;
VAL_ 1798 Sig1792 0 "FALSE" 1 "TRUE" ;
VAL_ 1798 Sig1791 0 "FALSE" 1 "TRUE" ;
VAL_ 1798 Sig1790 0 "FALSE" 1 "TRUE" ;
VAL_ 1798 Sig1789 0 "FALSE" 1 "TRUE" ;
VAL_ 1798 Sig1797 0 "FALSE" 1 "TRUE" ;
VAL_ 1798 Sig1796 0 "FALSE" 1 "TRUE" ;
VAL_ 1173 Sig1812 0 "FALSE" 1 "TRUE" ;
VAL_ 1173 Sig1814 0 "Not Supported" 1 "Type A" 2 "Type B" 3 "Type C" ;
VAL_ 1173 Sig1823 0 "FALSE" 1 "TRUE" ;
VAL_ 1173 Sig1822 0 "FALSE" 1 "TRUE" ;
VAL_ 1173 Sig1821 0 "FALSE" 1 "TRUE" ;
VAL_ 1173 Sig1820 0 "FALSE" 1 "TRUE" ;
VAL_ 1173 Sig1819 0 "FALSE" 1 "TRUE" ;
VAL_ 1173 Sig1818 0 "FALSE" 1 "TRUE" ;
VAL_ 1173 Sig1817 0 "FALSE" 1 "TRUE" ;
VAL_ 1173 Sig1825 0 "FALSE" 1 "TRUE" ;
VAL_ 1173 Sig1824 0 "FALSE" 1 "TRUE" ;
VAL_ 1267 Sig1868 0 "FALSE" 1 "TRUE" ;
VAL_ 1267 Sig1870 0 "Not Supported" 1 "Type A" 2 "Type B" 3 "Type C" ;
VAL_ 1267 Sig1879 0 "FALSE" 1 "TRUE" ;
VAL_ 1267 Sig1878 0 "FALSE" 1 "TRUE" ;
VAL_ 1267 Sig1877 0 "FALSE" 1 "TRUE" ;
VAL_ 1267 Sig1876 0 "FALSE" 1 "TRUE" ;
VAL_ 1267 Sig1875 0 "FALSE" 1 "TRUE" ;
VAL_ 1267 Sig1874 0 "FALSE" 1 "TRUE" ;
VAL_ 1267 Sig1873 0 "FALSE" 1 "TRUE" ;
VAL_ 1267 Sig1881 0 "FALSE" 1 "TRUE" ;
VAL_ 1267 Sig1880 0 "FALSE" 1 "TRUE" ;
VAL_ 1799 Sig2162 0 "FALSE" 1 "TRUE" ;
VAL_ 1799 Sig2164 0 "Not Supported" 1 "Type A" 2 "Type B" 3 "Type C" ;
VAL_ 1799 Sig2173 0 "FALSE" 1 "TRUE" ;
VAL_ 1799 Sig2172 0 "FALSE" 1 "TRUE" ;
VAL_ 1799 Sig2171 0 "FALSE" 1 "TRUE" ;
VAL_ 1799 Sig2170 0 "FALSE" 1 "TRUE" ;
VAL_ 1799 Sig2169 0 "FALSE" 1 "TRUE" ;
VAL_ 1799 Sig2168 0 "FALSE" 1 "TRUE" ;
VAL_ 1799 Sig2167 0 "FALSE" 1 "TRUE" ;
VAL_ 1799 Sig2175 0 "FALSE" 1 "TRUE" ;
VAL_ 1799 Sig2174 0 "FALSE" 1 "TRUE" ;
VAL_ 1266 Sig2176 0 "FALSE" 1 "TRUE" ;
VAL_ 1266 Sig2178 0 "Not Supported" 1 "Type A" 2 "Type B" 3 "Type C" ;
VAL_ 1266 Sig2187 0 "FALSE" 1 "TRUE" ;
VAL_ 1266 Sig2186 0 "FALSE" 1 "TRUE" ;
VAL_ 1266 Sig2185 0 "FALSE" 1 "TRUE" ;
VAL_ 1266 Sig2184 0 "FALSE" 1 "TRUE" ;
VAL_ 1266 Sig2183 0 "FALSE" 1 "TRUE" ;
VAL_ 1266 Sig2182 0 "FALSE" 1 "TRUE" ;
VAL_ 1266 Sig2181 0 "FALSE" 1 "TRUE" ;
VAL_ 1266 Sig2189 0 "FALSE" 1 "TRUE" ;
VAL_ 1266 Sig2188 0 "FALSE" 1 "TRUE" ;
VAL_ 1473 Sig2246 0 "FALSE" 1 "TRUE" ;
VAL_ 1473 Sig2248 0 "Not Supported" 1 "Type A" 2 "Type B" 3 "Type C" ;
VAL_ 1473 Sig2257 0 "FALSE" 1 "TRUE" ;
VAL_ 1473 Sig2256 0 "FALSE" 1 "TRUE" ;
VAL_ 1473 Sig2255 0 "FALSE" 1 "TRUE" ;
VAL_ 1473 Sig2254 0 "FALSE" 1 "TRUE" ;
VAL_ 1473 Sig2253 0 "FALSE" 1 "TRUE" ;
VAL_ 1473 Sig2252 0 "FALSE" 1 "TRUE" ;
VAL_ 1473 Sig2251 0 "FALSE" 1 "TRUE" ;
VAL_ 1473 Sig2259 0 "FALSE" 1 "TRUE" ;
VAL_ 1473 Sig2258 0 "FALSE" 1 "TRUE" ;
VAL_ 1474 Sig2260 0 "FALSE" 1 "TRUE" ;
VAL_ 1474 Sig2262 0 "Not Supported" 1 "Type A" 2 "Type B" 3 "Type C" ;
VAL_ 1474 Sig2271 0 "FALSE" 1 "TRUE" ;
VAL_ 1474 Sig2270 0 "FALSE" 1 "TRUE" ;
VAL_ 1474 Sig2269 0 "FALSE" 1 "TRUE" ;
VAL_ 1474 Sig2268 0 "FALSE" 1 "TRUE" ;
VAL_ 1474 Sig2267 0 "FALSE" 1 "TRUE" ;
VAL_ 1474 Sig2266 0 "FALSE" 1 "TRUE" ;
VAL_ 1474 Sig2265 0 "FALSE" 1 "TRUE" ;
VAL_ 1474 Sig2273 0 "FALSE" 1 "TRUE" ;
VAL_ 1474 Sig2272 0 "FALSE" 1 "TRUE" ;
VAL_ 1800 DTCI_VICM_CnfrmdDTC 0 "FALSE" 1 "TRUE" ;
VAL_ 1800 DTCI_VICM_DTCFaultType 0 "Not Supported" 1 "Type A" 2 "Type B" 3 "Type C" ;
VAL_ 1800 DTCI_VICM_TstNCmpltdOpCyc 0 "FALSE" 1 "TRUE" ;
VAL_ 1800 DTCI_VICM_TstNCmpltdLstClr 0 "FALSE" 1 "TRUE" ;
VAL_ 1800 DTCI_VICM_TstFldOpCyc 0 "FALSE" 1 "TRUE" ;
VAL_ 1800 DTCI_VICM_TstFldLstClr 0 "FALSE" 1 "TRUE" ;
VAL_ 1800 DTCI_VICM_TstFld 0 "FALSE" 1 "TRUE" ;
VAL_ 1800 DTCI_VICM_PndngDTC 0 "FALSE" 1 "TRUE" ;
VAL_ 1800 DTCI_VICM_DTCTriggered 0 "FALSE" 1 "TRUE" ;
VAL_ 1800 DTCI_VICM_WrnIndTrggrd 0 "FALSE" 1 "TRUE" ;
VAL_ 1800 DTCI_VICM_WrnIndRqd 0 "FALSE" 1 "TRUE" ;
VAL_ 872 Sig0722 0 "FALSE" 1 "TRUE" ;
VAL_ 872 Sig0721 0 "FALSE" 1 "TRUE" ;
VAL_ 872 Sig0716 0 "No Indication" 1 "Two Wheel Drive High Pending" 2 "Two Wheel Drive High Active" 3 "Four Wheel Drive High Auto Pending" 4 "Four Wheel Drive High Auto Active" 5 "Four Wheel Drive High Lock Pending" 6 "Four Wheel Drive High Lock Active" 7 "Four Wheel Drive Low Lock Pending" 8 "Four Wheel Drive Low Lock Active" 9 "Transfer Case Neutral Pending" 10 "Transfer Case Neutral Active" 11 "Position Undetermined Active" 12 "AWD Connected Mode Pending" 13 "AWD Connected Mode Active" 14 "Front Wheel Drive Mode Pending" 15 "Front Wheel Drive Mode Active" ;
VAL_ 186 DMSIP_DrvrAttnStatAuth 0 "Unknown" 1 "Attention is On Road" 2 "Attention is Off Road" 3 "Attention is Driver's Lap" 4 "Attention is Center Console / Radio" 5 "Driver\???s Eyes Fully Closed" 6 "Driver Window / Mirror" 7 "Passenger Window / Mirror" 8 "Rear View Mirror" 9 "Overhead Console" 10 "No Driver" 11 "Front IPC" ;
VAL_ 186 DMSDrvrAttnStatCnfdLvlAuth 0 "0" 1 "1" 2 "2" 3 "3" 4 "4" 5 "5" 6 "6" 7 "7" ;
VAL_ 186 DMSDrvrAttnStatAlgTypAuth 0 "Eye Gaze Used" 1 "Head Pose Used" ;
VAL_ 186 DMSIP_DrvrAttnStatAuth_Inv 0 "FALSE" 1 "TRUE" ;
VAL_ 186 DMSOpStatAuth 0 "Unknown" 1 "Initializing" 2 "Internal Fault" 3 "External Fault" 4 "Invalid Environment" 5 "Active" 6 "IR Emitter OFF" ;
VAL_ 624 TBI2P_TrlrBrkgManAppAtvAuth 0 "FALSE" 1 "TRUE" ;
VAL_ 624 BSAE44BP_AE44BrkgStsAuth 0 "Standby" 1 "Ready" 2 "Active Hold" 3 "Active Control" 4 "Finished Hold" 5 "Failed" ;
VAL_ 624 WRDSP_RFAuth 0 "Unknown" 1 "Not Supported" 2 "Invalid" 3 "Forward" 4 "Reverse" ;
VAL_ 624 WRDSP_LRAuth 0 "Unknown" 1 "Not Supported" 2 "Invalid" 3 "Forward" 4 "Reverse" ;
VAL_ 624 WRDSP_LFAuth 0 "Unknown" 1 "Not Supported" 2 "Invalid" 3 "Forward" 4 "Reverse" ;
VAL_ 624 VAP_ActlVehAccelAuth_Inv 0 "FALSE" 1 "TRUE" ;
VAL_ 624 SuprRmtPrkBrkResp 0 "Unavailable" 1 "Available" 2 "Active Hold" 3 "Active Control" 4 "Failed" ;
VAL_ 624 WRDSP_RRAuth 0 "Unknown" 1 "Not Supported" 2 "Invalid" 3 "Forward" 4 "Reverse" ;
VAL_ 2147745840 Sig2467 0 "FALSE" 1 "TRUE" ;
VAL_ 2147745795 EBCM_AV_CAN2_ClscCANHrtBtActv 0 "FALSE" 1 "TRUE" ;
VAL_ 2147745796 EBCM_CAN2_ClscCANHrtBtActv 0 "FALSE" 1 "TRUE" ;
VAL_ 1445 CustmStbCtlRdctReqConf 0 "No Action" 1 "No" 2 "Yes" ;
VAL_ 1413 TrlrConnStat 0 "Not Connected" 1 "Connected" ;
VAL_ 707 EGI5_Eng12vStrtrMtrCmmdOn 0 "FALSE" 1 "TRUE" ;
VAL_ 2147745800 Sig2502 0 "FALSE" 1 "TRUE" ;
VAL_ 2147745801 ECP_E_CAN2_ClscCANHrtBtActv 0 "FALSE" 1 "TRUE" ;
VAL_ 2147745816 Sig2506 0 "FALSE" 1 "TRUE" ;
VAL_ 2147745815 Sig2507 0 "FALSE" 1 "TRUE" ;
VAL_ 2147745802 Sig2509 0 "FALSE" 1 "TRUE" ;
VAL_ 2147745803 Sig2511 0 "FALSE" 1 "TRUE" ;
VAL_ 86 ELSDIP_ActrStsAuth 0 "Normal" 1 "Temporary Inhibit" 2 "Temporary Limited" 3 "Permanently Failed" 4 "UnKnown" ;
VAL_ 528 FIMRIMABP_FIMCISAutBrkRqTypAuth 0 "None" 1 "Brake to Commanded Decel" 2 "Hold" ;
VAL_ 528 FIMRIMABP_BrkgReqAuth 0 "FALSE" 1 "TRUE" ;
VAL_ 528 RIMATRP_TrqRqstActAuth 0 "FALSE" 1 "TRUE" ;
VAL_ 528 FIMRIMABP_ReqActvAuth 0 "FALSE" 1 "TRUE" ;
VAL_ 528 FIMRIMABP_RIMAutoBrkgReqTypAuth 0 "None" 1 "Hold" ;
VAL_ 2147745797 Sig2535 0 "FALSE" 1 "TRUE" ;
VAL_ 2147745798 Sig2538 0 "FALSE" 1 "TRUE" ;
VAL_ 2147745819 Sig2542 0 "FALSE" 1 "TRUE" ;
VAL_ 2147745817 EPS_CAN2_ClscCANHrtBtActv 0 "FALSE" 1 "TRUE" ;
VAL_ 2147745818 Sig2546 0 "FALSE" 1 "TRUE" ;
VAL_ 871 ESRSDP_ElecShftRngSecDispAuth 0 "No Display" 1 "Park Nominal" 2 "Reverse Nominal" 3 "Neutral Nominal" 4 "Drive Nominal" 5 "Low Nominal" 6 "Manual Nominal" 7 "Park Requested And In Progress" 8 "Reverse Requested And In Progress" 9 "Neutral Requested And In Progress" 10 "Drive Requested And In Progress" 11 "Manual Requested And In Progress" 12 "Park Requested And Denied" ;
VAL_ 869 ESVTSP_EnhdSrvsVhTpSpLimReqAuth 0 "No Action" 1 "Active" 2 "Inactive" ;
VAL_ 1507 EHCCI_HtrCoreCoolFlwRtFdbk_Inv 0 "FALSE" 1 "TRUE" ;
VAL_ 1507 EHCCI_HtrCoreInCoolTemp_Inv 0 "FALSE" 1 "TRUE" ;
VAL_ 1507 EHCCI_HtrCoreOutCoolTemp_Inv 0 "FALSE" 1 "TRUE" ;
VAL_ 1507 HtrCoreCoolMinFlwrtArbdReq_Inv 0 "FALSE" 1 "TRUE" ;
VAL_ 1324 ELWWIP_CHMSLCmdAuth 0 "No_Action" 1 "Off" 2 "On" 3 "Emergency_Brake_Flashing" ;
VAL_ 1324 ELWWIP_BrkLmpRtCmdAuth 0 "No_Action" 1 "Off" 2 "On" 3 "Emergency_Brake_Flashing" 4 "Police_Flashing" ;
VAL_ 1324 ELWWIP_BrkLmpLtCmdAuth 0 "No_Action" 1 "Off" 2 "On" 3 "Emergency_Brake_Flashing" 4 "Police_Flashing" ;
VAL_ 1324 ELWWIP_LoBmLtCmdAuth 0 "No_Request" 1 "Off" 2 "On" 3 "DRL_Intensity" 4 "Flashing" 5 "Alternate_Flashing" ;
VAL_ 1324 ELWWIP_HiBmRtCmdAuth 0 "No_Request" 1 "Off" 2 "On" 3 "DRL_Intensity" 4 "Flashing" 5 "Alternate_Flashing" ;
VAL_ 1324 ELWWIP_HiBmLtCmdAuth 0 "No_Request" 1 "Off" 2 "On" 3 "DRL_Intensity" 4 "Flashing" 5 "Alternate_Flashing" ;
VAL_ 1324 ELWWIP_TrlrRvrsLmpsCmdAuth 0 "Off" 1 "On" 2 "Flashing" ;
VAL_ 1324 ELWWIP_RvrsLmpCmdAuth 0 "Off" 1 "On" 2 "Flashing" ;
VAL_ 1324 ELWWIP_LoBmRtCmdAuth 0 "No_Request" 1 "Off" 2 "On" 3 "DRL_Intensity" 4 "Flashing" 5 "Alternate_Flashing" ;
VAL_ 1324 ELWWIP_WshFrtRrDrvCmdAuth 0 "No Front Rear Wash" 1 "Front Wash" 2 "Rear Wash" 3 "Front Rear Wash" ;
VAL_ 1324 ELWWIP_WprFrtFtrReqAuth 0 "Wiper Front Stop" 1 "Wiper Front Crank Suspend" 2 "Wiper Front Depressed Park" 3 "Wiper Front Park" 4 "Wiper Front Winter Park" 5 "Wiper Front Service Park" 6 "Wiper Front Intermittent 5" 7 "Wiper Front Intermittent 4" 8 "Wiper Front Intermittent 3" 9 "Wiper Front Intermittent 2" 10 "Wiper Front Intermittent 1" 11 "Wiper Front Low Wipe" 12 "Wiper Front High Wipe" ;
VAL_ 2147745820 Sig3206 0 "FALSE" 1 "TRUE" ;
VAL_ 2147745804 Sig3257 0 "FALSE" 1 "TRUE" ;
VAL_ 611 Sig3242 0 "Derating Level 0" 1 "Derating Level 1" 2 "Derating Level 2" 3 "Derating Level 3" 4 "Derating Level 4" 5 "Derating Level 5" ;
VAL_ 611 Sig3241 0 "Pending" 1 "Failed" 2 "Active" 3 "Passed" ;
VAL_ 611 Sig3240 0 "Derating Level 0" 1 "Derating Level 1" 2 "Derating Level 2" 3 "Derating Level 3" 4 "Derating Level 4" 5 "Derating Level 5" ;
VAL_ 611 Sig3244 0 "Derating Level 0" 1 "Derating Level 1" 2 "Derating Level 2" 3 "Derating Level 3" 4 "Derating Level 4" 5 "Derating Level 5" ;
VAL_ 611 FOPMPI1P_FOPLdShdngReqAuth 0 "No Load Shedding" 1 "Load Shed Level 1" 2 "Load Shed Level 2" 3 "Load Shed Level 3" 4 "Load Shed Level 4" ;
VAL_ 611 Sig3243 0 "Pending" 1 "Failed" 2 "Active" 3 "Passed" ;
VAL_ 611 Sig3245 0 "Pending" 1 "Failed" 2 "Active" 3 "Passed" ;
VAL_ 1508 Sig3231 0 "FALSE" 1 "TRUE" ;
VAL_ 1508 Sig3233 0 "FALSE" 1 "TRUE" ;
